VERSION ""

NS_ :

BS_:

BU_: VCM FAS EBS APM

BO_ 1512 WSGW_Chassi_10S: 24 VCM
 SG_ PhyDiagTPM2BrkReqSig_ISig_3 : 0|168@1+ (1,0) [0|0] ""  EBS

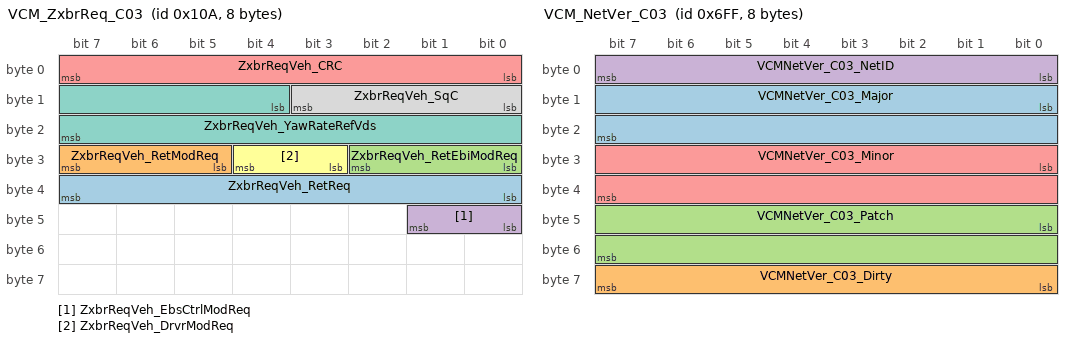
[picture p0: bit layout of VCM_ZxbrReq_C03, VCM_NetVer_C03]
BO_ 266 VCM_ZxbrReq_C03: 8 VCM
 SG_ ZxbrReqVeh_RetReq : 32|8@1+ (0.005,0) [0|1.275] "NotApplicable"  EBS
 SG_ ZxbrReqVeh_RetModReq : 29|3@1+ (1,0) [0|0] ""  EBS
 SG_ ZxbrReqVeh_RetEbiModReq : 24|3@1+ (1,0) [0|0] ""  EBS
 SG_ ZxbrReqVeh_EbsCtrlModReq : 40|2@1+ (1,0) [0|0] ""  EBS
 SG_ ZxbrReqVeh_CRC : 0|8@1+ (1,0) [0|255] ""  EBS
 SG_ ZxbrReqVeh_DrvrModReq : 27|2@1+ (1,0) [0|0] ""  EBS
 SG_ ZxbrReqVeh_YawRateRefVds : 12|12@1+ (0.001,-2) [-2|2.095] "Rad_per_s"  EBS
 SG_ ZxbrReqVeh_SqC : 8|4@1+ (1,0) [0|14] "NotApplicable"  EBS

BO_ 1791 VCM_NetVer_C03: 8 VCM
 SG_ VCMNetVer_C03_Major : 8|16@1+ (1,0) [0|65535] "Not Applicable" Vector__XXX
 SG_ VCMNetVer_C03_Dirty : 56|8@1+ (1,0) [0|255] "NotApplicable" Vector__XXX
 SG_ VCMNetVer_C03_Patch : 40|16@1+ (1,0) [0|65535] "Not Applicable" Vector__XXX
 SG_ VCMNetVer_C03_NetID : 0|8@1+ (1,0) [0|255] "NotApplicable" Vector__XXX
 SG_ VCMNetVer_C03_Minor : 24|16@1+ (1,0) [0|65535] "Not Applicable" Vector__XXX

BO_ 262 VCM_IxbrReqAx456_C03: 48 VCM
 SG_ IxbrReqAxle4_SlipCtrlEna : 41|2@1+ (1,0) [0|0] ""  EBS
 SG_ IxbrReqAxle5_SqC : 120|4@1+ (1,0) [0|14] "NotApplicable"  EBS
 SG_ IxbrReqAxle4_BrkTqReqLe : 43|13@1+ (10,0) [0|81910] "Nm"  EBS
 SG_ IxbrReqAxle4_CRC : 0|8@1+ (1,0) [0|255] ""  EBS
 SG_ IxbrReqAxle5_VehSpdLgtWhlRi : 177|13@1+ (0.01,-40) [-40|41.91] "m_per_s"  EBS
 SG_ IxbrReqAxle6_WhlSlipLimLoLe : 256|9@1+ (0.005,-1) [-1|1.555] "NotApplicable"  EBS
 SG_ IxbrReqAxle5_BrkTqReqRi : 199|13@1+ (10,0) [0|81910] "Nm"  EBS
 SG_ IxbrReqAxle4_BrkTqReqRi : 87|13@1+ (10,0) [0|81910] "Nm"  EBS
 SG_ IxbrReqAxle6_WhlSlipLimHiRi : 324|9@1+ (0.005,-1) [-1|1.555] "NotApplicable"  EBS
 SG_ IxbrReqAxle6_SqC : 232|4@1+ (1,0) [0|14] "NotApplicable"  EBS
 SG_ IxbrReqAxle5_SlipCtrlEna : 153|2@1+ (1,0) [0|0] ""  EBS
 SG_ IxbrReqAxle5_WhlSlipLimLoRi : 190|9@1+ (0.005,-1) [-1|1.555] "NotApplicable"  EBS
 SG_ IxbrReqAxle5_VehSpdLgtWhlLe : 128|13@1+ (0.01,-40) [-40|41.91] "m_per_s"  EBS
 SG_ IxbrReqAxle6_WhlSlipLimLoRi : 302|9@1+ (0.005,-1) [-1|1.555] "NotApplicable"  EBS
 SG_ IxbrReqAxle6_VehSpdLgtWhlRi : 289|13@1+ (0.01,-40) [-40|41.91] "m_per_s"  EBS
 SG_ IxbrReqAxle5_VehSpdLgtWhlQltyLe : 124|2@1+ (1,0) [0|0] ""  EBS
 SG_ IxbrReqAxle6_CRC : 224|8@1+ (1,0) [0|255] ""  EBS
 SG_ IxbrReqAxle5_CRC : 112|8@1+ (1,0) [0|255] ""  EBS
 SG_ IxbrReqAxle4_SqC : 8|4@1+ (1,0) [0|14] "NotApplicable"  EBS
 SG_ IxbrReqAxle4_VehSpdLgtWhlRi : 65|13@1+ (0.01,-40) [-40|41.91] "m_per_s"  EBS
 SG_ IxbrReqAxle4_WhlSlipLimHiLe : 56|9@1+ (0.005,-1) [-1|1.555] "NotApplicable"  EBS
 SG_ IxbrReqAxle4_VehSpdLgtWhlLe : 16|13@1+ (0.01,-40) [-40|41.91] "m_per_s"  EBS
 SG_ IxbrReqAxle4_WhlSlipLimLoLe : 32|9@1+ (0.005,-1) [-1|1.555] "NotApplicable"  EBS
 SG_ IxbrReqAxle6_VehSpdLgtWhlQltyRi : 238|2@1+ (1,0) [0|0] ""  EBS
 SG_ IxbrReqAxle6_BrkTqReqLe : 267|13@1+ (10,0) [0|81910] "Nm"  EBS
 SG_ IxbrReqAxle4_WhlSlipLimLoRi : 78|9@1+ (0.005,-1) [-1|1.555] "NotApplicable"  EBS
 SG_ IxbrReqAxle4_VehSpdLgtWhlQltyRi : 14|2@1+ (1,0) [0|0] ""  EBS
 SG_ IxbrReqAxle4_IxbrModReq : 29|3@1+ (1,0) [0|0] ""  EBS
 SG_ IxbrReqAxle6_BrkTqReqRi : 311|13@1+ (10,0) [0|81910] "Nm"  EBS
 SG_ IxbrReqAxle6_SlipCtrlEna : 265|2@1+ (1,0) [0|0] ""  EBS
 SG_ IxbrReqAxle4_VehSpdLgtWhlQltyLe : 12|2@1+ (1,0) [0|0] ""  EBS
 SG_ IxbrReqAxle6_VehSpdLgtWhlQltyLe : 236|2@1+ (1,0) [0|0] ""  EBS
 SG_ IxbrReqAxle5_BrkTqReqLe : 155|13@1+ (10,0) [0|81910] "Nm"  EBS
 SG_ IxbrReqAxle5_VehSpdLgtWhlQltyRi : 126|2@1+ (1,0) [0|0] ""  EBS
 SG_ IxbrReqAxle5_WhlSlipLimHiRi : 212|9@1+ (0.005,-1) [-1|1.555] "NotApplicable"  EBS
 SG_ IxbrReqAxle5_WhlSlipLimLoLe : 144|9@1+ (0.005,-1) [-1|1.555] "NotApplicable"  EBS
 SG_ IxbrReqAxle5_IxbrModReq : 141|3@1+ (1,0) [0|0] ""  EBS
 SG_ IxbrReqAxle4_WhlSlipLimHiRi : 100|9@1+ (0.005,-1) [-1|1.555] "NotApplicable"  EBS
 SG_ IxbrReqAxle6_IxbrModReq : 253|3@1+ (1,0) [0|0] ""  EBS
 SG_ IxbrReqAxle5_WhlSlipLimHiLe : 168|9@1+ (0.005,-1) [-1|1.555] "NotApplicable"  EBS
 SG_ IxbrReqAxle6_WhlSlipLimHiLe : 280|9@1+ (0.005,-1) [-1|1.555] "NotApplicable"  EBS
 SG_ IxbrReqAxle6_VehSpdLgtWhlLe : 240|13@1+ (0.01,-40) [-40|41.91] "m_per_s"  EBS

BO_ 261 VCM_IxbrReqAx123_C03: 48 VCM
 SG_ IxbrReqAxle3_BrkTqReqLe : 267|13@1+ (10,0) [0|81910] "Nm"  EBS
 SG_ IxbrReqAxle3_WhlSlipLimHiLe : 280|9@1+ (0.005,-1) [-1|1.555] "NotApplicable"  EBS
 SG_ IxbrReqAxle1_BrkTqReqLe : 43|13@1+ (10,0) [0|81910] "Nm"  EBS
 SG_ IxbrReqAxle2_WhlSlipLimHiRi : 212|9@1+ (0.005,-1) [-1|1.555] "NotApplicable"  EBS
 SG_ IxbrReqAxle3_WhlSlipLimLoRi : 302|9@1+ (0.005,-1) [-1|1.555] "NotApplicable"  EBS
 SG_ IxbrReqAxle1_WhlSlipLimLoLe : 32|9@1+ (0.005,-1) [-1|1.555] "NotApplicable"  EBS
 SG_ IxbrReqAxle3_BrkTqReqRi : 311|13@1+ (10,0) [0|81910] "Nm"  EBS
 SG_ IxbrReqAxle2_BrkTqReqLe : 155|13@1+ (10,0) [0|81910] "Nm"  EBS
 SG_ IxbrReqAxle1_VehSpdLgtWhlQltyRi : 14|2@1+ (1,0) [0|0] ""  EBS
 SG_ IxbrReqAxle2_BrkTqReqRi : 199|13@1+ (10,0) [0|81910] "Nm"  EBS
 SG_ IxbrReqAxle1_WhlSlipLimHiLe : 56|9@1+ (0.005,-1) [-1|1.555] "NotApplicable"  EBS
 SG_ IxbrReqAxle1_SlipCtrlEna : 41|2@1+ (1,0) [0|0] ""  EBS
 SG_ IxbrReqAxle1_WhlSlipLimLoRi : 78|9@1+ (0.005,-1) [-1|1.555] "NotApplicable"  EBS
 SG_ IxbrReqAxle2_SlipCtrlEna : 153|2@1+ (1,0) [0|0] ""  EBS
 SG_ IxbrReqAxle1_IxbrModReq : 29|3@1+ (1,0) [0|0] ""  EBS
 SG_ IxbrReqAxle1_SqC : 8|4@1+ (1,0) [0|14] "NotApplicable"  EBS
 SG_ IxbrReqAxle3_VehSpdLgtWhlQltyLe : 236|2@1+ (1,0) [0|0] ""  EBS
 SG_ IxbrReqAxle3_SqC : 232|4@1+ (1,0) [0|14] "NotApplicable"  EBS
 SG_ IxbrReqAxle2_WhlSlipLimLoRi : 190|9@1+ (0.005,-1) [-1|1.555] "NotApplicable"  EBS
 SG_ IxbrReqAxle1_WhlSlipLimHiRi : 100|9@1+ (0.005,-1) [-1|1.555] "NotApplicable"  EBS
 SG_ IxbrReqAxle2_IxbrModReq : 141|3@1+ (1,0) [0|0] ""  EBS
 SG_ IxbrReqAxle3_WhlSlipLimLoLe : 256|9@1+ (0.005,-1) [-1|1.555] "NotApplicable"  EBS
 SG_ IxbrReqAxle2_SqC : 120|4@1+ (1,0) [0|14] "NotApplicable"  EBS
 SG_ IxbrReqAxle1_VehSpdLgtWhlLe : 16|13@1+ (0.01,-40) [-40|41.91] "m_per_s"  EBS
 SG_ IxbrReqAxle3_VehSpdLgtWhlRi : 289|13@1+ (0.01,-40) [-40|41.91] "m_per_s"  EBS
 SG_ IxbrReqAxle3_WhlSlipLimHiRi : 324|9@1+ (0.005,-1) [-1|1.555] "NotApplicable"  EBS
 SG_ IxbrReqAxle2_WhlSlipLimLoLe : 144|9@1+ (0.005,-1) [-1|1.555] "NotApplicable"  EBS
 SG_ IxbrReqAxle2_VehSpdLgtWhlLe : 128|13@1+ (0.01,-40) [-40|41.91] "m_per_s"  EBS
 SG_ IxbrReqAxle2_WhlSlipLimHiLe : 168|9@1+ (0.005,-1) [-1|1.555] "NotApplicable"  EBS
 SG_ IxbrReqAxle3_VehSpdLgtWhlQltyRi : 238|2@1+ (1,0) [0|0] ""  EBS
 SG_ IxbrReqAxle1_VehSpdLgtWhlQltyLe : 12|2@1+ (1,0) [0|0] ""  EBS
 SG_ IxbrReqAxle1_BrkTqReqRi : 87|13@1+ (10,0) [0|81910] "Nm"  EBS
 SG_ IxbrReqAxle1_VehSpdLgtWhlRi : 65|13@1+ (0.01,-40) [-40|41.91] "m_per_s"  EBS
 SG_ IxbrReqAxle3_IxbrModReq : 253|3@1+ (1,0) [0|0] ""  EBS
 SG_ IxbrReqAxle2_CRC : 112|8@1+ (1,0) [0|255] ""  EBS
 SG_ IxbrReqAxle2_VehSpdLgtWhlQltyLe : 124|2@1+ (1,0) [0|0] ""  EBS
 SG_ IxbrReqAxle3_VehSpdLgtWhlLe : 240|13@1+ (0.01,-40) [-40|41.91] "m_per_s"  EBS
 SG_ IxbrReqAxle3_SlipCtrlEna : 265|2@1+ (1,0) [0|0] ""  EBS
 SG_ IxbrReqAxle3_CRC : 224|8@1+ (1,0) [0|255] ""  EBS
 SG_ IxbrReqAxle2_VehSpdLgtWhlRi : 177|13@1+ (0.01,-40) [-40|41.91] "m_per_s"  EBS
 SG_ IxbrReqAxle2_VehSpdLgtWhlQltyRi : 126|2@1+ (1,0) [0|0] ""  EBS
 SG_ IxbrReqAxle1_CRC : 0|8@1+ (1,0) [0|255] ""  EBS

BO_ 554 VCM_EstAxles_C03: 48 VCM
 SG_ EstAxle3_LoadNormLe : 128|8@1+ (800,0) [0|204000] "N"  EBS
 SG_ EstAxle6_WhlRdEstQltyRi : 294|2@1+ (1,0) [0|0] ""  EBS
 SG_ EstAxle5_WhlRdEstQltyRi : 238|2@1+ (1,0) [0|0] ""  EBS
 SG_ EstAxle2_LoadNormQltyLe : 108|2@1+ (1,0) [0|0] ""  EBS
 SG_ EstAxle3_LoadNormQltyRi : 166|2@1+ (1,0) [0|0] ""  EBS
 SG_ EstAxle6_SqC : 288|4@1+ (1,0) [0|14] "NotApplicable"  EBS
 SG_ EstAxle4_LoadNormQltyRi : 222|2@1+ (1,0) [0|0] ""  EBS
 SG_ EstAxle6_LoadNormRi : 304|8@1+ (800,0) [0|204000] "N"  EBS
 SG_ EstAxle5_SqC : 232|4@1+ (1,0) [0|14] "NotApplicable"  EBS
 SG_ EstAxle6_CRC : 280|8@1+ (1,0) [0|255] ""  EBS
 SG_ EstAxle2_WhlRdEstLe : 88|10@1+ (0.001,0.35) [0.35|1.373] "m"  EBS
 SG_ EstAxle3_WhlRdEstRi : 154|10@1+ (0.001,0.35) [0.35|1.373] "m"  EBS
 SG_ EstAxle5_LoadNormQltyRi : 278|2@1+ (1,0) [0|0] ""  EBS
 SG_ EstAxle6_WhlRdEstLe : 312|10@1+ (0.001,0.35) [0.35|1.373] "m"  EBS
 SG_ EstAxle6_WhlRdEstQltyLe : 292|2@1+ (1,0) [0|0] ""  EBS
 SG_ EstAxle6_LoadNormLe : 296|8@1+ (800,0) [0|204000] "N"  EBS
 SG_ EstAxle5_LoadNormRi : 248|8@1+ (800,0) [0|204000] "N"  EBS
 SG_ EstAxle5_LoadNormQltyLe : 276|2@1+ (1,0) [0|0] ""  EBS
 SG_ EstAxle5_CRC : 224|8@1+ (1,0) [0|255] ""  EBS
 SG_ EstAxle1_WhlRdEstRi : 42|10@1+ (0.001,0.35) [0.35|1.373] "m"  EBS
 SG_ EstAxle4_LoadNormRi : 192|8@1+ (800,0) [0|204000] "N"  EBS
 SG_ EstAxle3_WhlRdEstQltyLe : 124|2@1+ (1,0) [0|0] ""  EBS
 SG_ EstAxle4_WhlRdEstRi : 210|10@1+ (0.001,0.35) [0.35|1.373] "m"  EBS
 SG_ EstAxle6_WhlRdEstRi : 322|10@1+ (0.001,0.35) [0.35|1.373] "m"  EBS
 SG_ EstAxle5_LoadNormLe : 240|8@1+ (800,0) [0|204000] "N"  EBS
 SG_ EstAxle5_WhlRdEstLe : 256|10@1+ (0.001,0.35) [0.35|1.373] "m"  EBS
 SG_ EstAxle3_CRC : 112|8@1+ (1,0) [0|255] ""  EBS
 SG_ EstAxle2_LoadNormRi : 80|8@1+ (800,0) [0|204000] "N"  EBS
 SG_ EstAxle4_SqC : 176|4@1+ (1,0) [0|14] "NotApplicable"  EBS
 SG_ EstAxle4_WhlRdEstQltyRi : 182|2@1+ (1,0) [0|0] ""  EBS
 SG_ EstAxle6_LoadNormQltyRi : 334|2@1+ (1,0) [0|0] ""  EBS
 SG_ EstAxle1_LoadNormQltyRi : 54|2@1+ (1,0) [0|0] ""  EBS
 SG_ EstAxle1_LoadNormQltyLe : 52|2@1+ (1,0) [0|0] ""  EBS
 SG_ EstAxle2_LoadNormLe : 72|8@1+ (800,0) [0|204000] "N"  EBS
 SG_ EstAxle4_WhlRdEstQltyLe : 180|2@1+ (1,0) [0|0] ""  EBS
 SG_ EstAxle4_WhlRdEstLe : 200|10@1+ (0.001,0.35) [0.35|1.373] "m"  EBS
 SG_ EstAxle1_WhlRdEstQltyLe : 12|2@1+ (1,0) [0|0] ""  EBS
 SG_ EstAxle2_LoadNormQltyRi : 110|2@1+ (1,0) [0|0] ""  EBS
 SG_ EstAxle3_LoadNormQltyLe : 164|2@1+ (1,0) [0|0] ""  EBS
 SG_ EstAxle4_LoadNormQltyLe : 220|2@1+ (1,0) [0|0] ""  EBS
 SG_ EstAxle2_WhlRdEstQltyRi : 70|2@1+ (1,0) [0|0] ""  EBS
 SG_ EstAxle6_LoadNormQltyLe : 332|2@1+ (1,0) [0|0] ""  EBS
 SG_ EstAxle2_WhlRdEstRi : 98|10@1+ (0.001,0.35) [0.35|1.373] "m"  EBS
 SG_ EstAxle3_WhlRdEstQltyRi : 126|2@1+ (1,0) [0|0] ""  EBS
 SG_ EstAxle1_LoadNormLe : 16|8@1+ (800,0) [0|204000] "N"  EBS
 SG_ EstAxle1_CRC : 0|8@1+ (1,0) [0|255] ""  EBS
 SG_ EstAxle5_WhlRdEstRi : 266|10@1+ (0.001,0.35) [0.35|1.373] "m"  EBS
 SG_ EstAxle2_CRC : 56|8@1+ (1,0) [0|255] ""  EBS
 SG_ EstAxle1_LoadNormRi : 24|8@1+ (800,0) [0|204000] "N"  EBS
 SG_ EstAxle2_WhlRdEstQltyLe : 68|2@1+ (1,0) [0|0] ""  EBS
 SG_ EstAxle4_CRC : 168|8@1+ (1,0) [0|255] ""  EBS
 SG_ EstAxle3_LoadNormRi : 136|8@1+ (800,0) [0|204000] "N"  EBS
 SG_ EstAxle5_WhlRdEstQltyLe : 236|2@1+ (1,0) [0|0] ""  EBS
 SG_ EstAxle3_SqC : 120|4@1+ (1,0) [0|14] "NotApplicable"  EBS
 SG_ EstAxle1_WhlRdEstLe : 32|10@1+ (0.001,0.35) [0.35|1.373] "m"  EBS
 SG_ EstAxle4_LoadNormLe : 184|8@1+ (800,0) [0|204000] "N"  EBS
 SG_ EstAxle1_SqC : 8|4@1+ (1,0) [0|14] "NotApplicable"  EBS
 SG_ EstAxle1_WhlRdEstQltyRi : 14|2@1+ (1,0) [0|0] ""  EBS
 SG_ EstAxle2_SqC : 64|4@1+ (1,0) [0|14] "NotApplicable"  EBS
 SG_ EstAxle3_WhlRdEstLe : 144|10@1+ (0.001,0.35) [0.35|1.373] "m"  EBS

BO_ 631 VCM_07P_C03: 24 VCM
 SG_ TrsmEngdForPropulsion_SqC : 144|4@1+ (1,0) [0|14] "NotApplicable"  APM
 SG_ TrsmEngdForPropulsion_Status : 148|3@1+ (1,0) [0|0] ""  APM
 SG_ XPRGReqPropDemTc_SqC : 120|4@1+ (1,0) [0|14] "NotApplicable"  APM
 SG_ TrsmEngdForPropulsion_CRC : 136|8@1+ (1,0) [0|255] ""  APM
 SG_ XPRGReqPropDemTl_TlPropControl : 80|7@1+ (1,0) [0|127] "NotApplicable"  APM
 SG_ XPRGReqMain_AddVlvRelIhnibition : 101|1@1+ (1,0) [0|0] ""  APM
 SG_ XPRGReqMain_PBValveCtrl : 108|3@1+ (1,0) [0|0] ""  APM
 SG_ DriverLocation_Status_ISig_3 : 12|4@1+ (1,0) [0|0] ""  APM
 SG_ TachographVehicleSpeed : 48|16@1+ (0.00390625,0) [0|255.99609375] "Km_per_h"  APM
 SG_ XPRsystemstate : 24|8@1+ (1,0) [0|255] "NotApplicable"  EBS
 SG_ XPRGReqMain_AddValveCtrlMode : 104|1@1+ (1,0) [0|0] ""  APM
 SG_ XPRGReqMain_CRC : 88|8@1+ (1,0) [0|255] ""  APM
 SG_ XPRGReqMain_AddValveCtrl : 105|3@1+ (1,0) [0|0] ""  APM
 SG_ BacklightCmd_ISig_3 : 34|5@1+ (1,0) [0|0] ""  APM
 SG_ XPRGReqPropDemTl_SqC : 72|4@1+ (1,0) [0|14] "NotApplicable"  APM
 SG_ DoorsAjar_stat_ISig_3 : 43|3@1+ (1,0) [0|0] ""  APM
 SG_ XPRGReqPropDemTl_CRC : 64|8@1+ (1,0) [0|255] ""  APM
 SG_ XPRGReqMain_SqC : 96|4@1+ (1,0) [0|14] "NotApplicable"  APM
 SG_ XPRGReqPropDemTc_TypeControl : 124|2@1+ (1,0) [0|0] ""  APM
 SG_ CartridgeChangedDrvrReset_rqst_I : 46|2@1+ (1,0) [0|0] ""  APM
 SG_ DriverLocation_ConfidenceLvl_ISi : 16|2@1+ (1,0) [0|0] ""  APM
 SG_ DriverLocation_CRC_ISig_3 : 0|8@1+ (1,0) [0|255] ""  APM
 SG_ XPRGReqPropDemTl_TypeControl : 76|2@1+ (1,0) [0|0] ""  APM
 SG_ XPRGReqMain_RequestPriority : 102|2@1+ (1,0) [0|0] ""  APM
 SG_ XPRGReqPropDemTc_CRC : 112|8@1+ (1,0) [0|255] ""  APM
 SG_ FuncIndIlluminationLevel_ISig_3 : 40|3@1+ (1,0) [0|0] ""  APM
 SG_ TrailerABSStatus_ISig_3 : 32|2@1+ (1,0) [0|0] ""  EBS
 SG_ DriverLocation_SqC_ISig_3 : 8|4@1+ (1,0) [0|14] "NotApplicable"  APM
 SG_ XPRGReqMain_PBVlvRelInhibition : 100|1@1+ (1,0) [0|0] ""  APM
 SG_ XPRGReqPropDemTc_TcPropControl : 128|7@1+ (1,0) [0|127] "NotApplicable"  APM

BO_ 1448 VCM_06P_C03: 8 VCM
 SG_ TotalVehicleDistanceHighRes_ISig : 0|32@1+ (5,0) [0|21474836475] "m"  FAS,APM
 SG_ AmbientAirTemperature_ISig_3 : 32|16@1+ (0.03125,-273) [-273|1774.96875] "DegreeC"  FAS,APM

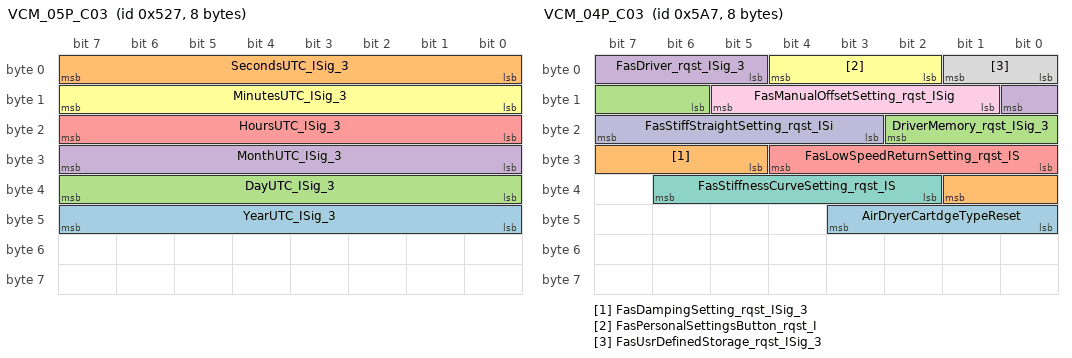
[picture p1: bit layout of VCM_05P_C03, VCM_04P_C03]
BO_ 1319 VCM_05P_C03: 8 VCM
 SG_ YearUTC_ISig_3 : 40|8@1+ (1,1985) [1985|2240] "Years"  FAS,APM
 SG_ SecondsUTC_ISig_3 : 0|8@1+ (0.25,0) [0|63.75] "s"  FAS,APM
 SG_ DayUTC_ISig_3 : 32|8@1+ (0.25,0) [0|63.75] "Days"  FAS,APM
 SG_ MonthUTC_ISig_3 : 24|8@1+ (1,0) [0|255] "Months"  APM,FAS
 SG_ HoursUTC_ISig_3 : 16|8@1+ (1,0) [0|255] "h"  APM,FAS
 SG_ MinutesUTC_ISig_3 : 8|8@1+ (1,0) [0|255] "min"  APM,FAS

BO_ 1447 VCM_04P_C03: 8 VCM
 SG_ AirDryerCartdgeTypeReset : 40|4@1+ (1,0) [0|0] ""  APM
 SG_ FasDampingSetting_rqst_ISig_3 : 29|5@1+ (1,-10) [-10|21] ""  FAS
 SG_ DriverMemory_rqst_ISig_3 : 14|5@1+ (1,0) [0|0] ""  FAS
 SG_ FasDriver_rqst_ISig_3 : 5|4@1+ (1,0) [0|0] ""  FAS
 SG_ FasLowSpeedReturnSetting_rqst_IS : 24|5@1+ (1,-10) [-10|21] ""  FAS
 SG_ FasPersonalSettingsButton_rqst_I : 2|3@1+ (1,0) [0|0] ""  FAS
 SG_ FasStiffnessCurveSetting_rqst_IS : 34|5@1+ (1,-10) [-10|21] ""  FAS
 SG_ FasUsrDefinedStorage_rqst_ISig_3 : 0|2@1+ (1,0) [0|0] ""  FAS
 SG_ FasManualOffsetSetting_rqst_ISig : 9|5@1+ (1,-10) [-10|21] ""  FAS
 SG_ FasStiffStraightSetting_rqst_ISi : 19|5@1+ (1,-10) [-10|21] ""  FAS

BO_ 1034 VCM_03P_C03: 32 VCM
 SG_ RelativeLevelFrontAxleRight_ISig : 144|16@1+ (0.1,-3200) [-3200|3353.5] "mm"  EBS
 SG_ RelativeLevelFrontAxleLeft_ISig_ : 96|16@1+ (0.1,-3200) [-3200|3353.5] "mm"  FAS,EBS
 SG_ FrontAxle1Load_ISig_3 : 0|16@1+ (0.5,0) [0|32767.5] "kg"  FAS,EBS
 SG_ PusherAxleLoad_ISig_3 : 64|16@1+ (0.5,0) [0|32767.5] "kg"  FAS,EBS
 SG_ AirConsumptionStatus : 140|2@1+ (1,0) [0|0] ""  APM
 SG_ UnloadValveOperationRqst : 142|2@1+ (1,0) [0|0] ""  APM
 SG_ SecondaryDriveAxleLoad_ISig_3 : 48|16@1+ (0.5,0) [0|32767.5] "kg"  FAS,EBS
 SG_ RelativeLevelRearAxleLeft_ISig_3 : 160|16@1+ (0.1,-3200) [-3200|3353.5] "mm"  EBS
 SG_ TagAxleLoad_ISig_3 : 80|16@1+ (0.5,0) [0|32767.5] "kg"  FAS,EBS
 SG_ TransmissionCurrentGear_ISig_3 : 208|8@1+ (1,-125) [-125|130] "GearValue"  APM
 SG_ ContTrailerBrake_MsgCounter : 136|4@1+ (1,0) [0|15] "Count"  EBS
 SG_ AirProductionPressureRangeMode : 192|4@1+ (1,0) [0|0] ""  APM
 SG_ BrakeSwitch_ISig_3 : 216|2@1+ (1,0) [0|0] ""  APM
 SG_ FrontAxle2Load_ISig_3 : 16|16@1+ (0.5,0) [0|32767.5] "kg"  FAS,EBS
 SG_ DriveAxleLoad_ISig_3 : 32|16@1+ (0.5,0) [0|32767.5] "kg"  EBS,FAS
 SG_ ContTrailerBrake_MsgChecksum : 131|5@1+ (1,0) [0|31] ""  EBS
 SG_ TertiaryDriveAxleLoad_ISig_3 : 112|16@1+ (0.5,0) [0|32767.5] "kg"  EBS
 SG_ ElAirCompActualSpeed : 200|8@1+ (20,0) [0|5100] "rpm"  APM
 SG_ ElAirCompOperationStat : 196|3@1+ (1,0) [0|0] ""  APM
 SG_ VIN_rqst_ISig_3 : 199|1@1+ (1,0) [0|0] ""  APM
 SG_ TrailerConnected_ISig_3 : 218|2@1+ (1,0) [0|0] ""  APM
 SG_ ContTrailerBrake_Request : 128|3@1+ (1,0) [0|0] ""  EBS
 SG_ RelativeLevelRearAxleRight_ISig_ : 176|16@1+ (0.1,-3200) [-3200|3353.5] "mm"  EBS

BO_ 426 VCM_02P_C03: 32 VCM
 SG_ ChangeKneelACK_ISig_3 : 126|2@1+ (1,0) [0|0] ""  EBS
 SG_ EngineSpeed_ISig_3 : 176|16@1+ (0.125,0) [0|8191.875] "rpm"  APM
 SG_ SecuredNeutralPosition_ISig_3 : 165|2@1+ (1,0) [0|0] ""  EBS,APM
 SG_ LiftAxle1PositionStatus_ISig_3 : 112|3@1+ (1,0) [0|0] ""  EBS
 SG_ FrontFerryFunctionCmd_ISig_3 : 128|3@1+ (1,0) [0|0] ""  EBS
 SG_ ReverseGearEngaged_ISig_3 : 22|2@1+ (1,0) [0|0] ""  FAS
 SG_ AirDumpStatus_ISig_3 : 104|3@1+ (1,0) [0|0] ""  EBS
 SG_ EngineActiveStatus_ISig_3 : 16|4@1+ (1,0) [0|0] ""  FAS,APM
 SG_ FerryFunctionStatus_ISig_3 : 107|3@1+ (1,0) [0|0] ""  EBS
 SG_ PitchAngleRef_ISig_3 : 56|16@1+ (0.001,-30) [-30|35.535] "deg"  EBS
 SG_ KneelingInformation_ISig_3 : 80|4@1+ (1,0) [0|0] ""  EBS
 SG_ FASHapticFeedbackRequest : 28|4@1+ (1,0) [0|0] ""  FAS
 SG_ HeightControlMode_ISig_3 : 84|4@1+ (1,0) [0|0] ""  EBS
 SG_ LoadDistributionFuncSelected_ISi : 92|4@1+ (1,0) [0|0] ""  EBS
 SG_ PitchAngle_ISig_3 : 40|16@1+ (0.001,-30) [-30|35.535] "deg"  EBS
 SG_ RollEndPositionStatus_ISig_3 : 123|3@1+ (1,0) [0|0] ""  EBS
 SG_ SupplyPressure_ISig_3 : 72|8@1+ (8,0) [0|2040] "kPa"  EBS
 SG_ WheelBasedVehicleSpeed_ISig_3 : 0|16@1+ (0.00390625,0) [0|255.99609375] "Km_per_h"  FAS,APM
 SG_ XBRSystemState2_Status : 212|2@1+ (1,0) [0|0] ""  APM
 SG_ RearAxle2DiffLock_stat_ISig_3 : 142|2@1+ (1,0) [0|0] ""  EBS
 SG_ KneelingStatusHMI_ISig_3 : 134|2@1+ (1,0) [0|0] ""  EBS
 SG_ HeightAdjustmentAllowed_ISig_3 : 110|2@1+ (1,0) [0|0] ""  EBS
 SG_ RideHeightStatus_ISig_3 : 100|4@1+ (1,0) [0|0] ""  EBS
 SG_ CentralRearDiffLock_stat_ISig_3 : 136|2@1+ (1,0) [0|0] ""  EBS
 SG_ XBRSystemState2_CRC : 200|8@1+ (1,0) [0|255] ""  APM
 SG_ LiftAxle2PositionStatus_ISig_3 : 115|3@1+ (1,0) [0|0] ""  EBS
 SG_ RampHeightOutsideTargetRange_ISi : 131|3@1+ (1,0) [0|0] ""  EBS
 SG_ DirInd_Rear_Status_ISig_3 : 160|3@1+ (1,0) [0|0] ""  EBS
 SG_ ExternalRequestManualStiffness : 32|4@1+ (0.1,0) [0|1.5] "NotApplicable"  FAS
 SG_ PneumaticTrailerBrakeStatus_ISig : 171|2@1+ (1,0) [0|0] ""  EBS
 SG_ GearLeverPosition_ISig_3 : 196|4@1+ (1,0) [0|0] ""  APM
 SG_ VehicleDistanceRollingCounter : 144|16@1+ (0.03125,0) [0|2047.96875] "m"  EBS
 SG_ BackToDriveReqACK_ISig_3 : 118|2@1+ (1,0) [0|0] ""  EBS
 SG_ XBRSystemState2_SqC : 208|4@1+ (1,0) [0|14] "NotApplicable"  APM
 SG_ ExtraAxleSteeringFunctionStat : 168|3@1+ (1,0) [0|0] ""  EBS
 SG_ RearAxle1DiffLock_stat_ISig_3 : 140|2@1+ (1,0) [0|0] ""  EBS
 SG_ LevelControlInformation_ISig_3 : 88|4@1+ (1,0) [0|0] ""  EBS
 SG_ VehicleMode_ISig_3 : 36|4@1+ (1,0) [0|0] ""  APM,FAS
 SG_ ACC_SGO_Status_ISig_3 : 24|4@1+ (1,0) [0|0] ""  FAS
 SG_ RearEndPositionStatus_ISig_3 : 120|3@1+ (1,0) [0|0] ""  EBS
 SG_ PBAlertActiveStatus_ISig_3 : 173|3@1+ (1,0) [0|0] ""  APM
 SG_ ECSShutdownCmd_ISig_3 : 138|2@1+ (1,0) [0|0] ""  EBS
 SG_ VehicleDynamicSuspProhibitStat_I : 163|2@1+ (1,0) [0|0] ""  EBS
 SG_ RideHeightFunctionStatus_ISig_3 : 96|4@1+ (1,0) [0|0] ""  EBS

BO_ 268 VCM_01P_C03: 16 VCM
 SG_ BrakePedalPosition_ISig_3 : 80|8@1+ (0.4,0) [0|102] "Percent"  APM
 SG_ RoadWheelAngle_Request : 16|16@1+ (5E-005,-1.6) [-1.6|1.67675] "rad"  FAS
 SG_ AcceleratorPedalQuality_ISig_3 : 74|2@1+ (1,0) [0|0] ""  APM
 SG_ RoadWheelAngle_RateRequest : 32|16@1+ (5E-005,-1.6) [-1.6|1.67675] "Rad_per_s"  FAS
 SG_ AcceleratorPedalStatus : 76|3@1+ (1,0) [0|0] ""  APM
 SG_ SteeringControlMode_CRC : 48|8@1+ (1,0) [0|255] ""  FAS
 SG_ SteeringControlMode_Activate : 62|2@1+ (1,0) [0|0] ""  FAS
 SG_ RoadWheelAngle_CRC : 0|8@1+ (1,0) [0|255] ""  FAS
 SG_ AcceleratorPedalPosition1_ISig_3 : 64|8@1+ (0.4,0) [0|102] "Percent"  APM
 SG_ RoadWheelAngle_SqC : 8|4@1+ (1,0) [0|14] "NotApplicable"  FAS
 SG_ AcceleratorPedalLowIdleSwitch_IS : 72|2@1+ (1,0) [0|0] ""  APM
 SG_ SteeringControlMode_SqC : 56|4@1+ (1,0) [0|14] "NotApplicable"  FAS
 SG_ SteeringControlMode_Request : 60|2@1+ (1,0) [0|0] ""  FAS

CM_ "COM_MATRIX_T3_2.3.0";
CM_ BU_ VCM "Vehicle Control Module";
CM_ BU_ FAS "Front Active Steering";
CM_ BU_ EBS "Electronic Braking System";
CM_ BU_ APM "Air Pressure Management";
BA_DEF_ BO_  "GenMsgStartDelayTime" INT 0 0;
BA_DEF_ BO_  "GenMsgDelayTime" INT 0 0;
BA_DEF_ BO_  "GenMsgCycleTime" INT 0 0;
BA_DEF_ BO_  "GenMsgSendType" ENUM  "Cyclic","NotUsed","NotUsed","NotUsed","NotUsed","NotUsed","NotUsed","IfActive","NoMsgSendType","NotUsed";
BA_DEF_ SG_  "GenSigStartValue" INT 0 0;
BA_DEF_ SG_  "GenSigCycleTimeActive" INT 0 0;
BA_DEF_ SG_  "GenSigCycleTime" INT 0 0;
BA_DEF_ SG_  "GenSigSendType" ENUM  "Cyclic","OnWrite","OnWriteWithRepetition","OnChange","OnChangeWithRepetition","IfActive","IfActiveWithRepetition","NoSigSendType","NotUsed","NotUsed","NotUsed","NotUsed","NotUsed";
BA_DEF_  "Baudrate" INT 0 1000000;
BA_DEF_  "NmType" STRING ;
BA_DEF_  "Manufacturer" STRING ;
BA_DEF_  "VersionYear" INT 0 99;
BA_DEF_  "VersionNumber" INT 0 99;
BA_DEF_  "VersionMonth" INT 1 12;
BA_DEF_  "VersionDay" INT 1 31;
BA_DEF_ BO_  "VFrameFormat" ENUM  "StandardCAN","ExtendedCAN","reserved","J1939PG","reserved","reserved","reserved","reserved","reserved","reserved","reserved","reserved","reserved","reserved","StandardCAN_FD","ExtendedCAN_FD";
BA_DEF_ BU_  "TpOwnSystemEcuNumber" HEX 0 255;
BA_DEF_ SG_  "SigType" ENUM  "Default","Range","RangeSigned","ASCII","Discrete","Control","ReferencePGN","DTC","StringDelimiter","StringLength","StringLengthControl";
BA_DEF_ BU_  "NmStationAddress" INT 0 255;
BA_DEF_  "NmAsrWaitBusSleepTime" INT 0 65535;
BA_DEF_  "NmAsrTimeoutTime" INT 0 65535;
BA_DEF_  "NmAsrRepeatMessageTime" INT 0 65535;
BA_DEF_ BU_  "NmAsrNodeIdentifier" HEX 0 253;
BA_DEF_ BU_  "NmAsrNode" ENUM  "No","Yes";
BA_DEF_  "NmAsrMessageCount" INT 1 256;
BA_DEF_ BO_  "NmAsrMessage" ENUM  "No","Yes";
BA_DEF_  "NmAsrCanMsgCycleTime" INT 0 65535;
BA_DEF_  "NmAsrBaseAddress" HEX 0 536870911;
BA_DEF_ SG_  "NeedsUpdateBit" ENUM  "No","Yes";
BA_DEF_ SG_  "MmAnSignal" ENUM  "No","Yes";
BA_DEF_ BU_  "IsOBDrelevant" ENUM  "No","Yes";
BA_DEF_ SG_  "GenSigMaxLatency" INT 0 65535;
BA_DEF_ SG_  "GenSigILSupport" ENUM  "Yes","No";
BA_DEF_ BO_  "GenMsgILSupport" ENUM  "No","Yes";
BA_DEF_ SG_  "E2EProfile" STRING ;
BA_DEF_  "E2EP05WindowSize" INT 0 65535;
BA_DEF_  "E2EP05ProfileName" STRING ;
BA_DEF_  "E2EP05MinOkStateValid" INT 0 65535;
BA_DEF_  "E2EP05MinOkStateInvalid" INT 0 65535;
BA_DEF_  "E2EP05MinOkStateInit" INT 0 65535;
BA_DEF_  "E2EP05MaxErrorStateValid" INT 0 65535;
BA_DEF_  "E2EP05MaxErrorStateInvalid" INT 0 65535;
BA_DEF_  "E2EP05MaxErrorStateInit" INT 0 65535;
BA_DEF_  "E2EP05MaxDeltaCounter" INT 0 65535;
BA_DEF_  "E2EP01WindowSize" INT 0 65535;
BA_DEF_  "E2EP01SyncCounterInit" INT 0 65535;
BA_DEF_  "E2EP01ProfileName" STRING ;
BA_DEF_  "E2EP01MinOkStateValid" INT 0 65535;
BA_DEF_  "E2EP01MinOkStateInvalid" INT 0 65535;
BA_DEF_  "E2EP01MinOkStateInit" INT 0 65535;
BA_DEF_  "E2EP01MaxNoNewOrRepeatedData" INT 0 65535;
BA_DEF_  "E2EP01MaxErrorStateValid" INT 0 65535;
BA_DEF_  "E2EP01MaxErrorStateInvalid" INT 0 65535;
BA_DEF_  "E2EP01MaxErrorStateInit" INT 0 65535;
BA_DEF_  "E2EP01MaxDeltaCounter" INT 0 65535;
BA_DEF_  "E2EP01DataIdMode" ENUM  "all16Bit","alternating8Bit","lower12Bit","lower8Bit";
BA_DEF_  "E2EP01CounterOffset" INT 0 65535;
BA_DEF_ SG_  "E2EDataLength" INT 0 65535;
BA_DEF_ SG_  "E2EDataId" INT 0 65535;
BA_DEF_ BU_  "DiagnosticClientAddress" HEX 0 255;
BA_DEF_ BO_  "DiagUUDTResponse" ENUM  "No","Yes";
BA_DEF_ BO_  "DiagState" ENUM  "No","Yes";
BA_DEF_ BU_  "DiagRole" ENUM  "None","OBDTester","ExternalTester","InternalTester";
BA_DEF_ BO_  "DiagResponse" ENUM  "No","Yes";
BA_DEF_ BO_  "DiagRequest" ENUM  "No","Yes";
BA_DEF_ BO_  "DiagConnection" HEX 0 65535;
BA_DEF_  "DBName" STRING ;
BA_DEF_ BO_  "CanTpFcFrameId" HEX 0 2147483647;
BA_DEF_ BO_  "CanTpBs" INT 0 255;
BA_DEF_ BO_  "CANFD_BRS" ENUM  "0","1";
BA_DEF_  "BusType" STRING ;
BA_DEF_  "BaudrateCANFD" INT 0 5000000;
BA_DEF_ SG_  "SystemSignalLongSymbol" STRING ;
BA_DEF_REL_ BU_SG_REL_  "GenSigTimeoutTime" INT 0 65535;
BA_DEF_REL_ BU_SG_REL_  "GenSigFirstTimeoutTime" INT 0 65535;
BA_DEF_DEF_  "GenMsgStartDelayTime" 0;
BA_DEF_DEF_  "GenMsgDelayTime" 0;
BA_DEF_DEF_  "GenMsgCycleTime" 0;
BA_DEF_DEF_  "GenMsgSendType" "Cyclic";
BA_DEF_DEF_  "GenSigStartValue" 0;
BA_DEF_DEF_  "GenSigCycleTimeActive" 0;
BA_DEF_DEF_  "GenSigCycleTime" 0;
BA_DEF_DEF_  "GenSigSendType" "Cyclic";
BA_DEF_DEF_  "Baudrate" 500000;
BA_DEF_DEF_  "NmType" "";
BA_DEF_DEF_  "Manufacturer" "VOLVO_AB";
BA_DEF_DEF_  "VersionYear" 0;
BA_DEF_DEF_  "VersionNumber" 0;
BA_DEF_DEF_  "VersionMonth" 1;
BA_DEF_DEF_  "VersionDay" 1;
BA_DEF_DEF_  "VFrameFormat" "ExtendedCAN";
BA_DEF_DEF_  "TpOwnSystemEcuNumber" 0;
BA_DEF_DEF_  "SigType" "Default";
BA_DEF_DEF_  "NmStationAddress" 254;
BA_DEF_DEF_  "NmAsrWaitBusSleepTime" 750;
BA_DEF_DEF_  "NmAsrTimeoutTime" 5000;
BA_DEF_DEF_  "NmAsrRepeatMessageTime" 300;
BA_DEF_DEF_  "NmAsrNodeIdentifier" 0;
BA_DEF_DEF_  "NmAsrNode" "Yes";
BA_DEF_DEF_  "NmAsrMessageCount" 256;
BA_DEF_DEF_  "NmAsrMessage" "No";
BA_DEF_DEF_  "NmAsrCanMsgCycleTime" 200;
BA_DEF_DEF_  "NmAsrBaseAddress" 486506496;
BA_DEF_DEF_  "NeedsUpdateBit" "No";
BA_DEF_DEF_  "MmAnSignal" "No";
BA_DEF_DEF_  "IsOBDrelevant" "No";
BA_DEF_DEF_  "GenSigMaxLatency" 0;
BA_DEF_DEF_  "GenSigILSupport" "Yes";
BA_DEF_DEF_  "GenMsgILSupport" "Yes";
BA_DEF_DEF_  "E2EProfile" "none";
BA_DEF_DEF_  "E2EP05WindowSize" 5;
BA_DEF_DEF_  "E2EP05ProfileName" "PROFILE_05";
BA_DEF_DEF_  "E2EP05MinOkStateValid" 1;
BA_DEF_DEF_  "E2EP05MinOkStateInvalid" 3;
BA_DEF_DEF_  "E2EP05MinOkStateInit" 1;
BA_DEF_DEF_  "E2EP05MaxErrorStateValid" 3;
BA_DEF_DEF_  "E2EP05MaxErrorStateInvalid" 1;
BA_DEF_DEF_  "E2EP05MaxErrorStateInit" 2;
BA_DEF_DEF_  "E2EP05MaxDeltaCounter" 3;
BA_DEF_DEF_  "E2EP01WindowSize" 5;
BA_DEF_DEF_  "E2EP01SyncCounterInit" 1;
BA_DEF_DEF_  "E2EP01ProfileName" "PROFILE_01";
BA_DEF_DEF_  "E2EP01MinOkStateValid" 1;
BA_DEF_DEF_  "E2EP01MinOkStateInvalid" 3;
BA_DEF_DEF_  "E2EP01MinOkStateInit" 1;
BA_DEF_DEF_  "E2EP01MaxNoNewOrRepeatedData" 5;
BA_DEF_DEF_  "E2EP01MaxErrorStateValid" 3;
BA_DEF_DEF_  "E2EP01MaxErrorStateInvalid" 1;
BA_DEF_DEF_  "E2EP01MaxErrorStateInit" 2;
BA_DEF_DEF_  "E2EP01MaxDeltaCounter" 3;
BA_DEF_DEF_  "E2EP01DataIdMode" "all16Bit";
BA_DEF_DEF_  "E2EP01CounterOffset" 8;
BA_DEF_DEF_  "E2EDataLength" 0;
BA_DEF_DEF_  "E2EDataId" 0;
BA_DEF_DEF_  "DiagnosticClientAddress" 0;
BA_DEF_DEF_  "DiagUUDTResponse" "No";
BA_DEF_DEF_  "DiagState" "No";
BA_DEF_DEF_  "DiagRole" "None";
BA_DEF_DEF_  "DiagResponse" "No";
BA_DEF_DEF_  "DiagRequest" "No";
BA_DEF_DEF_  "DiagConnection" 0;
BA_DEF_DEF_  "DBName" "";
BA_DEF_DEF_  "CanTpFcFrameId" 2147483647;
BA_DEF_DEF_  "CanTpBs" 255;
BA_DEF_DEF_  "CANFD_BRS" "0";
BA_DEF_DEF_  "BusType" "";
BA_DEF_DEF_  "BaudrateCANFD" 0;
BA_DEF_DEF_REL_ "GenSigTimeoutTime" 0;
BA_DEF_DEF_REL_ "GenSigFirstTimeoutTime" 0;
BA_DEF_DEF_  "SystemSignalLongSymbol" "";
BA_ "NmType" "NmAsr";
BA_ "BusType" "CAN FD";
BA_ "BaudrateCANFD" 1000000;
BA_ "VersionDay" 27;
BA_ "VersionMonth" 2;
BA_ "VersionNumber" 1;
BA_ "VersionYear" 23;
BA_ "DBName" "CAN03";
BA_ "DiagRole" BU_ VCM 3;
BA_ "DiagnosticClientAddress" BU_ VCM 244;
BA_ "IsOBDrelevant" BU_ VCM 1;
BA_ "TpOwnSystemEcuNumber" BU_ VCM 36;
BA_ "NmAsrNodeIdentifier" BU_ VCM 36;
BA_ "TpOwnSystemEcuNumber" BU_ FAS 48;
BA_ "NmAsrNodeIdentifier" BU_ FAS 48;
BA_ "TpOwnSystemEcuNumber" BU_ EBS 40;
BA_ "NmAsrNodeIdentifier" BU_ EBS 40;
BA_ "TpOwnSystemEcuNumber" BU_ APM 35;
BA_ "NmAsrNodeIdentifier" BU_ APM 35;
BA_ "CANFD_BRS" BO_ 1512 1;
BA_ "GenMsgSendType" BO_ 1512 8;
BA_ "VFrameFormat" BO_ 1512 14;
BA_ "CANFD_BRS" BO_ 266 1;
BA_ "GenMsgCycleTime" BO_ 266 10;
BA_ "VFrameFormat" BO_ 266 14;
BA_ "VFrameFormat" BO_ 1791 0;
BA_ "GenMsgCycleTime" BO_ 1791 1000;
BA_ "CANFD_BRS" BO_ 262 1;
BA_ "GenMsgCycleTime" BO_ 262 10;
BA_ "GenMsgStartDelayTime" BO_ 262 5;
BA_ "VFrameFormat" BO_ 262 14;
BA_ "CANFD_BRS" BO_ 261 1;
BA_ "GenMsgCycleTime" BO_ 261 10;
BA_ "VFrameFormat" BO_ 261 14;
BA_ "CANFD_BRS" BO_ 554 1;
BA_ "GenMsgCycleTime" BO_ 554 50;
BA_ "GenMsgStartDelayTime" BO_ 554 10;
BA_ "VFrameFormat" BO_ 554 14;
BA_ "CANFD_BRS" BO_ 631 1;
BA_ "GenMsgCycleTime" BO_ 631 50;
BA_ "GenMsgStartDelayTime" BO_ 631 35;
BA_ "VFrameFormat" BO_ 631 14;
BA_ "CANFD_BRS" BO_ 1448 1;
BA_ "GenMsgCycleTime" BO_ 1448 1000;
BA_ "GenMsgStartDelayTime" BO_ 1448 225;
BA_ "VFrameFormat" BO_ 1448 14;
BA_ "CANFD_BRS" BO_ 1319 1;
BA_ "GenMsgCycleTime" BO_ 1319 250;
BA_ "GenMsgStartDelayTime" BO_ 1319 50;
BA_ "VFrameFormat" BO_ 1319 14;
BA_ "CANFD_BRS" BO_ 1447 1;
BA_ "GenMsgCycleTime" BO_ 1447 1000;
BA_ "GenMsgStartDelayTime" BO_ 1447 110;
BA_ "VFrameFormat" BO_ 1447 14;
BA_ "CANFD_BRS" BO_ 1034 1;
BA_ "GenMsgCycleTime" BO_ 1034 100;
BA_ "GenMsgStartDelayTime" BO_ 1034 25;
BA_ "VFrameFormat" BO_ 1034 14;
BA_ "CANFD_BRS" BO_ 426 1;
BA_ "GenMsgCycleTime" BO_ 426 20;
BA_ "GenMsgStartDelayTime" BO_ 426 5;
BA_ "VFrameFormat" BO_ 426 14;
BA_ "CANFD_BRS" BO_ 268 1;
BA_ "GenMsgCycleTime" BO_ 268 10;
BA_ "GenMsgStartDelayTime" BO_ 268 5;
BA_ "VFrameFormat" BO_ 268 14;
BA_ "GenSigSendType" SG_ 1512 PhyDiagTPM2BrkReqSig_ISig_3 1;
BA_ "GenSigCycleTime" SG_ 1512 PhyDiagTPM2BrkReqSig_ISig_3 100;
BA_ "GenSigCycleTimeActive" SG_ 1512 PhyDiagTPM2BrkReqSig_ISig_3 100;
BA_ "GenSigCycleTime" SG_ 266 ZxbrReqVeh_RetReq 100;
BA_ "GenSigCycleTimeActive" SG_ 266 ZxbrReqVeh_RetReq 100;
BA_ "GenSigStartValue" SG_ 266 ZxbrReqVeh_RetReq 255;
BA_ "GenSigCycleTime" SG_ 266 ZxbrReqVeh_RetModReq 100;
BA_ "GenSigCycleTimeActive" SG_ 266 ZxbrReqVeh_RetModReq 100;
BA_ "GenSigStartValue" SG_ 266 ZxbrReqVeh_RetModReq 7;
BA_ "GenSigCycleTime" SG_ 266 ZxbrReqVeh_RetEbiModReq 100;
BA_ "GenSigCycleTimeActive" SG_ 266 ZxbrReqVeh_RetEbiModReq 100;
BA_ "GenSigStartValue" SG_ 266 ZxbrReqVeh_RetEbiModReq 7;
BA_ "GenSigCycleTime" SG_ 266 ZxbrReqVeh_EbsCtrlModReq 100;
BA_ "GenSigCycleTimeActive" SG_ 266 ZxbrReqVeh_EbsCtrlModReq 100;
BA_ "GenSigStartValue" SG_ 266 ZxbrReqVeh_EbsCtrlModReq 3;
BA_ "GenSigCycleTime" SG_ 266 ZxbrReqVeh_CRC 100;
BA_ "GenSigCycleTimeActive" SG_ 266 ZxbrReqVeh_CRC 100;
BA_ "GenSigStartValue" SG_ 266 ZxbrReqVeh_CRC 255;
BA_ "E2EDataId" SG_ 266 ZxbrReqVeh_CRC 198;
BA_ "E2EDataLength" SG_ 266 ZxbrReqVeh_CRC 48;
BA_ "E2EProfile" SG_ 266 ZxbrReqVeh_CRC "P01";
BA_ "GenSigCycleTime" SG_ 266 ZxbrReqVeh_DrvrModReq 100;
BA_ "GenSigCycleTimeActive" SG_ 266 ZxbrReqVeh_DrvrModReq 100;
BA_ "GenSigStartValue" SG_ 266 ZxbrReqVeh_DrvrModReq 3;
BA_ "GenSigCycleTime" SG_ 266 ZxbrReqVeh_YawRateRefVds 100;
BA_ "GenSigCycleTimeActive" SG_ 266 ZxbrReqVeh_YawRateRefVds 100;
BA_ "GenSigStartValue" SG_ 266 ZxbrReqVeh_YawRateRefVds 4095;
BA_ "GenSigCycleTime" SG_ 266 ZxbrReqVeh_SqC 100;
BA_ "GenSigCycleTimeActive" SG_ 266 ZxbrReqVeh_SqC 100;
BA_ "GenSigStartValue" SG_ 266 ZxbrReqVeh_SqC 14;
BA_ "GenSigCycleTime" SG_ 1791 VCMNetVer_C03_Major 100;
BA_ "GenSigCycleTimeActive" SG_ 1791 VCMNetVer_C03_Major 100;
BA_ "GenSigStartValue" SG_ 1791 VCMNetVer_C03_Major 2;
BA_ "GenSigCycleTime" SG_ 1791 VCMNetVer_C03_Dirty 100;
BA_ "GenSigCycleTimeActive" SG_ 1791 VCMNetVer_C03_Dirty 100;
BA_ "GenSigCycleTime" SG_ 1791 VCMNetVer_C03_Patch 100;
BA_ "GenSigCycleTimeActive" SG_ 1791 VCMNetVer_C03_Patch 100;
BA_ "GenSigCycleTime" SG_ 1791 VCMNetVer_C03_NetID 100;
BA_ "GenSigCycleTimeActive" SG_ 1791 VCMNetVer_C03_NetID 100;
BA_ "GenSigStartValue" SG_ 1791 VCMNetVer_C03_NetID 3;
BA_ "GenSigCycleTime" SG_ 1791 VCMNetVer_C03_Minor 100;
BA_ "GenSigCycleTimeActive" SG_ 1791 VCMNetVer_C03_Minor 100;
BA_ "GenSigStartValue" SG_ 1791 VCMNetVer_C03_Minor 3;
BA_ "GenSigCycleTime" SG_ 262 IxbrReqAxle4_SlipCtrlEna 100;
BA_ "GenSigCycleTimeActive" SG_ 262 IxbrReqAxle4_SlipCtrlEna 100;
BA_ "GenSigStartValue" SG_ 262 IxbrReqAxle4_SlipCtrlEna 3;
BA_ "GenSigCycleTime" SG_ 262 IxbrReqAxle5_SqC 100;
BA_ "GenSigCycleTimeActive" SG_ 262 IxbrReqAxle5_SqC 100;
BA_ "GenSigStartValue" SG_ 262 IxbrReqAxle5_SqC 14;
BA_ "GenSigCycleTime" SG_ 262 IxbrReqAxle4_BrkTqReqLe 100;
BA_ "GenSigCycleTimeActive" SG_ 262 IxbrReqAxle4_BrkTqReqLe 100;
BA_ "GenSigStartValue" SG_ 262 IxbrReqAxle4_BrkTqReqLe 8191;
BA_ "GenSigCycleTime" SG_ 262 IxbrReqAxle4_CRC 100;
BA_ "GenSigCycleTimeActive" SG_ 262 IxbrReqAxle4_CRC 100;
BA_ "GenSigStartValue" SG_ 262 IxbrReqAxle4_CRC 255;
BA_ "E2EDataId" SG_ 262 IxbrReqAxle4_CRC 218;
BA_ "E2EDataLength" SG_ 262 IxbrReqAxle4_CRC 112;
BA_ "E2EProfile" SG_ 262 IxbrReqAxle4_CRC "P01";
BA_ "GenSigCycleTime" SG_ 262 IxbrReqAxle5_VehSpdLgtWhlRi 100;
BA_ "GenSigCycleTimeActive" SG_ 262 IxbrReqAxle5_VehSpdLgtWhlRi 100;
BA_ "GenSigStartValue" SG_ 262 IxbrReqAxle5_VehSpdLgtWhlRi 8191;
BA_ "GenSigCycleTime" SG_ 262 IxbrReqAxle6_WhlSlipLimLoLe 100;
BA_ "GenSigCycleTimeActive" SG_ 262 IxbrReqAxle6_WhlSlipLimLoLe 100;
BA_ "GenSigStartValue" SG_ 262 IxbrReqAxle6_WhlSlipLimLoLe 511;
BA_ "GenSigCycleTime" SG_ 262 IxbrReqAxle5_BrkTqReqRi 100;
BA_ "GenSigCycleTimeActive" SG_ 262 IxbrReqAxle5_BrkTqReqRi 100;
BA_ "GenSigStartValue" SG_ 262 IxbrReqAxle5_BrkTqReqRi 8191;
BA_ "GenSigCycleTime" SG_ 262 IxbrReqAxle4_BrkTqReqRi 100;
BA_ "GenSigCycleTimeActive" SG_ 262 IxbrReqAxle4_BrkTqReqRi 100;
BA_ "GenSigStartValue" SG_ 262 IxbrReqAxle4_BrkTqReqRi 8191;
BA_ "GenSigCycleTime" SG_ 262 IxbrReqAxle6_WhlSlipLimHiRi 100;
BA_ "GenSigCycleTimeActive" SG_ 262 IxbrReqAxle6_WhlSlipLimHiRi 100;
BA_ "GenSigStartValue" SG_ 262 IxbrReqAxle6_WhlSlipLimHiRi 511;
BA_ "GenSigCycleTime" SG_ 262 IxbrReqAxle6_SqC 100;
BA_ "GenSigCycleTimeActive" SG_ 262 IxbrReqAxle6_SqC 100;
BA_ "GenSigStartValue" SG_ 262 IxbrReqAxle6_SqC 14;
BA_ "GenSigCycleTime" SG_ 262 IxbrReqAxle5_SlipCtrlEna 100;
BA_ "GenSigCycleTimeActive" SG_ 262 IxbrReqAxle5_SlipCtrlEna 100;
BA_ "GenSigStartValue" SG_ 262 IxbrReqAxle5_SlipCtrlEna 3;
BA_ "GenSigCycleTime" SG_ 262 IxbrReqAxle5_WhlSlipLimLoRi 100;
BA_ "GenSigCycleTimeActive" SG_ 262 IxbrReqAxle5_WhlSlipLimLoRi 100;
BA_ "GenSigStartValue" SG_ 262 IxbrReqAxle5_WhlSlipLimLoRi 511;
BA_ "GenSigCycleTime" SG_ 262 IxbrReqAxle5_VehSpdLgtWhlLe 100;
BA_ "GenSigCycleTimeActive" SG_ 262 IxbrReqAxle5_VehSpdLgtWhlLe 100;
BA_ "GenSigStartValue" SG_ 262 IxbrReqAxle5_VehSpdLgtWhlLe 8191;
BA_ "GenSigCycleTime" SG_ 262 IxbrReqAxle6_WhlSlipLimLoRi 100;
BA_ "GenSigCycleTimeActive" SG_ 262 IxbrReqAxle6_WhlSlipLimLoRi 100;
BA_ "GenSigStartValue" SG_ 262 IxbrReqAxle6_WhlSlipLimLoRi 511;
BA_ "GenSigCycleTime" SG_ 262 IxbrReqAxle6_VehSpdLgtWhlRi 100;
BA_ "GenSigCycleTimeActive" SG_ 262 IxbrReqAxle6_VehSpdLgtWhlRi 100;
BA_ "GenSigStartValue" SG_ 262 IxbrReqAxle6_VehSpdLgtWhlRi 8191;
BA_ "GenSigCycleTime" SG_ 262 IxbrReqAxle5_VehSpdLgtWhlQltyLe 100;
BA_ "GenSigCycleTimeActive" SG_ 262 IxbrReqAxle5_VehSpdLgtWhlQltyLe 100;
BA_ "GenSigStartValue" SG_ 262 IxbrReqAxle5_VehSpdLgtWhlQltyLe 3;
BA_ "GenSigCycleTime" SG_ 262 IxbrReqAxle6_CRC 100;
BA_ "GenSigCycleTimeActive" SG_ 262 IxbrReqAxle6_CRC 100;
BA_ "GenSigStartValue" SG_ 262 IxbrReqAxle6_CRC 255;
BA_ "E2EDataId" SG_ 262 IxbrReqAxle6_CRC 220;
BA_ "E2EDataLength" SG_ 262 IxbrReqAxle6_CRC 112;
BA_ "E2EProfile" SG_ 262 IxbrReqAxle6_CRC "P01";
BA_ "GenSigCycleTime" SG_ 262 IxbrReqAxle5_CRC 100;
BA_ "GenSigCycleTimeActive" SG_ 262 IxbrReqAxle5_CRC 100;
BA_ "GenSigStartValue" SG_ 262 IxbrReqAxle5_CRC 255;
BA_ "E2EDataId" SG_ 262 IxbrReqAxle5_CRC 219;
BA_ "E2EDataLength" SG_ 262 IxbrReqAxle5_CRC 112;
BA_ "E2EProfile" SG_ 262 IxbrReqAxle5_CRC "P01";
BA_ "GenSigCycleTime" SG_ 262 IxbrReqAxle4_SqC 100;
BA_ "GenSigCycleTimeActive" SG_ 262 IxbrReqAxle4_SqC 100;
BA_ "GenSigStartValue" SG_ 262 IxbrReqAxle4_SqC 14;
BA_ "GenSigCycleTime" SG_ 262 IxbrReqAxle4_VehSpdLgtWhlRi 100;
BA_ "GenSigCycleTimeActive" SG_ 262 IxbrReqAxle4_VehSpdLgtWhlRi 100;
BA_ "GenSigStartValue" SG_ 262 IxbrReqAxle4_VehSpdLgtWhlRi 8191;
BA_ "GenSigCycleTime" SG_ 262 IxbrReqAxle4_WhlSlipLimHiLe 100;
BA_ "GenSigCycleTimeActive" SG_ 262 IxbrReqAxle4_WhlSlipLimHiLe 100;
BA_ "GenSigStartValue" SG_ 262 IxbrReqAxle4_WhlSlipLimHiLe 511;
BA_ "GenSigCycleTime" SG_ 262 IxbrReqAxle4_VehSpdLgtWhlLe 100;
BA_ "GenSigCycleTimeActive" SG_ 262 IxbrReqAxle4_VehSpdLgtWhlLe 100;
BA_ "GenSigStartValue" SG_ 262 IxbrReqAxle4_VehSpdLgtWhlLe 8191;
BA_ "GenSigCycleTime" SG_ 262 IxbrReqAxle4_WhlSlipLimLoLe 100;
BA_ "GenSigCycleTimeActive" SG_ 262 IxbrReqAxle4_WhlSlipLimLoLe 100;
BA_ "GenSigStartValue" SG_ 262 IxbrReqAxle4_WhlSlipLimLoLe 511;
BA_ "GenSigCycleTime" SG_ 262 IxbrReqAxle6_VehSpdLgtWhlQltyRi 100;
BA_ "GenSigCycleTimeActive" SG_ 262 IxbrReqAxle6_VehSpdLgtWhlQltyRi 100;
BA_ "GenSigStartValue" SG_ 262 IxbrReqAxle6_VehSpdLgtWhlQltyRi 3;
BA_ "GenSigCycleTime" SG_ 262 IxbrReqAxle6_BrkTqReqLe 100;
BA_ "GenSigCycleTimeActive" SG_ 262 IxbrReqAxle6_BrkTqReqLe 100;
BA_ "GenSigStartValue" SG_ 262 IxbrReqAxle6_BrkTqReqLe 8191;
BA_ "GenSigCycleTime" SG_ 262 IxbrReqAxle4_WhlSlipLimLoRi 100;
BA_ "GenSigCycleTimeActive" SG_ 262 IxbrReqAxle4_WhlSlipLimLoRi 100;
BA_ "GenSigStartValue" SG_ 262 IxbrReqAxle4_WhlSlipLimLoRi 511;
BA_ "GenSigCycleTime" SG_ 262 IxbrReqAxle4_VehSpdLgtWhlQltyRi 100;
BA_ "GenSigCycleTimeActive" SG_ 262 IxbrReqAxle4_VehSpdLgtWhlQltyRi 100;
BA_ "GenSigStartValue" SG_ 262 IxbrReqAxle4_VehSpdLgtWhlQltyRi 3;
BA_ "GenSigCycleTime" SG_ 262 IxbrReqAxle4_IxbrModReq 100;
BA_ "GenSigCycleTimeActive" SG_ 262 IxbrReqAxle4_IxbrModReq 100;
BA_ "GenSigStartValue" SG_ 262 IxbrReqAxle4_IxbrModReq 7;
BA_ "GenSigCycleTime" SG_ 262 IxbrReqAxle6_BrkTqReqRi 100;
BA_ "GenSigCycleTimeActive" SG_ 262 IxbrReqAxle6_BrkTqReqRi 100;
BA_ "GenSigStartValue" SG_ 262 IxbrReqAxle6_BrkTqReqRi 8191;
BA_ "GenSigCycleTime" SG_ 262 IxbrReqAxle6_SlipCtrlEna 100;
BA_ "GenSigCycleTimeActive" SG_ 262 IxbrReqAxle6_SlipCtrlEna 100;
BA_ "GenSigStartValue" SG_ 262 IxbrReqAxle6_SlipCtrlEna 3;
BA_ "GenSigCycleTime" SG_ 262 IxbrReqAxle4_VehSpdLgtWhlQltyLe 100;
BA_ "GenSigCycleTimeActive" SG_ 262 IxbrReqAxle4_VehSpdLgtWhlQltyLe 100;
BA_ "GenSigStartValue" SG_ 262 IxbrReqAxle4_VehSpdLgtWhlQltyLe 3;
BA_ "GenSigCycleTime" SG_ 262 IxbrReqAxle6_VehSpdLgtWhlQltyLe 100;
BA_ "GenSigCycleTimeActive" SG_ 262 IxbrReqAxle6_VehSpdLgtWhlQltyLe 100;
BA_ "GenSigStartValue" SG_ 262 IxbrReqAxle6_VehSpdLgtWhlQltyLe 3;
BA_ "GenSigCycleTime" SG_ 262 IxbrReqAxle5_BrkTqReqLe 100;
BA_ "GenSigCycleTimeActive" SG_ 262 IxbrReqAxle5_BrkTqReqLe 100;
BA_ "GenSigStartValue" SG_ 262 IxbrReqAxle5_BrkTqReqLe 8191;
BA_ "GenSigCycleTime" SG_ 262 IxbrReqAxle5_VehSpdLgtWhlQltyRi 100;
BA_ "GenSigCycleTimeActive" SG_ 262 IxbrReqAxle5_VehSpdLgtWhlQltyRi 100;
BA_ "GenSigStartValue" SG_ 262 IxbrReqAxle5_VehSpdLgtWhlQltyRi 3;
BA_ "GenSigCycleTime" SG_ 262 IxbrReqAxle5_WhlSlipLimHiRi 100;
BA_ "GenSigCycleTimeActive" SG_ 262 IxbrReqAxle5_WhlSlipLimHiRi 100;
BA_ "GenSigStartValue" SG_ 262 IxbrReqAxle5_WhlSlipLimHiRi 511;
BA_ "GenSigCycleTime" SG_ 262 IxbrReqAxle5_WhlSlipLimLoLe 100;
BA_ "GenSigCycleTimeActive" SG_ 262 IxbrReqAxle5_WhlSlipLimLoLe 100;
BA_ "GenSigStartValue" SG_ 262 IxbrReqAxle5_WhlSlipLimLoLe 511;
BA_ "GenSigCycleTime" SG_ 262 IxbrReqAxle5_IxbrModReq 100;
BA_ "GenSigCycleTimeActive" SG_ 262 IxbrReqAxle5_IxbrModReq 100;
BA_ "GenSigStartValue" SG_ 262 IxbrReqAxle5_IxbrModReq 7;
BA_ "GenSigCycleTime" SG_ 262 IxbrReqAxle4_WhlSlipLimHiRi 100;
BA_ "GenSigCycleTimeActive" SG_ 262 IxbrReqAxle4_WhlSlipLimHiRi 100;
BA_ "GenSigStartValue" SG_ 262 IxbrReqAxle4_WhlSlipLimHiRi 511;
BA_ "GenSigCycleTime" SG_ 262 IxbrReqAxle6_IxbrModReq 100;
BA_ "GenSigCycleTimeActive" SG_ 262 IxbrReqAxle6_IxbrModReq 100;
BA_ "GenSigStartValue" SG_ 262 IxbrReqAxle6_IxbrModReq 7;
BA_ "GenSigCycleTime" SG_ 262 IxbrReqAxle5_WhlSlipLimHiLe 100;
BA_ "GenSigCycleTimeActive" SG_ 262 IxbrReqAxle5_WhlSlipLimHiLe 100;
BA_ "GenSigStartValue" SG_ 262 IxbrReqAxle5_WhlSlipLimHiLe 511;
BA_ "GenSigCycleTime" SG_ 262 IxbrReqAxle6_WhlSlipLimHiLe 100;
BA_ "GenSigCycleTimeActive" SG_ 262 IxbrReqAxle6_WhlSlipLimHiLe 100;
BA_ "GenSigStartValue" SG_ 262 IxbrReqAxle6_WhlSlipLimHiLe 511;
BA_ "GenSigCycleTime" SG_ 262 IxbrReqAxle6_VehSpdLgtWhlLe 100;
BA_ "GenSigCycleTimeActive" SG_ 262 IxbrReqAxle6_VehSpdLgtWhlLe 100;
BA_ "GenSigStartValue" SG_ 262 IxbrReqAxle6_VehSpdLgtWhlLe 8191;
BA_ "GenSigCycleTime" SG_ 261 IxbrReqAxle3_BrkTqReqLe 100;
BA_ "GenSigCycleTimeActive" SG_ 261 IxbrReqAxle3_BrkTqReqLe 100;
BA_ "GenSigStartValue" SG_ 261 IxbrReqAxle3_BrkTqReqLe 8191;
BA_ "GenSigCycleTime" SG_ 261 IxbrReqAxle3_WhlSlipLimHiLe 100;
BA_ "GenSigCycleTimeActive" SG_ 261 IxbrReqAxle3_WhlSlipLimHiLe 100;
BA_ "GenSigStartValue" SG_ 261 IxbrReqAxle3_WhlSlipLimHiLe 511;
BA_ "GenSigCycleTime" SG_ 261 IxbrReqAxle1_BrkTqReqLe 100;
BA_ "GenSigCycleTimeActive" SG_ 261 IxbrReqAxle1_BrkTqReqLe 100;
BA_ "GenSigStartValue" SG_ 261 IxbrReqAxle1_BrkTqReqLe 8191;
BA_ "GenSigCycleTime" SG_ 261 IxbrReqAxle2_WhlSlipLimHiRi 100;
BA_ "GenSigCycleTimeActive" SG_ 261 IxbrReqAxle2_WhlSlipLimHiRi 100;
BA_ "GenSigStartValue" SG_ 261 IxbrReqAxle2_WhlSlipLimHiRi 511;
BA_ "GenSigCycleTime" SG_ 261 IxbrReqAxle3_WhlSlipLimLoRi 100;
BA_ "GenSigCycleTimeActive" SG_ 261 IxbrReqAxle3_WhlSlipLimLoRi 100;
BA_ "GenSigStartValue" SG_ 261 IxbrReqAxle3_WhlSlipLimLoRi 511;
BA_ "GenSigCycleTime" SG_ 261 IxbrReqAxle1_WhlSlipLimLoLe 100;
BA_ "GenSigCycleTimeActive" SG_ 261 IxbrReqAxle1_WhlSlipLimLoLe 100;
BA_ "GenSigStartValue" SG_ 261 IxbrReqAxle1_WhlSlipLimLoLe 511;
BA_ "GenSigCycleTime" SG_ 261 IxbrReqAxle3_BrkTqReqRi 100;
BA_ "GenSigCycleTimeActive" SG_ 261 IxbrReqAxle3_BrkTqReqRi 100;
BA_ "GenSigStartValue" SG_ 261 IxbrReqAxle3_BrkTqReqRi 8191;
BA_ "GenSigCycleTime" SG_ 261 IxbrReqAxle2_BrkTqReqLe 100;
BA_ "GenSigCycleTimeActive" SG_ 261 IxbrReqAxle2_BrkTqReqLe 100;
BA_ "GenSigStartValue" SG_ 261 IxbrReqAxle2_BrkTqReqLe 8191;
BA_ "GenSigCycleTime" SG_ 261 IxbrReqAxle1_VehSpdLgtWhlQltyRi 100;
BA_ "GenSigCycleTimeActive" SG_ 261 IxbrReqAxle1_VehSpdLgtWhlQltyRi 100;
BA_ "GenSigStartValue" SG_ 261 IxbrReqAxle1_VehSpdLgtWhlQltyRi 3;
BA_ "GenSigCycleTime" SG_ 261 IxbrReqAxle2_BrkTqReqRi 100;
BA_ "GenSigCycleTimeActive" SG_ 261 IxbrReqAxle2_BrkTqReqRi 100;
BA_ "GenSigStartValue" SG_ 261 IxbrReqAxle2_BrkTqReqRi 8191;
BA_ "GenSigCycleTime" SG_ 261 IxbrReqAxle1_WhlSlipLimHiLe 100;
BA_ "GenSigCycleTimeActive" SG_ 261 IxbrReqAxle1_WhlSlipLimHiLe 100;
BA_ "GenSigStartValue" SG_ 261 IxbrReqAxle1_WhlSlipLimHiLe 511;
BA_ "GenSigCycleTime" SG_ 261 IxbrReqAxle1_SlipCtrlEna 100;
BA_ "GenSigCycleTimeActive" SG_ 261 IxbrReqAxle1_SlipCtrlEna 100;
BA_ "GenSigStartValue" SG_ 261 IxbrReqAxle1_SlipCtrlEna 3;
BA_ "GenSigCycleTime" SG_ 261 IxbrReqAxle1_WhlSlipLimLoRi 100;
BA_ "GenSigCycleTimeActive" SG_ 261 IxbrReqAxle1_WhlSlipLimLoRi 100;
BA_ "GenSigStartValue" SG_ 261 IxbrReqAxle1_WhlSlipLimLoRi 511;
BA_ "GenSigCycleTime" SG_ 261 IxbrReqAxle2_SlipCtrlEna 100;
BA_ "GenSigCycleTimeActive" SG_ 261 IxbrReqAxle2_SlipCtrlEna 100;
BA_ "GenSigStartValue" SG_ 261 IxbrReqAxle2_SlipCtrlEna 3;
BA_ "GenSigCycleTime" SG_ 261 IxbrReqAxle1_IxbrModReq 100;
BA_ "GenSigCycleTimeActive" SG_ 261 IxbrReqAxle1_IxbrModReq 100;
BA_ "GenSigStartValue" SG_ 261 IxbrReqAxle1_IxbrModReq 7;
BA_ "GenSigCycleTime" SG_ 261 IxbrReqAxle1_SqC 100;
BA_ "GenSigCycleTimeActive" SG_ 261 IxbrReqAxle1_SqC 100;
BA_ "GenSigStartValue" SG_ 261 IxbrReqAxle1_SqC 14;
BA_ "GenSigCycleTime" SG_ 261 IxbrReqAxle3_VehSpdLgtWhlQltyLe 100;
BA_ "GenSigCycleTimeActive" SG_ 261 IxbrReqAxle3_VehSpdLgtWhlQltyLe 100;
BA_ "GenSigStartValue" SG_ 261 IxbrReqAxle3_VehSpdLgtWhlQltyLe 3;
BA_ "GenSigCycleTime" SG_ 261 IxbrReqAxle3_SqC 100;
BA_ "GenSigCycleTimeActive" SG_ 261 IxbrReqAxle3_SqC 100;
BA_ "GenSigStartValue" SG_ 261 IxbrReqAxle3_SqC 14;
BA_ "GenSigCycleTime" SG_ 261 IxbrReqAxle2_WhlSlipLimLoRi 100;
BA_ "GenSigCycleTimeActive" SG_ 261 IxbrReqAxle2_WhlSlipLimLoRi 100;
BA_ "GenSigStartValue" SG_ 261 IxbrReqAxle2_WhlSlipLimLoRi 511;
BA_ "GenSigCycleTime" SG_ 261 IxbrReqAxle1_WhlSlipLimHiRi 100;
BA_ "GenSigCycleTimeActive" SG_ 261 IxbrReqAxle1_WhlSlipLimHiRi 100;
BA_ "GenSigStartValue" SG_ 261 IxbrReqAxle1_WhlSlipLimHiRi 511;
BA_ "GenSigCycleTime" SG_ 261 IxbrReqAxle2_IxbrModReq 100;
BA_ "GenSigCycleTimeActive" SG_ 261 IxbrReqAxle2_IxbrModReq 100;
BA_ "GenSigStartValue" SG_ 261 IxbrReqAxle2_IxbrModReq 7;
BA_ "GenSigCycleTime" SG_ 261 IxbrReqAxle3_WhlSlipLimLoLe 100;
BA_ "GenSigCycleTimeActive" SG_ 261 IxbrReqAxle3_WhlSlipLimLoLe 100;
BA_ "GenSigStartValue" SG_ 261 IxbrReqAxle3_WhlSlipLimLoLe 511;
BA_ "GenSigCycleTime" SG_ 261 IxbrReqAxle2_SqC 100;
BA_ "GenSigCycleTimeActive" SG_ 261 IxbrReqAxle2_SqC 100;
BA_ "GenSigStartValue" SG_ 261 IxbrReqAxle2_SqC 14;
BA_ "GenSigCycleTime" SG_ 261 IxbrReqAxle1_VehSpdLgtWhlLe 100;
BA_ "GenSigCycleTimeActive" SG_ 261 IxbrReqAxle1_VehSpdLgtWhlLe 100;
BA_ "GenSigStartValue" SG_ 261 IxbrReqAxle1_VehSpdLgtWhlLe 8191;
BA_ "GenSigCycleTime" SG_ 261 IxbrReqAxle3_VehSpdLgtWhlRi 100;
BA_ "GenSigCycleTimeActive" SG_ 261 IxbrReqAxle3_VehSpdLgtWhlRi 100;
BA_ "GenSigStartValue" SG_ 261 IxbrReqAxle3_VehSpdLgtWhlRi 8191;
BA_ "GenSigCycleTime" SG_ 261 IxbrReqAxle3_WhlSlipLimHiRi 100;
BA_ "GenSigCycleTimeActive" SG_ 261 IxbrReqAxle3_WhlSlipLimHiRi 100;
BA_ "GenSigStartValue" SG_ 261 IxbrReqAxle3_WhlSlipLimHiRi 511;
BA_ "GenSigCycleTime" SG_ 261 IxbrReqAxle2_WhlSlipLimLoLe 100;
BA_ "GenSigCycleTimeActive" SG_ 261 IxbrReqAxle2_WhlSlipLimLoLe 100;
BA_ "GenSigStartValue" SG_ 261 IxbrReqAxle2_WhlSlipLimLoLe 511;
BA_ "GenSigCycleTime" SG_ 261 IxbrReqAxle2_VehSpdLgtWhlLe 100;
BA_ "GenSigCycleTimeActive" SG_ 261 IxbrReqAxle2_VehSpdLgtWhlLe 100;
BA_ "GenSigStartValue" SG_ 261 IxbrReqAxle2_VehSpdLgtWhlLe 8191;
BA_ "GenSigCycleTime" SG_ 261 IxbrReqAxle2_WhlSlipLimHiLe 100;
BA_ "GenSigCycleTimeActive" SG_ 261 IxbrReqAxle2_WhlSlipLimHiLe 100;
BA_ "GenSigStartValue" SG_ 261 IxbrReqAxle2_WhlSlipLimHiLe 511;
BA_ "GenSigCycleTime" SG_ 261 IxbrReqAxle3_VehSpdLgtWhlQltyRi 100;
BA_ "GenSigCycleTimeActive" SG_ 261 IxbrReqAxle3_VehSpdLgtWhlQltyRi 100;
BA_ "GenSigStartValue" SG_ 261 IxbrReqAxle3_VehSpdLgtWhlQltyRi 3;
BA_ "GenSigCycleTime" SG_ 261 IxbrReqAxle1_VehSpdLgtWhlQltyLe 100;
BA_ "GenSigCycleTimeActive" SG_ 261 IxbrReqAxle1_VehSpdLgtWhlQltyLe 100;
BA_ "GenSigStartValue" SG_ 261 IxbrReqAxle1_VehSpdLgtWhlQltyLe 3;
BA_ "GenSigCycleTime" SG_ 261 IxbrReqAxle1_BrkTqReqRi 100;
BA_ "GenSigCycleTimeActive" SG_ 261 IxbrReqAxle1_BrkTqReqRi 100;
BA_ "GenSigStartValue" SG_ 261 IxbrReqAxle1_BrkTqReqRi 8191;
BA_ "GenSigCycleTime" SG_ 261 IxbrReqAxle1_VehSpdLgtWhlRi 100;
BA_ "GenSigCycleTimeActive" SG_ 261 IxbrReqAxle1_VehSpdLgtWhlRi 100;
BA_ "GenSigStartValue" SG_ 261 IxbrReqAxle1_VehSpdLgtWhlRi 8191;
BA_ "GenSigCycleTime" SG_ 261 IxbrReqAxle3_IxbrModReq 100;
BA_ "GenSigCycleTimeActive" SG_ 261 IxbrReqAxle3_IxbrModReq 100;
BA_ "GenSigStartValue" SG_ 261 IxbrReqAxle3_IxbrModReq 7;
BA_ "GenSigCycleTime" SG_ 261 IxbrReqAxle2_CRC 100;
BA_ "GenSigCycleTimeActive" SG_ 261 IxbrReqAxle2_CRC 100;
BA_ "GenSigStartValue" SG_ 261 IxbrReqAxle2_CRC 255;
BA_ "E2EDataId" SG_ 261 IxbrReqAxle2_CRC 216;
BA_ "E2EDataLength" SG_ 261 IxbrReqAxle2_CRC 112;
BA_ "E2EProfile" SG_ 261 IxbrReqAxle2_CRC "P01";
BA_ "GenSigCycleTime" SG_ 261 IxbrReqAxle2_VehSpdLgtWhlQltyLe 100;
BA_ "GenSigCycleTimeActive" SG_ 261 IxbrReqAxle2_VehSpdLgtWhlQltyLe 100;
BA_ "GenSigStartValue" SG_ 261 IxbrReqAxle2_VehSpdLgtWhlQltyLe 3;
BA_ "GenSigCycleTime" SG_ 261 IxbrReqAxle3_VehSpdLgtWhlLe 100;
BA_ "GenSigCycleTimeActive" SG_ 261 IxbrReqAxle3_VehSpdLgtWhlLe 100;
BA_ "GenSigStartValue" SG_ 261 IxbrReqAxle3_VehSpdLgtWhlLe 8191;
BA_ "GenSigCycleTime" SG_ 261 IxbrReqAxle3_SlipCtrlEna 100;
BA_ "GenSigCycleTimeActive" SG_ 261 IxbrReqAxle3_SlipCtrlEna 100;
BA_ "GenSigStartValue" SG_ 261 IxbrReqAxle3_SlipCtrlEna 3;
BA_ "GenSigCycleTime" SG_ 261 IxbrReqAxle3_CRC 100;
BA_ "GenSigCycleTimeActive" SG_ 261 IxbrReqAxle3_CRC 100;
BA_ "GenSigStartValue" SG_ 261 IxbrReqAxle3_CRC 255;
BA_ "E2EDataId" SG_ 261 IxbrReqAxle3_CRC 217;
BA_ "E2EDataLength" SG_ 261 IxbrReqAxle3_CRC 112;
BA_ "E2EProfile" SG_ 261 IxbrReqAxle3_CRC "P01";
BA_ "GenSigCycleTime" SG_ 261 IxbrReqAxle2_VehSpdLgtWhlRi 100;
BA_ "GenSigCycleTimeActive" SG_ 261 IxbrReqAxle2_VehSpdLgtWhlRi 100;
BA_ "GenSigStartValue" SG_ 261 IxbrReqAxle2_VehSpdLgtWhlRi 8191;
BA_ "GenSigCycleTime" SG_ 261 IxbrReqAxle2_VehSpdLgtWhlQltyRi 100;
BA_ "GenSigCycleTimeActive" SG_ 261 IxbrReqAxle2_VehSpdLgtWhlQltyRi 100;
BA_ "GenSigStartValue" SG_ 261 IxbrReqAxle2_VehSpdLgtWhlQltyRi 3;
BA_ "GenSigCycleTime" SG_ 261 IxbrReqAxle1_CRC 100;
BA_ "GenSigCycleTimeActive" SG_ 261 IxbrReqAxle1_CRC 100;
BA_ "GenSigStartValue" SG_ 261 IxbrReqAxle1_CRC 255;
BA_ "E2EDataId" SG_ 261 IxbrReqAxle1_CRC 215;
BA_ "E2EDataLength" SG_ 261 IxbrReqAxle1_CRC 112;
BA_ "E2EProfile" SG_ 261 IxbrReqAxle1_CRC "P01";
BA_ "GenSigCycleTime" SG_ 554 EstAxle3_LoadNormLe 100;
BA_ "GenSigCycleTimeActive" SG_ 554 EstAxle3_LoadNormLe 100;
BA_ "GenSigStartValue" SG_ 554 EstAxle3_LoadNormLe 255;
BA_ "GenSigCycleTime" SG_ 554 EstAxle6_WhlRdEstQltyRi 100;
BA_ "GenSigCycleTimeActive" SG_ 554 EstAxle6_WhlRdEstQltyRi 100;
BA_ "GenSigStartValue" SG_ 554 EstAxle6_WhlRdEstQltyRi 3;
BA_ "GenSigCycleTime" SG_ 554 EstAxle5_WhlRdEstQltyRi 100;
BA_ "GenSigCycleTimeActive" SG_ 554 EstAxle5_WhlRdEstQltyRi 100;
BA_ "GenSigStartValue" SG_ 554 EstAxle5_WhlRdEstQltyRi 3;
BA_ "GenSigCycleTime" SG_ 554 EstAxle2_LoadNormQltyLe 100;
BA_ "GenSigCycleTimeActive" SG_ 554 EstAxle2_LoadNormQltyLe 100;
BA_ "GenSigStartValue" SG_ 554 EstAxle2_LoadNormQltyLe 3;
BA_ "GenSigCycleTime" SG_ 554 EstAxle3_LoadNormQltyRi 100;
BA_ "GenSigCycleTimeActive" SG_ 554 EstAxle3_LoadNormQltyRi 100;
BA_ "GenSigStartValue" SG_ 554 EstAxle3_LoadNormQltyRi 3;
BA_ "GenSigCycleTime" SG_ 554 EstAxle6_SqC 100;
BA_ "GenSigCycleTimeActive" SG_ 554 EstAxle6_SqC 100;
BA_ "GenSigStartValue" SG_ 554 EstAxle6_SqC 14;
BA_ "GenSigCycleTime" SG_ 554 EstAxle4_LoadNormQltyRi 100;
BA_ "GenSigCycleTimeActive" SG_ 554 EstAxle4_LoadNormQltyRi 100;
BA_ "GenSigStartValue" SG_ 554 EstAxle4_LoadNormQltyRi 3;
BA_ "GenSigCycleTime" SG_ 554 EstAxle6_LoadNormRi 100;
BA_ "GenSigCycleTimeActive" SG_ 554 EstAxle6_LoadNormRi 100;
BA_ "GenSigStartValue" SG_ 554 EstAxle6_LoadNormRi 255;
BA_ "GenSigCycleTime" SG_ 554 EstAxle5_SqC 100;
BA_ "GenSigCycleTimeActive" SG_ 554 EstAxle5_SqC 100;
BA_ "GenSigStartValue" SG_ 554 EstAxle5_SqC 14;
BA_ "GenSigCycleTime" SG_ 554 EstAxle6_CRC 100;
BA_ "GenSigCycleTimeActive" SG_ 554 EstAxle6_CRC 100;
BA_ "GenSigStartValue" SG_ 554 EstAxle6_CRC 255;
BA_ "E2EDataId" SG_ 554 EstAxle6_CRC 214;
BA_ "E2EDataLength" SG_ 554 EstAxle6_CRC 56;
BA_ "E2EProfile" SG_ 554 EstAxle6_CRC "P01";
BA_ "GenSigCycleTime" SG_ 554 EstAxle2_WhlRdEstLe 100;
BA_ "GenSigCycleTimeActive" SG_ 554 EstAxle2_WhlRdEstLe 100;
BA_ "GenSigStartValue" SG_ 554 EstAxle2_WhlRdEstLe 1023;
BA_ "GenSigCycleTime" SG_ 554 EstAxle3_WhlRdEstRi 100;
BA_ "GenSigCycleTimeActive" SG_ 554 EstAxle3_WhlRdEstRi 100;
BA_ "GenSigStartValue" SG_ 554 EstAxle3_WhlRdEstRi 1023;
BA_ "GenSigCycleTime" SG_ 554 EstAxle5_LoadNormQltyRi 100;
BA_ "GenSigCycleTimeActive" SG_ 554 EstAxle5_LoadNormQltyRi 100;
BA_ "GenSigStartValue" SG_ 554 EstAxle5_LoadNormQltyRi 3;
BA_ "GenSigCycleTime" SG_ 554 EstAxle6_WhlRdEstLe 100;
BA_ "GenSigCycleTimeActive" SG_ 554 EstAxle6_WhlRdEstLe 100;
BA_ "GenSigStartValue" SG_ 554 EstAxle6_WhlRdEstLe 1023;
BA_ "GenSigCycleTime" SG_ 554 EstAxle6_WhlRdEstQltyLe 100;
BA_ "GenSigCycleTimeActive" SG_ 554 EstAxle6_WhlRdEstQltyLe 100;
BA_ "GenSigStartValue" SG_ 554 EstAxle6_WhlRdEstQltyLe 3;
BA_ "GenSigCycleTime" SG_ 554 EstAxle6_LoadNormLe 100;
BA_ "GenSigCycleTimeActive" SG_ 554 EstAxle6_LoadNormLe 100;
BA_ "GenSigStartValue" SG_ 554 EstAxle6_LoadNormLe 255;
BA_ "GenSigCycleTime" SG_ 554 EstAxle5_LoadNormRi 100;
BA_ "GenSigCycleTimeActive" SG_ 554 EstAxle5_LoadNormRi 100;
BA_ "GenSigStartValue" SG_ 554 EstAxle5_LoadNormRi 255;
BA_ "GenSigCycleTime" SG_ 554 EstAxle5_LoadNormQltyLe 100;
BA_ "GenSigCycleTimeActive" SG_ 554 EstAxle5_LoadNormQltyLe 100;
BA_ "GenSigStartValue" SG_ 554 EstAxle5_LoadNormQltyLe 3;
BA_ "GenSigCycleTime" SG_ 554 EstAxle5_CRC 100;
BA_ "GenSigCycleTimeActive" SG_ 554 EstAxle5_CRC 100;
BA_ "GenSigStartValue" SG_ 554 EstAxle5_CRC 255;
BA_ "E2EDataId" SG_ 554 EstAxle5_CRC 213;
BA_ "E2EDataLength" SG_ 554 EstAxle5_CRC 56;
BA_ "E2EProfile" SG_ 554 EstAxle5_CRC "P01";
BA_ "GenSigCycleTime" SG_ 554 EstAxle1_WhlRdEstRi 100;
BA_ "GenSigCycleTimeActive" SG_ 554 EstAxle1_WhlRdEstRi 100;
BA_ "GenSigStartValue" SG_ 554 EstAxle1_WhlRdEstRi 1023;
BA_ "GenSigCycleTime" SG_ 554 EstAxle4_LoadNormRi 100;
BA_ "GenSigCycleTimeActive" SG_ 554 EstAxle4_LoadNormRi 100;
BA_ "GenSigStartValue" SG_ 554 EstAxle4_LoadNormRi 255;
BA_ "GenSigCycleTime" SG_ 554 EstAxle3_WhlRdEstQltyLe 100;
BA_ "GenSigCycleTimeActive" SG_ 554 EstAxle3_WhlRdEstQltyLe 100;
BA_ "GenSigStartValue" SG_ 554 EstAxle3_WhlRdEstQltyLe 3;
BA_ "GenSigCycleTime" SG_ 554 EstAxle4_WhlRdEstRi 100;
BA_ "GenSigCycleTimeActive" SG_ 554 EstAxle4_WhlRdEstRi 100;
BA_ "GenSigStartValue" SG_ 554 EstAxle4_WhlRdEstRi 1023;
BA_ "GenSigCycleTime" SG_ 554 EstAxle6_WhlRdEstRi 100;
BA_ "GenSigCycleTimeActive" SG_ 554 EstAxle6_WhlRdEstRi 100;
BA_ "GenSigStartValue" SG_ 554 EstAxle6_WhlRdEstRi 1023;
BA_ "GenSigCycleTime" SG_ 554 EstAxle5_LoadNormLe 100;
BA_ "GenSigCycleTimeActive" SG_ 554 EstAxle5_LoadNormLe 100;
BA_ "GenSigStartValue" SG_ 554 EstAxle5_LoadNormLe 255;
BA_ "GenSigCycleTime" SG_ 554 EstAxle5_WhlRdEstLe 100;
BA_ "GenSigCycleTimeActive" SG_ 554 EstAxle5_WhlRdEstLe 100;
BA_ "GenSigStartValue" SG_ 554 EstAxle5_WhlRdEstLe 1023;
BA_ "GenSigCycleTime" SG_ 554 EstAxle3_CRC 100;
BA_ "GenSigCycleTimeActive" SG_ 554 EstAxle3_CRC 100;
BA_ "GenSigStartValue" SG_ 554 EstAxle3_CRC 255;
BA_ "E2EDataId" SG_ 554 EstAxle3_CRC 211;
BA_ "E2EDataLength" SG_ 554 EstAxle3_CRC 56;
BA_ "E2EProfile" SG_ 554 EstAxle3_CRC "P01";
BA_ "GenSigCycleTime" SG_ 554 EstAxle2_LoadNormRi 100;
BA_ "GenSigCycleTimeActive" SG_ 554 EstAxle2_LoadNormRi 100;
BA_ "GenSigStartValue" SG_ 554 EstAxle2_LoadNormRi 255;
BA_ "GenSigCycleTime" SG_ 554 EstAxle4_SqC 100;
BA_ "GenSigCycleTimeActive" SG_ 554 EstAxle4_SqC 100;
BA_ "GenSigStartValue" SG_ 554 EstAxle4_SqC 14;
BA_ "GenSigCycleTime" SG_ 554 EstAxle4_WhlRdEstQltyRi 100;
BA_ "GenSigCycleTimeActive" SG_ 554 EstAxle4_WhlRdEstQltyRi 100;
BA_ "GenSigStartValue" SG_ 554 EstAxle4_WhlRdEstQltyRi 3;
BA_ "GenSigCycleTime" SG_ 554 EstAxle6_LoadNormQltyRi 100;
BA_ "GenSigCycleTimeActive" SG_ 554 EstAxle6_LoadNormQltyRi 100;
BA_ "GenSigStartValue" SG_ 554 EstAxle6_LoadNormQltyRi 3;
BA_ "GenSigCycleTime" SG_ 554 EstAxle1_LoadNormQltyRi 100;
BA_ "GenSigCycleTimeActive" SG_ 554 EstAxle1_LoadNormQltyRi 100;
BA_ "GenSigStartValue" SG_ 554 EstAxle1_LoadNormQltyRi 3;
BA_ "GenSigCycleTime" SG_ 554 EstAxle1_LoadNormQltyLe 100;
BA_ "GenSigCycleTimeActive" SG_ 554 EstAxle1_LoadNormQltyLe 100;
BA_ "GenSigStartValue" SG_ 554 EstAxle1_LoadNormQltyLe 3;
BA_ "GenSigCycleTime" SG_ 554 EstAxle2_LoadNormLe 100;
BA_ "GenSigCycleTimeActive" SG_ 554 EstAxle2_LoadNormLe 100;
BA_ "GenSigStartValue" SG_ 554 EstAxle2_LoadNormLe 255;
BA_ "GenSigCycleTime" SG_ 554 EstAxle4_WhlRdEstQltyLe 100;
BA_ "GenSigCycleTimeActive" SG_ 554 EstAxle4_WhlRdEstQltyLe 100;
BA_ "GenSigStartValue" SG_ 554 EstAxle4_WhlRdEstQltyLe 3;
BA_ "GenSigCycleTime" SG_ 554 EstAxle4_WhlRdEstLe 100;
BA_ "GenSigCycleTimeActive" SG_ 554 EstAxle4_WhlRdEstLe 100;
BA_ "GenSigStartValue" SG_ 554 EstAxle4_WhlRdEstLe 1023;
BA_ "GenSigCycleTime" SG_ 554 EstAxle1_WhlRdEstQltyLe 100;
BA_ "GenSigCycleTimeActive" SG_ 554 EstAxle1_WhlRdEstQltyLe 100;
BA_ "GenSigStartValue" SG_ 554 EstAxle1_WhlRdEstQltyLe 3;
BA_ "GenSigCycleTime" SG_ 554 EstAxle2_LoadNormQltyRi 100;
BA_ "GenSigCycleTimeActive" SG_ 554 EstAxle2_LoadNormQltyRi 100;
BA_ "GenSigStartValue" SG_ 554 EstAxle2_LoadNormQltyRi 3;
BA_ "GenSigCycleTime" SG_ 554 EstAxle3_LoadNormQltyLe 100;
BA_ "GenSigCycleTimeActive" SG_ 554 EstAxle3_LoadNormQltyLe 100;
BA_ "GenSigStartValue" SG_ 554 EstAxle3_LoadNormQltyLe 3;
BA_ "GenSigCycleTime" SG_ 554 EstAxle4_LoadNormQltyLe 100;
BA_ "GenSigCycleTimeActive" SG_ 554 EstAxle4_LoadNormQltyLe 100;
BA_ "GenSigStartValue" SG_ 554 EstAxle4_LoadNormQltyLe 3;
BA_ "GenSigCycleTime" SG_ 554 EstAxle2_WhlRdEstQltyRi 100;
BA_ "GenSigCycleTimeActive" SG_ 554 EstAxle2_WhlRdEstQltyRi 100;
BA_ "GenSigStartValue" SG_ 554 EstAxle2_WhlRdEstQltyRi 3;
BA_ "GenSigCycleTime" SG_ 554 EstAxle6_LoadNormQltyLe 100;
BA_ "GenSigCycleTimeActive" SG_ 554 EstAxle6_LoadNormQltyLe 100;
BA_ "GenSigStartValue" SG_ 554 EstAxle6_LoadNormQltyLe 3;
BA_ "GenSigCycleTime" SG_ 554 EstAxle2_WhlRdEstRi 100;
BA_ "GenSigCycleTimeActive" SG_ 554 EstAxle2_WhlRdEstRi 100;
BA_ "GenSigStartValue" SG_ 554 EstAxle2_WhlRdEstRi 1023;
BA_ "GenSigCycleTime" SG_ 554 EstAxle3_WhlRdEstQltyRi 100;
BA_ "GenSigCycleTimeActive" SG_ 554 EstAxle3_WhlRdEstQltyRi 100;
BA_ "GenSigStartValue" SG_ 554 EstAxle3_WhlRdEstQltyRi 3;
BA_ "GenSigCycleTime" SG_ 554 EstAxle1_LoadNormLe 100;
BA_ "GenSigCycleTimeActive" SG_ 554 EstAxle1_LoadNormLe 100;
BA_ "GenSigStartValue" SG_ 554 EstAxle1_LoadNormLe 255;
BA_ "GenSigCycleTime" SG_ 554 EstAxle1_CRC 100;
BA_ "GenSigCycleTimeActive" SG_ 554 EstAxle1_CRC 100;
BA_ "GenSigStartValue" SG_ 554 EstAxle1_CRC 255;
BA_ "E2EDataId" SG_ 554 EstAxle1_CRC 209;
BA_ "E2EDataLength" SG_ 554 EstAxle1_CRC 56;
BA_ "E2EProfile" SG_ 554 EstAxle1_CRC "P01";
BA_ "GenSigCycleTime" SG_ 554 EstAxle5_WhlRdEstRi 100;
BA_ "GenSigCycleTimeActive" SG_ 554 EstAxle5_WhlRdEstRi 100;
BA_ "GenSigStartValue" SG_ 554 EstAxle5_WhlRdEstRi 1023;
BA_ "GenSigCycleTime" SG_ 554 EstAxle2_CRC 100;
BA_ "GenSigCycleTimeActive" SG_ 554 EstAxle2_CRC 100;
BA_ "GenSigStartValue" SG_ 554 EstAxle2_CRC 255;
BA_ "E2EDataId" SG_ 554 EstAxle2_CRC 210;
BA_ "E2EDataLength" SG_ 554 EstAxle2_CRC 56;
BA_ "E2EProfile" SG_ 554 EstAxle2_CRC "P01";
BA_ "GenSigCycleTime" SG_ 554 EstAxle1_LoadNormRi 100;
BA_ "GenSigCycleTimeActive" SG_ 554 EstAxle1_LoadNormRi 100;
BA_ "GenSigStartValue" SG_ 554 EstAxle1_LoadNormRi 255;
BA_ "GenSigCycleTime" SG_ 554 EstAxle2_WhlRdEstQltyLe 100;
BA_ "GenSigCycleTimeActive" SG_ 554 EstAxle2_WhlRdEstQltyLe 100;
BA_ "GenSigStartValue" SG_ 554 EstAxle2_WhlRdEstQltyLe 3;
BA_ "GenSigCycleTime" SG_ 554 EstAxle4_CRC 100;
BA_ "GenSigCycleTimeActive" SG_ 554 EstAxle4_CRC 100;
BA_ "GenSigStartValue" SG_ 554 EstAxle4_CRC 255;
BA_ "E2EDataId" SG_ 554 EstAxle4_CRC 212;
BA_ "E2EDataLength" SG_ 554 EstAxle4_CRC 56;
BA_ "E2EProfile" SG_ 554 EstAxle4_CRC "P01";
BA_ "GenSigCycleTime" SG_ 554 EstAxle3_LoadNormRi 100;
BA_ "GenSigCycleTimeActive" SG_ 554 EstAxle3_LoadNormRi 100;
BA_ "GenSigStartValue" SG_ 554 EstAxle3_LoadNormRi 255;
BA_ "GenSigCycleTime" SG_ 554 EstAxle5_WhlRdEstQltyLe 100;
BA_ "GenSigCycleTimeActive" SG_ 554 EstAxle5_WhlRdEstQltyLe 100;
BA_ "GenSigStartValue" SG_ 554 EstAxle5_WhlRdEstQltyLe 3;
BA_ "GenSigCycleTime" SG_ 554 EstAxle3_SqC 100;
BA_ "GenSigCycleTimeActive" SG_ 554 EstAxle3_SqC 100;
BA_ "GenSigStartValue" SG_ 554 EstAxle3_SqC 14;
BA_ "GenSigCycleTime" SG_ 554 EstAxle1_WhlRdEstLe 100;
BA_ "GenSigCycleTimeActive" SG_ 554 EstAxle1_WhlRdEstLe 100;
BA_ "GenSigStartValue" SG_ 554 EstAxle1_WhlRdEstLe 1023;
BA_ "GenSigCycleTime" SG_ 554 EstAxle4_LoadNormLe 100;
BA_ "GenSigCycleTimeActive" SG_ 554 EstAxle4_LoadNormLe 100;
BA_ "GenSigStartValue" SG_ 554 EstAxle4_LoadNormLe 255;
BA_ "GenSigCycleTime" SG_ 554 EstAxle1_SqC 100;
BA_ "GenSigCycleTimeActive" SG_ 554 EstAxle1_SqC 100;
BA_ "GenSigStartValue" SG_ 554 EstAxle1_SqC 14;
BA_ "GenSigCycleTime" SG_ 554 EstAxle1_WhlRdEstQltyRi 100;
BA_ "GenSigCycleTimeActive" SG_ 554 EstAxle1_WhlRdEstQltyRi 100;
BA_ "GenSigStartValue" SG_ 554 EstAxle1_WhlRdEstQltyRi 3;
BA_ "GenSigCycleTime" SG_ 554 EstAxle2_SqC 100;
BA_ "GenSigCycleTimeActive" SG_ 554 EstAxle2_SqC 100;
BA_ "GenSigStartValue" SG_ 554 EstAxle2_SqC 14;
BA_ "GenSigCycleTime" SG_ 554 EstAxle3_WhlRdEstLe 100;
BA_ "GenSigCycleTimeActive" SG_ 554 EstAxle3_WhlRdEstLe 100;
BA_ "GenSigStartValue" SG_ 554 EstAxle3_WhlRdEstLe 1023;
BA_ "GenSigCycleTime" SG_ 631 TrsmEngdForPropulsion_SqC 100;
BA_ "GenSigCycleTimeActive" SG_ 631 TrsmEngdForPropulsion_SqC 100;
BA_ "GenSigMaxLatency" SG_ 631 TrsmEngdForPropulsion_SqC 50;
BA_ "GenSigCycleTime" SG_ 631 TrsmEngdForPropulsion_Status 100;
BA_ "GenSigCycleTimeActive" SG_ 631 TrsmEngdForPropulsion_Status 100;
BA_ "GenSigStartValue" SG_ 631 TrsmEngdForPropulsion_Status 7;
BA_ "GenSigMaxLatency" SG_ 631 TrsmEngdForPropulsion_Status 50;
BA_ "GenSigCycleTime" SG_ 631 XPRGReqPropDemTc_SqC 100;
BA_ "GenSigCycleTimeActive" SG_ 631 XPRGReqPropDemTc_SqC 100;
BA_ "GenSigStartValue" SG_ 631 XPRGReqPropDemTc_SqC 14;
BA_ "GenSigMaxLatency" SG_ 631 XPRGReqPropDemTc_SqC 50;
BA_ "GenSigCycleTime" SG_ 631 TrsmEngdForPropulsion_CRC 100;
BA_ "GenSigCycleTimeActive" SG_ 631 TrsmEngdForPropulsion_CRC 100;
BA_ "GenSigMaxLatency" SG_ 631 TrsmEngdForPropulsion_CRC 50;
BA_ "E2EDataId" SG_ 631 TrsmEngdForPropulsion_CRC 292;
BA_ "E2EDataLength" SG_ 631 TrsmEngdForPropulsion_CRC 16;
BA_ "E2EProfile" SG_ 631 TrsmEngdForPropulsion_CRC "P01";
BA_ "GenSigCycleTime" SG_ 631 XPRGReqPropDemTl_TlPropControl 100;
BA_ "GenSigCycleTimeActive" SG_ 631 XPRGReqPropDemTl_TlPropControl 100;
BA_ "GenSigStartValue" SG_ 631 XPRGReqPropDemTl_TlPropControl 127;
BA_ "GenSigMaxLatency" SG_ 631 XPRGReqPropDemTl_TlPropControl 50;
BA_ "GenSigCycleTime" SG_ 631 XPRGReqMain_AddVlvRelIhnibition 100;
BA_ "GenSigCycleTimeActive" SG_ 631 XPRGReqMain_AddVlvRelIhnibition 100;
BA_ "GenSigMaxLatency" SG_ 631 XPRGReqMain_AddVlvRelIhnibition 50;
BA_ "GenSigCycleTime" SG_ 631 XPRGReqMain_PBValveCtrl 100;
BA_ "GenSigCycleTimeActive" SG_ 631 XPRGReqMain_PBValveCtrl 100;
BA_ "GenSigStartValue" SG_ 631 XPRGReqMain_PBValveCtrl 7;
BA_ "GenSigMaxLatency" SG_ 631 XPRGReqMain_PBValveCtrl 50;
BA_ "GenSigCycleTime" SG_ 631 DriverLocation_Status_ISig_3 100;
BA_ "GenSigCycleTimeActive" SG_ 631 DriverLocation_Status_ISig_3 100;
BA_ "GenSigStartValue" SG_ 631 DriverLocation_Status_ISig_3 15;
BA_ "GenSigMaxLatency" SG_ 631 DriverLocation_Status_ISig_3 50;
BA_ "GenSigCycleTime" SG_ 631 TachographVehicleSpeed 100;
BA_ "GenSigCycleTimeActive" SG_ 631 TachographVehicleSpeed 100;
BA_ "GenSigStartValue" SG_ 631 TachographVehicleSpeed 65535;
BA_ "GenSigMaxLatency" SG_ 631 TachographVehicleSpeed 50;
BA_ "GenSigCycleTime" SG_ 631 XPRsystemstate 100;
BA_ "GenSigCycleTimeActive" SG_ 631 XPRsystemstate 100;
BA_ "GenSigStartValue" SG_ 631 XPRsystemstate 255;
BA_ "GenSigCycleTime" SG_ 631 XPRGReqMain_AddValveCtrlMode 100;
BA_ "GenSigCycleTimeActive" SG_ 631 XPRGReqMain_AddValveCtrlMode 100;
BA_ "GenSigMaxLatency" SG_ 631 XPRGReqMain_AddValveCtrlMode 50;
BA_ "GenSigCycleTime" SG_ 631 XPRGReqMain_CRC 100;
BA_ "GenSigCycleTimeActive" SG_ 631 XPRGReqMain_CRC 100;
BA_ "GenSigStartValue" SG_ 631 XPRGReqMain_CRC 255;
BA_ "GenSigMaxLatency" SG_ 631 XPRGReqMain_CRC 50;
BA_ "E2EDataId" SG_ 631 XPRGReqMain_CRC 141;
BA_ "E2EDataLength" SG_ 631 XPRGReqMain_CRC 24;
BA_ "E2EProfile" SG_ 631 XPRGReqMain_CRC "P01";
BA_ "GenSigCycleTime" SG_ 631 XPRGReqMain_AddValveCtrl 100;
BA_ "GenSigCycleTimeActive" SG_ 631 XPRGReqMain_AddValveCtrl 100;
BA_ "GenSigStartValue" SG_ 631 XPRGReqMain_AddValveCtrl 7;
BA_ "GenSigMaxLatency" SG_ 631 XPRGReqMain_AddValveCtrl 50;
BA_ "GenSigCycleTime" SG_ 631 BacklightCmd_ISig_3 100;
BA_ "GenSigCycleTimeActive" SG_ 631 BacklightCmd_ISig_3 100;
BA_ "GenSigMaxLatency" SG_ 631 BacklightCmd_ISig_3 50;
BA_ "GenSigCycleTime" SG_ 631 XPRGReqPropDemTl_SqC 100;
BA_ "GenSigCycleTimeActive" SG_ 631 XPRGReqPropDemTl_SqC 100;
BA_ "GenSigStartValue" SG_ 631 XPRGReqPropDemTl_SqC 14;
BA_ "GenSigMaxLatency" SG_ 631 XPRGReqPropDemTl_SqC 50;
BA_ "GenSigCycleTime" SG_ 631 DoorsAjar_stat_ISig_3 100;
BA_ "GenSigCycleTimeActive" SG_ 631 DoorsAjar_stat_ISig_3 100;
BA_ "GenSigStartValue" SG_ 631 DoorsAjar_stat_ISig_3 7;
BA_ "GenSigCycleTime" SG_ 631 XPRGReqPropDemTl_CRC 100;
BA_ "GenSigCycleTimeActive" SG_ 631 XPRGReqPropDemTl_CRC 100;
BA_ "GenSigStartValue" SG_ 631 XPRGReqPropDemTl_CRC 255;
BA_ "GenSigMaxLatency" SG_ 631 XPRGReqPropDemTl_CRC 50;
BA_ "E2EDataId" SG_ 631 XPRGReqPropDemTl_CRC 143;
BA_ "E2EDataLength" SG_ 631 XPRGReqPropDemTl_CRC 24;
BA_ "E2EProfile" SG_ 631 XPRGReqPropDemTl_CRC "P01";
BA_ "GenSigCycleTime" SG_ 631 XPRGReqMain_SqC 100;
BA_ "GenSigCycleTimeActive" SG_ 631 XPRGReqMain_SqC 100;
BA_ "GenSigStartValue" SG_ 631 XPRGReqMain_SqC 14;
BA_ "GenSigMaxLatency" SG_ 631 XPRGReqMain_SqC 50;
BA_ "GenSigCycleTime" SG_ 631 XPRGReqPropDemTc_TypeControl 100;
BA_ "GenSigCycleTimeActive" SG_ 631 XPRGReqPropDemTc_TypeControl 100;
BA_ "GenSigStartValue" SG_ 631 XPRGReqPropDemTc_TypeControl 3;
BA_ "GenSigMaxLatency" SG_ 631 XPRGReqPropDemTc_TypeControl 50;
BA_ "GenSigCycleTime" SG_ 631 CartridgeChangedDrvrReset_rqst_I 100;
BA_ "GenSigCycleTimeActive" SG_ 631 CartridgeChangedDrvrReset_rqst_I 100;
BA_ "GenSigStartValue" SG_ 631 CartridgeChangedDrvrReset_rqst_I 3;
BA_ "GenSigMaxLatency" SG_ 631 CartridgeChangedDrvrReset_rqst_I 50;
BA_ "SystemSignalLongSymbol" SG_ 631 CartridgeChangedDrvrReset_rqst_I "CartridgeChangedDrvrReset_rqst_ISig_3";
BA_ "GenSigCycleTime" SG_ 631 DriverLocation_ConfidenceLvl_ISi 100;
BA_ "GenSigCycleTimeActive" SG_ 631 DriverLocation_ConfidenceLvl_ISi 100;
BA_ "GenSigStartValue" SG_ 631 DriverLocation_ConfidenceLvl_ISi 3;
BA_ "GenSigMaxLatency" SG_ 631 DriverLocation_ConfidenceLvl_ISi 50;
BA_ "SystemSignalLongSymbol" SG_ 631 DriverLocation_ConfidenceLvl_ISi "DriverLocation_ConfidenceLvl_ISig_3";
BA_ "GenSigCycleTime" SG_ 631 DriverLocation_CRC_ISig_3 100;
BA_ "GenSigCycleTimeActive" SG_ 631 DriverLocation_CRC_ISig_3 100;
BA_ "GenSigMaxLatency" SG_ 631 DriverLocation_CRC_ISig_3 50;
BA_ "E2EDataId" SG_ 631 DriverLocation_CRC_ISig_3 243;
BA_ "E2EDataLength" SG_ 631 DriverLocation_CRC_ISig_3 24;
BA_ "E2EProfile" SG_ 631 DriverLocation_CRC_ISig_3 "P01";
BA_ "GenSigCycleTime" SG_ 631 XPRGReqPropDemTl_TypeControl 100;
BA_ "GenSigCycleTimeActive" SG_ 631 XPRGReqPropDemTl_TypeControl 100;
BA_ "GenSigStartValue" SG_ 631 XPRGReqPropDemTl_TypeControl 3;
BA_ "GenSigMaxLatency" SG_ 631 XPRGReqPropDemTl_TypeControl 50;
BA_ "GenSigCycleTime" SG_ 631 XPRGReqMain_RequestPriority 100;
BA_ "GenSigCycleTimeActive" SG_ 631 XPRGReqMain_RequestPriority 100;
BA_ "GenSigStartValue" SG_ 631 XPRGReqMain_RequestPriority 3;
BA_ "GenSigMaxLatency" SG_ 631 XPRGReqMain_RequestPriority 50;
BA_ "GenSigCycleTime" SG_ 631 XPRGReqPropDemTc_CRC 100;
BA_ "GenSigCycleTimeActive" SG_ 631 XPRGReqPropDemTc_CRC 100;
BA_ "GenSigStartValue" SG_ 631 XPRGReqPropDemTc_CRC 255;
BA_ "GenSigMaxLatency" SG_ 631 XPRGReqPropDemTc_CRC 50;
BA_ "E2EDataId" SG_ 631 XPRGReqPropDemTc_CRC 142;
BA_ "E2EDataLength" SG_ 631 XPRGReqPropDemTc_CRC 24;
BA_ "E2EProfile" SG_ 631 XPRGReqPropDemTc_CRC "P01";
BA_ "GenSigCycleTime" SG_ 631 FuncIndIlluminationLevel_ISig_3 100;
BA_ "GenSigCycleTimeActive" SG_ 631 FuncIndIlluminationLevel_ISig_3 100;
BA_ "GenSigStartValue" SG_ 631 FuncIndIlluminationLevel_ISig_3 1;
BA_ "GenSigMaxLatency" SG_ 631 FuncIndIlluminationLevel_ISig_3 50;
BA_ "GenSigCycleTime" SG_ 631 TrailerABSStatus_ISig_3 100;
BA_ "GenSigCycleTimeActive" SG_ 631 TrailerABSStatus_ISig_3 100;
BA_ "GenSigStartValue" SG_ 631 TrailerABSStatus_ISig_3 3;
BA_ "GenSigCycleTime" SG_ 631 DriverLocation_SqC_ISig_3 100;
BA_ "GenSigCycleTimeActive" SG_ 631 DriverLocation_SqC_ISig_3 100;
BA_ "GenSigMaxLatency" SG_ 631 DriverLocation_SqC_ISig_3 50;
BA_ "GenSigCycleTime" SG_ 631 XPRGReqMain_PBVlvRelInhibition 100;
BA_ "GenSigCycleTimeActive" SG_ 631 XPRGReqMain_PBVlvRelInhibition 100;
BA_ "GenSigMaxLatency" SG_ 631 XPRGReqMain_PBVlvRelInhibition 50;
BA_ "GenSigCycleTime" SG_ 631 XPRGReqPropDemTc_TcPropControl 100;
BA_ "GenSigCycleTimeActive" SG_ 631 XPRGReqPropDemTc_TcPropControl 100;
BA_ "GenSigStartValue" SG_ 631 XPRGReqPropDemTc_TcPropControl 127;
BA_ "GenSigMaxLatency" SG_ 631 XPRGReqPropDemTc_TcPropControl 50;
BA_ "GenSigCycleTime" SG_ 1448 TotalVehicleDistanceHighRes_ISig 100;
BA_ "GenSigCycleTimeActive" SG_ 1448 TotalVehicleDistanceHighRes_ISig 100;
BA_ "GenSigStartValue" SG_ 1448 TotalVehicleDistanceHighRes_ISig 4294967295;
BA_ "SystemSignalLongSymbol" SG_ 1448 TotalVehicleDistanceHighRes_ISig "TotalVehicleDistanceHighRes_ISig_3";
BA_ "GenSigCycleTime" SG_ 1448 AmbientAirTemperature_ISig_3 100;
BA_ "GenSigCycleTimeActive" SG_ 1448 AmbientAirTemperature_ISig_3 100;
BA_ "GenSigStartValue" SG_ 1448 AmbientAirTemperature_ISig_3 65535;
BA_ "GenSigCycleTime" SG_ 1319 YearUTC_ISig_3 100;
BA_ "GenSigCycleTimeActive" SG_ 1319 YearUTC_ISig_3 100;
BA_ "GenSigStartValue" SG_ 1319 YearUTC_ISig_3 255;
BA_ "GenSigCycleTime" SG_ 1319 SecondsUTC_ISig_3 100;
BA_ "GenSigCycleTimeActive" SG_ 1319 SecondsUTC_ISig_3 100;
BA_ "GenSigStartValue" SG_ 1319 SecondsUTC_ISig_3 255;
BA_ "GenSigCycleTime" SG_ 1319 DayUTC_ISig_3 100;
BA_ "GenSigCycleTimeActive" SG_ 1319 DayUTC_ISig_3 100;
BA_ "GenSigStartValue" SG_ 1319 DayUTC_ISig_3 255;
BA_ "GenSigCycleTime" SG_ 1319 MonthUTC_ISig_3 100;
BA_ "GenSigCycleTimeActive" SG_ 1319 MonthUTC_ISig_3 100;
BA_ "GenSigStartValue" SG_ 1319 MonthUTC_ISig_3 255;
BA_ "GenSigCycleTime" SG_ 1319 HoursUTC_ISig_3 100;
BA_ "GenSigCycleTimeActive" SG_ 1319 HoursUTC_ISig_3 100;
BA_ "GenSigStartValue" SG_ 1319 HoursUTC_ISig_3 255;
BA_ "GenSigCycleTime" SG_ 1319 MinutesUTC_ISig_3 100;
BA_ "GenSigCycleTimeActive" SG_ 1319 MinutesUTC_ISig_3 100;
BA_ "GenSigStartValue" SG_ 1319 MinutesUTC_ISig_3 255;
BA_ "GenSigCycleTime" SG_ 1447 AirDryerCartdgeTypeReset 100;
BA_ "GenSigCycleTimeActive" SG_ 1447 AirDryerCartdgeTypeReset 100;
BA_ "GenSigStartValue" SG_ 1447 AirDryerCartdgeTypeReset 15;
BA_ "GenSigCycleTime" SG_ 1447 FasDampingSetting_rqst_ISig_3 100;
BA_ "GenSigCycleTimeActive" SG_ 1447 FasDampingSetting_rqst_ISig_3 100;
BA_ "GenSigStartValue" SG_ 1447 FasDampingSetting_rqst_ISig_3 31;
BA_ "GenSigMaxLatency" SG_ 1447 FasDampingSetting_rqst_ISig_3 1000;
BA_ "GenSigCycleTime" SG_ 1447 DriverMemory_rqst_ISig_3 100;
BA_ "GenSigCycleTimeActive" SG_ 1447 DriverMemory_rqst_ISig_3 100;
BA_ "GenSigStartValue" SG_ 1447 DriverMemory_rqst_ISig_3 31;
BA_ "GenSigMaxLatency" SG_ 1447 DriverMemory_rqst_ISig_3 1000;
BA_ "GenSigCycleTime" SG_ 1447 FasDriver_rqst_ISig_3 100;
BA_ "GenSigCycleTimeActive" SG_ 1447 FasDriver_rqst_ISig_3 100;
BA_ "GenSigStartValue" SG_ 1447 FasDriver_rqst_ISig_3 15;
BA_ "GenSigMaxLatency" SG_ 1447 FasDriver_rqst_ISig_3 1000;
BA_ "GenSigCycleTime" SG_ 1447 FasLowSpeedReturnSetting_rqst_IS 100;
BA_ "GenSigCycleTimeActive" SG_ 1447 FasLowSpeedReturnSetting_rqst_IS 100;
BA_ "GenSigStartValue" SG_ 1447 FasLowSpeedReturnSetting_rqst_IS 31;
BA_ "GenSigMaxLatency" SG_ 1447 FasLowSpeedReturnSetting_rqst_IS 1000;
BA_ "SystemSignalLongSymbol" SG_ 1447 FasLowSpeedReturnSetting_rqst_IS "FasLowSpeedReturnSetting_rqst_ISig_3";
BA_ "GenSigCycleTime" SG_ 1447 FasPersonalSettingsButton_rqst_I 100;
BA_ "GenSigCycleTimeActive" SG_ 1447 FasPersonalSettingsButton_rqst_I 100;
BA_ "GenSigStartValue" SG_ 1447 FasPersonalSettingsButton_rqst_I 7;
BA_ "GenSigMaxLatency" SG_ 1447 FasPersonalSettingsButton_rqst_I 1000;
BA_ "SystemSignalLongSymbol" SG_ 1447 FasPersonalSettingsButton_rqst_I "FasPersonalSettingsButton_rqst_ISig_3";
BA_ "GenSigCycleTime" SG_ 1447 FasStiffnessCurveSetting_rqst_IS 100;
BA_ "GenSigCycleTimeActive" SG_ 1447 FasStiffnessCurveSetting_rqst_IS 100;
BA_ "GenSigStartValue" SG_ 1447 FasStiffnessCurveSetting_rqst_IS 31;
BA_ "GenSigMaxLatency" SG_ 1447 FasStiffnessCurveSetting_rqst_IS 1000;
BA_ "SystemSignalLongSymbol" SG_ 1447 FasStiffnessCurveSetting_rqst_IS "FasStiffnessCurveSetting_rqst_ISig_3";
BA_ "GenSigCycleTime" SG_ 1447 FasUsrDefinedStorage_rqst_ISig_3 100;
BA_ "GenSigCycleTimeActive" SG_ 1447 FasUsrDefinedStorage_rqst_ISig_3 100;
BA_ "GenSigStartValue" SG_ 1447 FasUsrDefinedStorage_rqst_ISig_3 3;
BA_ "GenSigMaxLatency" SG_ 1447 FasUsrDefinedStorage_rqst_ISig_3 1000;
BA_ "GenSigCycleTime" SG_ 1447 FasManualOffsetSetting_rqst_ISig 100;
BA_ "GenSigCycleTimeActive" SG_ 1447 FasManualOffsetSetting_rqst_ISig 100;
BA_ "GenSigStartValue" SG_ 1447 FasManualOffsetSetting_rqst_ISig 31;
BA_ "GenSigMaxLatency" SG_ 1447 FasManualOffsetSetting_rqst_ISig 1000;
BA_ "SystemSignalLongSymbol" SG_ 1447 FasManualOffsetSetting_rqst_ISig "FasManualOffsetSetting_rqst_ISig_3";
BA_ "GenSigCycleTime" SG_ 1447 FasStiffStraightSetting_rqst_ISi 100;
BA_ "GenSigCycleTimeActive" SG_ 1447 FasStiffStraightSetting_rqst_ISi 100;
BA_ "GenSigStartValue" SG_ 1447 FasStiffStraightSetting_rqst_ISi 31;
BA_ "GenSigMaxLatency" SG_ 1447 FasStiffStraightSetting_rqst_ISi 1000;
BA_ "SystemSignalLongSymbol" SG_ 1447 FasStiffStraightSetting_rqst_ISi "FasStiffStraightSetting_rqst_ISig_3";
BA_ "GenSigCycleTime" SG_ 1034 RelativeLevelFrontAxleRight_ISig 100;
BA_ "GenSigCycleTimeActive" SG_ 1034 RelativeLevelFrontAxleRight_ISig 100;
BA_ "GenSigStartValue" SG_ 1034 RelativeLevelFrontAxleRight_ISig 65535;
BA_ "SystemSignalLongSymbol" SG_ 1034 RelativeLevelFrontAxleRight_ISig "RelativeLevelFrontAxleRight_ISig_3";
BA_ "GenSigCycleTime" SG_ 1034 RelativeLevelFrontAxleLeft_ISig_ 100;
BA_ "GenSigCycleTimeActive" SG_ 1034 RelativeLevelFrontAxleLeft_ISig_ 100;
BA_ "GenSigStartValue" SG_ 1034 RelativeLevelFrontAxleLeft_ISig_ 65535;
BA_ "GenSigMaxLatency" SG_ 1034 RelativeLevelFrontAxleLeft_ISig_ 100;
BA_ "SystemSignalLongSymbol" SG_ 1034 RelativeLevelFrontAxleLeft_ISig_ "RelativeLevelFrontAxleLeft_ISig_3";
BA_ "GenSigCycleTime" SG_ 1034 FrontAxle1Load_ISig_3 100;
BA_ "GenSigCycleTimeActive" SG_ 1034 FrontAxle1Load_ISig_3 100;
BA_ "GenSigStartValue" SG_ 1034 FrontAxle1Load_ISig_3 65535;
BA_ "GenSigMaxLatency" SG_ 1034 FrontAxle1Load_ISig_3 100;
BA_ "GenSigCycleTime" SG_ 1034 PusherAxleLoad_ISig_3 100;
BA_ "GenSigCycleTimeActive" SG_ 1034 PusherAxleLoad_ISig_3 100;
BA_ "GenSigStartValue" SG_ 1034 PusherAxleLoad_ISig_3 65535;
BA_ "GenSigMaxLatency" SG_ 1034 PusherAxleLoad_ISig_3 100;
BA_ "GenSigCycleTime" SG_ 1034 AirConsumptionStatus 100;
BA_ "GenSigCycleTimeActive" SG_ 1034 AirConsumptionStatus 100;
BA_ "GenSigStartValue" SG_ 1034 AirConsumptionStatus 3;
BA_ "GenSigMaxLatency" SG_ 1034 AirConsumptionStatus 100;
BA_ "GenSigCycleTime" SG_ 1034 UnloadValveOperationRqst 100;
BA_ "GenSigCycleTimeActive" SG_ 1034 UnloadValveOperationRqst 100;
BA_ "GenSigStartValue" SG_ 1034 UnloadValveOperationRqst 3;
BA_ "GenSigMaxLatency" SG_ 1034 UnloadValveOperationRqst 100;
BA_ "GenSigCycleTime" SG_ 1034 SecondaryDriveAxleLoad_ISig_3 100;
BA_ "GenSigCycleTimeActive" SG_ 1034 SecondaryDriveAxleLoad_ISig_3 100;
BA_ "GenSigStartValue" SG_ 1034 SecondaryDriveAxleLoad_ISig_3 65535;
BA_ "GenSigMaxLatency" SG_ 1034 SecondaryDriveAxleLoad_ISig_3 100;
BA_ "GenSigCycleTime" SG_ 1034 RelativeLevelRearAxleLeft_ISig_3 100;
BA_ "GenSigCycleTimeActive" SG_ 1034 RelativeLevelRearAxleLeft_ISig_3 100;
BA_ "GenSigStartValue" SG_ 1034 RelativeLevelRearAxleLeft_ISig_3 65535;
BA_ "GenSigCycleTime" SG_ 1034 TagAxleLoad_ISig_3 100;
BA_ "GenSigCycleTimeActive" SG_ 1034 TagAxleLoad_ISig_3 100;
BA_ "GenSigStartValue" SG_ 1034 TagAxleLoad_ISig_3 65535;
BA_ "GenSigMaxLatency" SG_ 1034 TagAxleLoad_ISig_3 100;
BA_ "GenSigCycleTime" SG_ 1034 TransmissionCurrentGear_ISig_3 100;
BA_ "GenSigCycleTimeActive" SG_ 1034 TransmissionCurrentGear_ISig_3 100;
BA_ "GenSigStartValue" SG_ 1034 TransmissionCurrentGear_ISig_3 255;
BA_ "GenSigMaxLatency" SG_ 1034 TransmissionCurrentGear_ISig_3 100;
BA_ "GenSigCycleTime" SG_ 1034 ContTrailerBrake_MsgCounter 100;
BA_ "GenSigCycleTimeActive" SG_ 1034 ContTrailerBrake_MsgCounter 100;
BA_ "GenSigStartValue" SG_ 1034 ContTrailerBrake_MsgCounter 15;
BA_ "GenSigMaxLatency" SG_ 1034 ContTrailerBrake_MsgCounter 100;
BA_ "GenSigCycleTime" SG_ 1034 AirProductionPressureRangeMode 100;
BA_ "GenSigCycleTimeActive" SG_ 1034 AirProductionPressureRangeMode 100;
BA_ "GenSigStartValue" SG_ 1034 AirProductionPressureRangeMode 15;
BA_ "GenSigMaxLatency" SG_ 1034 AirProductionPressureRangeMode 100;
BA_ "GenSigCycleTime" SG_ 1034 BrakeSwitch_ISig_3 100;
BA_ "GenSigCycleTimeActive" SG_ 1034 BrakeSwitch_ISig_3 100;
BA_ "GenSigStartValue" SG_ 1034 BrakeSwitch_ISig_3 3;
BA_ "GenSigCycleTime" SG_ 1034 FrontAxle2Load_ISig_3 100;
BA_ "GenSigCycleTimeActive" SG_ 1034 FrontAxle2Load_ISig_3 100;
BA_ "GenSigStartValue" SG_ 1034 FrontAxle2Load_ISig_3 65535;
BA_ "GenSigMaxLatency" SG_ 1034 FrontAxle2Load_ISig_3 100;
BA_ "GenSigCycleTime" SG_ 1034 DriveAxleLoad_ISig_3 100;
BA_ "GenSigCycleTimeActive" SG_ 1034 DriveAxleLoad_ISig_3 100;
BA_ "GenSigStartValue" SG_ 1034 DriveAxleLoad_ISig_3 65535;
BA_ "GenSigMaxLatency" SG_ 1034 DriveAxleLoad_ISig_3 100;
BA_ "GenSigCycleTime" SG_ 1034 ContTrailerBrake_MsgChecksum 100;
BA_ "GenSigCycleTimeActive" SG_ 1034 ContTrailerBrake_MsgChecksum 100;
BA_ "GenSigStartValue" SG_ 1034 ContTrailerBrake_MsgChecksum 31;
BA_ "GenSigMaxLatency" SG_ 1034 ContTrailerBrake_MsgChecksum 100;
BA_ "GenSigCycleTime" SG_ 1034 TertiaryDriveAxleLoad_ISig_3 100;
BA_ "GenSigCycleTimeActive" SG_ 1034 TertiaryDriveAxleLoad_ISig_3 100;
BA_ "GenSigStartValue" SG_ 1034 TertiaryDriveAxleLoad_ISig_3 65535;
BA_ "GenSigMaxLatency" SG_ 1034 TertiaryDriveAxleLoad_ISig_3 250;
BA_ "GenSigCycleTime" SG_ 1034 ElAirCompActualSpeed 100;
BA_ "GenSigCycleTimeActive" SG_ 1034 ElAirCompActualSpeed 100;
BA_ "GenSigStartValue" SG_ 1034 ElAirCompActualSpeed 255;
BA_ "GenSigMaxLatency" SG_ 1034 ElAirCompActualSpeed 100;
BA_ "GenSigCycleTime" SG_ 1034 ElAirCompOperationStat 100;
BA_ "GenSigCycleTimeActive" SG_ 1034 ElAirCompOperationStat 100;
BA_ "GenSigStartValue" SG_ 1034 ElAirCompOperationStat 7;
BA_ "GenSigMaxLatency" SG_ 1034 ElAirCompOperationStat 100;
BA_ "GenSigCycleTime" SG_ 1034 VIN_rqst_ISig_3 100;
BA_ "GenSigCycleTimeActive" SG_ 1034 VIN_rqst_ISig_3 100;
BA_ "GenSigMaxLatency" SG_ 1034 VIN_rqst_ISig_3 100;
BA_ "GenSigCycleTime" SG_ 1034 TrailerConnected_ISig_3 100;
BA_ "GenSigCycleTimeActive" SG_ 1034 TrailerConnected_ISig_3 100;
BA_ "GenSigStartValue" SG_ 1034 TrailerConnected_ISig_3 3;
BA_ "GenSigCycleTime" SG_ 1034 ContTrailerBrake_Request 100;
BA_ "GenSigCycleTimeActive" SG_ 1034 ContTrailerBrake_Request 100;
BA_ "GenSigStartValue" SG_ 1034 ContTrailerBrake_Request 7;
BA_ "GenSigMaxLatency" SG_ 1034 ContTrailerBrake_Request 100;
BA_ "GenSigCycleTime" SG_ 1034 RelativeLevelRearAxleRight_ISig_ 100;
BA_ "GenSigCycleTimeActive" SG_ 1034 RelativeLevelRearAxleRight_ISig_ 100;
BA_ "GenSigStartValue" SG_ 1034 RelativeLevelRearAxleRight_ISig_ 65535;
BA_ "SystemSignalLongSymbol" SG_ 1034 RelativeLevelRearAxleRight_ISig_ "RelativeLevelRearAxleRight_ISig_3";
BA_ "GenSigCycleTime" SG_ 426 ChangeKneelACK_ISig_3 100;
BA_ "GenSigCycleTimeActive" SG_ 426 ChangeKneelACK_ISig_3 100;
BA_ "GenSigStartValue" SG_ 426 ChangeKneelACK_ISig_3 3;
BA_ "GenSigMaxLatency" SG_ 426 ChangeKneelACK_ISig_3 20;
BA_ "GenSigCycleTime" SG_ 426 EngineSpeed_ISig_3 100;
BA_ "GenSigCycleTimeActive" SG_ 426 EngineSpeed_ISig_3 100;
BA_ "GenSigStartValue" SG_ 426 EngineSpeed_ISig_3 65535;
BA_ "GenSigMaxLatency" SG_ 426 EngineSpeed_ISig_3 20;
BA_ "GenSigCycleTime" SG_ 426 SecuredNeutralPosition_ISig_3 100;
BA_ "GenSigCycleTimeActive" SG_ 426 SecuredNeutralPosition_ISig_3 100;
BA_ "GenSigStartValue" SG_ 426 SecuredNeutralPosition_ISig_3 3;
BA_ "GenSigCycleTime" SG_ 426 LiftAxle1PositionStatus_ISig_3 100;
BA_ "GenSigCycleTimeActive" SG_ 426 LiftAxle1PositionStatus_ISig_3 100;
BA_ "GenSigStartValue" SG_ 426 LiftAxle1PositionStatus_ISig_3 7;
BA_ "GenSigMaxLatency" SG_ 426 LiftAxle1PositionStatus_ISig_3 20;
BA_ "GenSigCycleTime" SG_ 426 FrontFerryFunctionCmd_ISig_3 100;
BA_ "GenSigCycleTimeActive" SG_ 426 FrontFerryFunctionCmd_ISig_3 100;
BA_ "GenSigStartValue" SG_ 426 FrontFerryFunctionCmd_ISig_3 7;
BA_ "GenSigMaxLatency" SG_ 426 FrontFerryFunctionCmd_ISig_3 20;
BA_ "GenSigCycleTime" SG_ 426 ReverseGearEngaged_ISig_3 100;
BA_ "GenSigCycleTimeActive" SG_ 426 ReverseGearEngaged_ISig_3 100;
BA_ "GenSigStartValue" SG_ 426 ReverseGearEngaged_ISig_3 3;
BA_ "GenSigMaxLatency" SG_ 426 ReverseGearEngaged_ISig_3 20;
BA_ "GenSigCycleTime" SG_ 426 AirDumpStatus_ISig_3 100;
BA_ "GenSigCycleTimeActive" SG_ 426 AirDumpStatus_ISig_3 100;
BA_ "GenSigStartValue" SG_ 426 AirDumpStatus_ISig_3 7;
BA_ "GenSigMaxLatency" SG_ 426 AirDumpStatus_ISig_3 20;
BA_ "GenSigCycleTime" SG_ 426 EngineActiveStatus_ISig_3 100;
BA_ "GenSigCycleTimeActive" SG_ 426 EngineActiveStatus_ISig_3 100;
BA_ "GenSigStartValue" SG_ 426 EngineActiveStatus_ISig_3 15;
BA_ "GenSigMaxLatency" SG_ 426 EngineActiveStatus_ISig_3 20;
BA_ "GenSigCycleTime" SG_ 426 FerryFunctionStatus_ISig_3 100;
BA_ "GenSigCycleTimeActive" SG_ 426 FerryFunctionStatus_ISig_3 100;
BA_ "GenSigStartValue" SG_ 426 FerryFunctionStatus_ISig_3 7;
BA_ "GenSigMaxLatency" SG_ 426 FerryFunctionStatus_ISig_3 20;
BA_ "GenSigCycleTime" SG_ 426 PitchAngleRef_ISig_3 100;
BA_ "GenSigCycleTimeActive" SG_ 426 PitchAngleRef_ISig_3 100;
BA_ "GenSigStartValue" SG_ 426 PitchAngleRef_ISig_3 65535;
BA_ "GenSigMaxLatency" SG_ 426 PitchAngleRef_ISig_3 20;
BA_ "GenSigCycleTime" SG_ 426 KneelingInformation_ISig_3 100;
BA_ "GenSigCycleTimeActive" SG_ 426 KneelingInformation_ISig_3 100;
BA_ "GenSigStartValue" SG_ 426 KneelingInformation_ISig_3 15;
BA_ "GenSigMaxLatency" SG_ 426 KneelingInformation_ISig_3 20;
BA_ "GenSigCycleTime" SG_ 426 FASHapticFeedbackRequest 100;
BA_ "GenSigCycleTimeActive" SG_ 426 FASHapticFeedbackRequest 100;
BA_ "GenSigStartValue" SG_ 426 FASHapticFeedbackRequest 15;
BA_ "GenSigMaxLatency" SG_ 426 FASHapticFeedbackRequest 20;
BA_ "GenSigCycleTime" SG_ 426 HeightControlMode_ISig_3 100;
BA_ "GenSigCycleTimeActive" SG_ 426 HeightControlMode_ISig_3 100;
BA_ "GenSigStartValue" SG_ 426 HeightControlMode_ISig_3 15;
BA_ "GenSigMaxLatency" SG_ 426 HeightControlMode_ISig_3 20;
BA_ "GenSigCycleTime" SG_ 426 LoadDistributionFuncSelected_ISi 100;
BA_ "GenSigCycleTimeActive" SG_ 426 LoadDistributionFuncSelected_ISi 100;
BA_ "GenSigStartValue" SG_ 426 LoadDistributionFuncSelected_ISi 15;
BA_ "GenSigMaxLatency" SG_ 426 LoadDistributionFuncSelected_ISi 20;
BA_ "SystemSignalLongSymbol" SG_ 426 LoadDistributionFuncSelected_ISi "LoadDistributionFuncSelected_ISig_3";
BA_ "GenSigCycleTime" SG_ 426 PitchAngle_ISig_3 100;
BA_ "GenSigCycleTimeActive" SG_ 426 PitchAngle_ISig_3 100;
BA_ "GenSigStartValue" SG_ 426 PitchAngle_ISig_3 65535;
BA_ "GenSigMaxLatency" SG_ 426 PitchAngle_ISig_3 20;
BA_ "GenSigCycleTime" SG_ 426 RollEndPositionStatus_ISig_3 100;
BA_ "GenSigCycleTimeActive" SG_ 426 RollEndPositionStatus_ISig_3 100;
BA_ "GenSigStartValue" SG_ 426 RollEndPositionStatus_ISig_3 7;
BA_ "GenSigMaxLatency" SG_ 426 RollEndPositionStatus_ISig_3 20;
BA_ "GenSigCycleTime" SG_ 426 SupplyPressure_ISig_3 100;
BA_ "GenSigCycleTimeActive" SG_ 426 SupplyPressure_ISig_3 100;
BA_ "GenSigStartValue" SG_ 426 SupplyPressure_ISig_3 255;
BA_ "GenSigMaxLatency" SG_ 426 SupplyPressure_ISig_3 20;
BA_ "GenSigCycleTime" SG_ 426 WheelBasedVehicleSpeed_ISig_3 100;
BA_ "GenSigCycleTimeActive" SG_ 426 WheelBasedVehicleSpeed_ISig_3 100;
BA_ "GenSigStartValue" SG_ 426 WheelBasedVehicleSpeed_ISig_3 65535;
BA_ "GenSigMaxLatency" SG_ 426 WheelBasedVehicleSpeed_ISig_3 20;
BA_ "GenSigCycleTime" SG_ 426 XBRSystemState2_Status 100;
BA_ "GenSigCycleTimeActive" SG_ 426 XBRSystemState2_Status 100;
BA_ "GenSigStartValue" SG_ 426 XBRSystemState2_Status 3;
BA_ "GenSigCycleTime" SG_ 426 RearAxle2DiffLock_stat_ISig_3 100;
BA_ "GenSigCycleTimeActive" SG_ 426 RearAxle2DiffLock_stat_ISig_3 100;
BA_ "GenSigStartValue" SG_ 426 RearAxle2DiffLock_stat_ISig_3 3;
BA_ "GenSigMaxLatency" SG_ 426 RearAxle2DiffLock_stat_ISig_3 20;
BA_ "GenSigCycleTime" SG_ 426 KneelingStatusHMI_ISig_3 100;
BA_ "GenSigCycleTimeActive" SG_ 426 KneelingStatusHMI_ISig_3 100;
BA_ "GenSigStartValue" SG_ 426 KneelingStatusHMI_ISig_3 3;
BA_ "GenSigMaxLatency" SG_ 426 KneelingStatusHMI_ISig_3 20;
BA_ "GenSigCycleTime" SG_ 426 HeightAdjustmentAllowed_ISig_3 100;
BA_ "GenSigCycleTimeActive" SG_ 426 HeightAdjustmentAllowed_ISig_3 100;
BA_ "GenSigStartValue" SG_ 426 HeightAdjustmentAllowed_ISig_3 3;
BA_ "GenSigMaxLatency" SG_ 426 HeightAdjustmentAllowed_ISig_3 20;
BA_ "GenSigCycleTime" SG_ 426 RideHeightStatus_ISig_3 100;
BA_ "GenSigCycleTimeActive" SG_ 426 RideHeightStatus_ISig_3 100;
BA_ "GenSigStartValue" SG_ 426 RideHeightStatus_ISig_3 15;
BA_ "GenSigMaxLatency" SG_ 426 RideHeightStatus_ISig_3 20;
BA_ "GenSigCycleTime" SG_ 426 CentralRearDiffLock_stat_ISig_3 100;
BA_ "GenSigCycleTimeActive" SG_ 426 CentralRearDiffLock_stat_ISig_3 100;
BA_ "GenSigStartValue" SG_ 426 CentralRearDiffLock_stat_ISig_3 3;
BA_ "GenSigMaxLatency" SG_ 426 CentralRearDiffLock_stat_ISig_3 20;
BA_ "GenSigCycleTime" SG_ 426 XBRSystemState2_CRC 100;
BA_ "GenSigCycleTimeActive" SG_ 426 XBRSystemState2_CRC 100;
BA_ "GenSigStartValue" SG_ 426 XBRSystemState2_CRC 255;
BA_ "E2EDataId" SG_ 426 XBRSystemState2_CRC 323;
BA_ "E2EDataLength" SG_ 426 XBRSystemState2_CRC 16;
BA_ "E2EProfile" SG_ 426 XBRSystemState2_CRC "P01";
BA_ "GenSigCycleTime" SG_ 426 LiftAxle2PositionStatus_ISig_3 100;
BA_ "GenSigCycleTimeActive" SG_ 426 LiftAxle2PositionStatus_ISig_3 100;
BA_ "GenSigStartValue" SG_ 426 LiftAxle2PositionStatus_ISig_3 7;
BA_ "GenSigMaxLatency" SG_ 426 LiftAxle2PositionStatus_ISig_3 20;
BA_ "GenSigCycleTime" SG_ 426 RampHeightOutsideTargetRange_ISi 100;
BA_ "GenSigCycleTimeActive" SG_ 426 RampHeightOutsideTargetRange_ISi 100;
BA_ "GenSigStartValue" SG_ 426 RampHeightOutsideTargetRange_ISi 7;
BA_ "GenSigMaxLatency" SG_ 426 RampHeightOutsideTargetRange_ISi 20;
BA_ "SystemSignalLongSymbol" SG_ 426 RampHeightOutsideTargetRange_ISi "RampHeightOutsideTargetRange_ISig_3";
BA_ "GenSigCycleTime" SG_ 426 DirInd_Rear_Status_ISig_3 100;
BA_ "GenSigCycleTimeActive" SG_ 426 DirInd_Rear_Status_ISig_3 100;
BA_ "GenSigStartValue" SG_ 426 DirInd_Rear_Status_ISig_3 7;
BA_ "GenSigMaxLatency" SG_ 426 DirInd_Rear_Status_ISig_3 20;
BA_ "GenSigCycleTime" SG_ 426 ExternalRequestManualStiffness 100;
BA_ "GenSigCycleTimeActive" SG_ 426 ExternalRequestManualStiffness 100;
BA_ "GenSigStartValue" SG_ 426 ExternalRequestManualStiffness 15;
BA_ "GenSigMaxLatency" SG_ 426 ExternalRequestManualStiffness 20;
BA_ "GenSigCycleTime" SG_ 426 PneumaticTrailerBrakeStatus_ISig 100;
BA_ "GenSigCycleTimeActive" SG_ 426 PneumaticTrailerBrakeStatus_ISig 100;
BA_ "GenSigStartValue" SG_ 426 PneumaticTrailerBrakeStatus_ISig 3;
BA_ "SystemSignalLongSymbol" SG_ 426 PneumaticTrailerBrakeStatus_ISig "PneumaticTrailerBrakeStatus_ISig_3";
BA_ "GenSigCycleTime" SG_ 426 GearLeverPosition_ISig_3 100;
BA_ "GenSigCycleTimeActive" SG_ 426 GearLeverPosition_ISig_3 100;
BA_ "GenSigStartValue" SG_ 426 GearLeverPosition_ISig_3 15;
BA_ "GenSigMaxLatency" SG_ 426 GearLeverPosition_ISig_3 20;
BA_ "GenSigCycleTime" SG_ 426 VehicleDistanceRollingCounter 100;
BA_ "GenSigCycleTimeActive" SG_ 426 VehicleDistanceRollingCounter 100;
BA_ "GenSigStartValue" SG_ 426 VehicleDistanceRollingCounter 65535;
BA_ "GenSigMaxLatency" SG_ 426 VehicleDistanceRollingCounter 50;
BA_ "GenSigCycleTime" SG_ 426 BackToDriveReqACK_ISig_3 100;
BA_ "GenSigCycleTimeActive" SG_ 426 BackToDriveReqACK_ISig_3 100;
BA_ "GenSigStartValue" SG_ 426 BackToDriveReqACK_ISig_3 3;
BA_ "GenSigMaxLatency" SG_ 426 BackToDriveReqACK_ISig_3 20;
BA_ "GenSigCycleTime" SG_ 426 XBRSystemState2_SqC 100;
BA_ "GenSigCycleTimeActive" SG_ 426 XBRSystemState2_SqC 100;
BA_ "GenSigStartValue" SG_ 426 XBRSystemState2_SqC 14;
BA_ "GenSigCycleTime" SG_ 426 ExtraAxleSteeringFunctionStat 100;
BA_ "GenSigCycleTimeActive" SG_ 426 ExtraAxleSteeringFunctionStat 100;
BA_ "GenSigStartValue" SG_ 426 ExtraAxleSteeringFunctionStat 7;
BA_ "GenSigCycleTime" SG_ 426 RearAxle1DiffLock_stat_ISig_3 100;
BA_ "GenSigCycleTimeActive" SG_ 426 RearAxle1DiffLock_stat_ISig_3 100;
BA_ "GenSigStartValue" SG_ 426 RearAxle1DiffLock_stat_ISig_3 3;
BA_ "GenSigMaxLatency" SG_ 426 RearAxle1DiffLock_stat_ISig_3 20;
BA_ "GenSigCycleTime" SG_ 426 LevelControlInformation_ISig_3 100;
BA_ "GenSigCycleTimeActive" SG_ 426 LevelControlInformation_ISig_3 100;
BA_ "GenSigStartValue" SG_ 426 LevelControlInformation_ISig_3 15;
BA_ "GenSigMaxLatency" SG_ 426 LevelControlInformation_ISig_3 20;
BA_ "GenSigCycleTime" SG_ 426 VehicleMode_ISig_3 100;
BA_ "GenSigCycleTimeActive" SG_ 426 VehicleMode_ISig_3 100;
BA_ "GenSigStartValue" SG_ 426 VehicleMode_ISig_3 15;
BA_ "GenSigCycleTime" SG_ 426 ACC_SGO_Status_ISig_3 100;
BA_ "GenSigCycleTimeActive" SG_ 426 ACC_SGO_Status_ISig_3 100;
BA_ "GenSigStartValue" SG_ 426 ACC_SGO_Status_ISig_3 15;
BA_ "GenSigMaxLatency" SG_ 426 ACC_SGO_Status_ISig_3 100;
BA_ "GenSigCycleTime" SG_ 426 RearEndPositionStatus_ISig_3 100;
BA_ "GenSigCycleTimeActive" SG_ 426 RearEndPositionStatus_ISig_3 100;
BA_ "GenSigStartValue" SG_ 426 RearEndPositionStatus_ISig_3 7;
BA_ "GenSigMaxLatency" SG_ 426 RearEndPositionStatus_ISig_3 20;
BA_ "GenSigCycleTime" SG_ 426 PBAlertActiveStatus_ISig_3 100;
BA_ "GenSigCycleTimeActive" SG_ 426 PBAlertActiveStatus_ISig_3 100;
BA_ "GenSigStartValue" SG_ 426 PBAlertActiveStatus_ISig_3 7;
BA_ "GenSigMaxLatency" SG_ 426 PBAlertActiveStatus_ISig_3 20;
BA_ "GenSigCycleTime" SG_ 426 ECSShutdownCmd_ISig_3 100;
BA_ "GenSigCycleTimeActive" SG_ 426 ECSShutdownCmd_ISig_3 100;
BA_ "GenSigStartValue" SG_ 426 ECSShutdownCmd_ISig_3 3;
BA_ "GenSigMaxLatency" SG_ 426 ECSShutdownCmd_ISig_3 20;
BA_ "GenSigCycleTime" SG_ 426 VehicleDynamicSuspProhibitStat_I 100;
BA_ "GenSigCycleTimeActive" SG_ 426 VehicleDynamicSuspProhibitStat_I 100;
BA_ "GenSigStartValue" SG_ 426 VehicleDynamicSuspProhibitStat_I 3;
BA_ "GenSigMaxLatency" SG_ 426 VehicleDynamicSuspProhibitStat_I 20;
BA_ "SystemSignalLongSymbol" SG_ 426 VehicleDynamicSuspProhibitStat_I "VehicleDynamicSuspProhibitStat_ISig_3";
BA_ "GenSigCycleTime" SG_ 426 RideHeightFunctionStatus_ISig_3 100;
BA_ "GenSigCycleTimeActive" SG_ 426 RideHeightFunctionStatus_ISig_3 100;
BA_ "GenSigStartValue" SG_ 426 RideHeightFunctionStatus_ISig_3 15;
BA_ "GenSigMaxLatency" SG_ 426 RideHeightFunctionStatus_ISig_3 20;
BA_ "GenSigCycleTime" SG_ 268 BrakePedalPosition_ISig_3 100;
BA_ "GenSigCycleTimeActive" SG_ 268 BrakePedalPosition_ISig_3 100;
BA_ "GenSigStartValue" SG_ 268 BrakePedalPosition_ISig_3 255;
BA_ "GenSigMaxLatency" SG_ 268 BrakePedalPosition_ISig_3 10;
BA_ "GenSigCycleTime" SG_ 268 RoadWheelAngle_Request 100;
BA_ "GenSigCycleTimeActive" SG_ 268 RoadWheelAngle_Request 100;
BA_ "GenSigStartValue" SG_ 268 RoadWheelAngle_Request 65535;
BA_ "GenSigCycleTime" SG_ 268 AcceleratorPedalQuality_ISig_3 100;
BA_ "GenSigCycleTimeActive" SG_ 268 AcceleratorPedalQuality_ISig_3 100;
BA_ "GenSigStartValue" SG_ 268 AcceleratorPedalQuality_ISig_3 3;
BA_ "GenSigMaxLatency" SG_ 268 AcceleratorPedalQuality_ISig_3 10;
BA_ "GenSigCycleTime" SG_ 268 RoadWheelAngle_RateRequest 100;
BA_ "GenSigCycleTimeActive" SG_ 268 RoadWheelAngle_RateRequest 100;
BA_ "GenSigStartValue" SG_ 268 RoadWheelAngle_RateRequest 65535;
BA_ "GenSigCycleTime" SG_ 268 AcceleratorPedalStatus 100;
BA_ "GenSigCycleTimeActive" SG_ 268 AcceleratorPedalStatus 100;
BA_ "GenSigStartValue" SG_ 268 AcceleratorPedalStatus 7;
BA_ "GenSigMaxLatency" SG_ 268 AcceleratorPedalStatus 10;
BA_ "GenSigCycleTime" SG_ 268 SteeringControlMode_CRC 100;
BA_ "GenSigCycleTimeActive" SG_ 268 SteeringControlMode_CRC 100;
BA_ "GenSigStartValue" SG_ 268 SteeringControlMode_CRC 255;
BA_ "E2EDataId" SG_ 268 SteeringControlMode_CRC 203;
BA_ "E2EDataLength" SG_ 268 SteeringControlMode_CRC 16;
BA_ "E2EProfile" SG_ 268 SteeringControlMode_CRC "P01";
BA_ "GenSigCycleTime" SG_ 268 SteeringControlMode_Activate 100;
BA_ "GenSigCycleTimeActive" SG_ 268 SteeringControlMode_Activate 100;
BA_ "GenSigStartValue" SG_ 268 SteeringControlMode_Activate 3;
BA_ "GenSigCycleTime" SG_ 268 RoadWheelAngle_CRC 100;
BA_ "GenSigCycleTimeActive" SG_ 268 RoadWheelAngle_CRC 100;
BA_ "GenSigStartValue" SG_ 268 RoadWheelAngle_CRC 255;
BA_ "E2EDataId" SG_ 268 RoadWheelAngle_CRC 202;
BA_ "E2EDataLength" SG_ 268 RoadWheelAngle_CRC 48;
BA_ "E2EProfile" SG_ 268 RoadWheelAngle_CRC "P01";
BA_ "GenSigCycleTime" SG_ 268 AcceleratorPedalPosition1_ISig_3 100;
BA_ "GenSigCycleTimeActive" SG_ 268 AcceleratorPedalPosition1_ISig_3 100;
BA_ "GenSigStartValue" SG_ 268 AcceleratorPedalPosition1_ISig_3 255;
BA_ "GenSigMaxLatency" SG_ 268 AcceleratorPedalPosition1_ISig_3 10;
BA_ "GenSigCycleTime" SG_ 268 RoadWheelAngle_SqC 100;
BA_ "GenSigCycleTimeActive" SG_ 268 RoadWheelAngle_SqC 100;
BA_ "GenSigStartValue" SG_ 268 RoadWheelAngle_SqC 14;
BA_ "GenSigCycleTime" SG_ 268 AcceleratorPedalLowIdleSwitch_IS 100;
BA_ "GenSigCycleTimeActive" SG_ 268 AcceleratorPedalLowIdleSwitch_IS 100;
BA_ "GenSigStartValue" SG_ 268 AcceleratorPedalLowIdleSwitch_IS 3;
BA_ "GenSigMaxLatency" SG_ 268 AcceleratorPedalLowIdleSwitch_IS 10;
BA_ "SystemSignalLongSymbol" SG_ 268 AcceleratorPedalLowIdleSwitch_IS "AcceleratorPedalLowIdleSwitch_ISig_3";
BA_ "GenSigCycleTime" SG_ 268 SteeringControlMode_SqC 100;
BA_ "GenSigCycleTimeActive" SG_ 268 SteeringControlMode_SqC 100;
BA_ "GenSigStartValue" SG_ 268 SteeringControlMode_SqC 14;
BA_ "GenSigCycleTime" SG_ 268 SteeringControlMode_Request 100;
BA_ "GenSigCycleTimeActive" SG_ 268 SteeringControlMode_Request 100;
BA_ "GenSigStartValue" SG_ 268 SteeringControlMode_Request 3;
BA_REL_ "GenSigFirstTimeoutTime" BU_SG_REL_ EBS SG_ 266 ZxbrReqVeh_RetReq 3000;
BA_REL_ "GenSigTimeoutTime" BU_SG_REL_ EBS SG_ 266 ZxbrReqVeh_RetReq 100;
BA_REL_ "GenSigFirstTimeoutTime" BU_SG_REL_ EBS SG_ 266 ZxbrReqVeh_RetModReq 3000;
BA_REL_ "GenSigTimeoutTime" BU_SG_REL_ EBS SG_ 266 ZxbrReqVeh_RetModReq 100;
BA_REL_ "GenSigFirstTimeoutTime" BU_SG_REL_ EBS SG_ 266 ZxbrReqVeh_RetEbiModReq 3000;
BA_REL_ "GenSigTimeoutTime" BU_SG_REL_ EBS SG_ 266 ZxbrReqVeh_RetEbiModReq 100;
BA_REL_ "GenSigFirstTimeoutTime" BU_SG_REL_ EBS SG_ 266 ZxbrReqVeh_EbsCtrlModReq 3000;
BA_REL_ "GenSigTimeoutTime" BU_SG_REL_ EBS SG_ 266 ZxbrReqVeh_EbsCtrlModReq 100;
BA_REL_ "GenSigFirstTimeoutTime" BU_SG_REL_ EBS SG_ 266 ZxbrReqVeh_CRC 3000;
BA_REL_ "GenSigTimeoutTime" BU_SG_REL_ EBS SG_ 266 ZxbrReqVeh_CRC 100;
BA_REL_ "GenSigFirstTimeoutTime" BU_SG_REL_ EBS SG_ 266 ZxbrReqVeh_DrvrModReq 3000;
BA_REL_ "GenSigTimeoutTime" BU_SG_REL_ EBS SG_ 266 ZxbrReqVeh_DrvrModReq 100;
BA_REL_ "GenSigFirstTimeoutTime" BU_SG_REL_ EBS SG_ 266 ZxbrReqVeh_YawRateRefVds 3000;
BA_REL_ "GenSigTimeoutTime" BU_SG_REL_ EBS SG_ 266 ZxbrReqVeh_YawRateRefVds 100;
BA_REL_ "GenSigFirstTimeoutTime" BU_SG_REL_ EBS SG_ 266 ZxbrReqVeh_SqC 3000;
BA_REL_ "GenSigTimeoutTime" BU_SG_REL_ EBS SG_ 266 ZxbrReqVeh_SqC 100;
BA_REL_ "GenSigFirstTimeoutTime" BU_SG_REL_ EBS SG_ 262 IxbrReqAxle4_SlipCtrlEna 3000;
BA_REL_ "GenSigTimeoutTime" BU_SG_REL_ EBS SG_ 262 IxbrReqAxle4_SlipCtrlEna 100;
BA_REL_ "GenSigFirstTimeoutTime" BU_SG_REL_ EBS SG_ 262 IxbrReqAxle5_SqC 3000;
BA_REL_ "GenSigTimeoutTime" BU_SG_REL_ EBS SG_ 262 IxbrReqAxle5_SqC 100;
BA_REL_ "GenSigFirstTimeoutTime" BU_SG_REL_ EBS SG_ 262 IxbrReqAxle4_BrkTqReqLe 3000;
BA_REL_ "GenSigTimeoutTime" BU_SG_REL_ EBS SG_ 262 IxbrReqAxle4_BrkTqReqLe 100;
BA_REL_ "GenSigFirstTimeoutTime" BU_SG_REL_ EBS SG_ 262 IxbrReqAxle4_CRC 3000;
BA_REL_ "GenSigTimeoutTime" BU_SG_REL_ EBS SG_ 262 IxbrReqAxle4_CRC 100;
BA_REL_ "GenSigFirstTimeoutTime" BU_SG_REL_ EBS SG_ 262 IxbrReqAxle5_VehSpdLgtWhlRi 3000;
BA_REL_ "GenSigTimeoutTime" BU_SG_REL_ EBS SG_ 262 IxbrReqAxle5_VehSpdLgtWhlRi 100;
BA_REL_ "GenSigFirstTimeoutTime" BU_SG_REL_ EBS SG_ 262 IxbrReqAxle6_WhlSlipLimLoLe 3000;
BA_REL_ "GenSigTimeoutTime" BU_SG_REL_ EBS SG_ 262 IxbrReqAxle6_WhlSlipLimLoLe 100;
BA_REL_ "GenSigFirstTimeoutTime" BU_SG_REL_ EBS SG_ 262 IxbrReqAxle5_BrkTqReqRi 3000;
BA_REL_ "GenSigTimeoutTime" BU_SG_REL_ EBS SG_ 262 IxbrReqAxle5_BrkTqReqRi 100;
BA_REL_ "GenSigFirstTimeoutTime" BU_SG_REL_ EBS SG_ 262 IxbrReqAxle4_BrkTqReqRi 3000;
BA_REL_ "GenSigTimeoutTime" BU_SG_REL_ EBS SG_ 262 IxbrReqAxle4_BrkTqReqRi 100;
BA_REL_ "GenSigFirstTimeoutTime" BU_SG_REL_ EBS SG_ 262 IxbrReqAxle6_WhlSlipLimHiRi 3000;
BA_REL_ "GenSigTimeoutTime" BU_SG_REL_ EBS SG_ 262 IxbrReqAxle6_WhlSlipLimHiRi 100;
BA_REL_ "GenSigFirstTimeoutTime" BU_SG_REL_ EBS SG_ 262 IxbrReqAxle6_SqC 3000;
BA_REL_ "GenSigTimeoutTime" BU_SG_REL_ EBS SG_ 262 IxbrReqAxle6_SqC 100;
BA_REL_ "GenSigFirstTimeoutTime" BU_SG_REL_ EBS SG_ 262 IxbrReqAxle5_SlipCtrlEna 3000;
BA_REL_ "GenSigTimeoutTime" BU_SG_REL_ EBS SG_ 262 IxbrReqAxle5_SlipCtrlEna 100;
BA_REL_ "GenSigFirstTimeoutTime" BU_SG_REL_ EBS SG_ 262 IxbrReqAxle5_WhlSlipLimLoRi 3000;
BA_REL_ "GenSigTimeoutTime" BU_SG_REL_ EBS SG_ 262 IxbrReqAxle5_WhlSlipLimLoRi 100;
BA_REL_ "GenSigFirstTimeoutTime" BU_SG_REL_ EBS SG_ 262 IxbrReqAxle5_VehSpdLgtWhlLe 3000;
BA_REL_ "GenSigTimeoutTime" BU_SG_REL_ EBS SG_ 262 IxbrReqAxle5_VehSpdLgtWhlLe 100;
BA_REL_ "GenSigFirstTimeoutTime" BU_SG_REL_ EBS SG_ 262 IxbrReqAxle6_WhlSlipLimLoRi 3000;
BA_REL_ "GenSigTimeoutTime" BU_SG_REL_ EBS SG_ 262 IxbrReqAxle6_WhlSlipLimLoRi 100;
BA_REL_ "GenSigFirstTimeoutTime" BU_SG_REL_ EBS SG_ 262 IxbrReqAxle6_VehSpdLgtWhlRi 3000;
BA_REL_ "GenSigTimeoutTime" BU_SG_REL_ EBS SG_ 262 IxbrReqAxle6_VehSpdLgtWhlRi 100;
BA_REL_ "GenSigFirstTimeoutTime" BU_SG_REL_ EBS SG_ 262 IxbrReqAxle5_VehSpdLgtWhlQltyLe 3000;
BA_REL_ "GenSigTimeoutTime" BU_SG_REL_ EBS SG_ 262 IxbrReqAxle5_VehSpdLgtWhlQltyLe 100;
BA_REL_ "GenSigFirstTimeoutTime" BU_SG_REL_ EBS SG_ 262 IxbrReqAxle6_CRC 3000;
BA_REL_ "GenSigTimeoutTime" BU_SG_REL_ EBS SG_ 262 IxbrReqAxle6_CRC 100;
BA_REL_ "GenSigFirstTimeoutTime" BU_SG_REL_ EBS SG_ 262 IxbrReqAxle5_CRC 3000;
BA_REL_ "GenSigTimeoutTime" BU_SG_REL_ EBS SG_ 262 IxbrReqAxle5_CRC 100;
BA_REL_ "GenSigFirstTimeoutTime" BU_SG_REL_ EBS SG_ 262 IxbrReqAxle4_SqC 3000;
BA_REL_ "GenSigTimeoutTime" BU_SG_REL_ EBS SG_ 262 IxbrReqAxle4_SqC 100;
BA_REL_ "GenSigFirstTimeoutTime" BU_SG_REL_ EBS SG_ 262 IxbrReqAxle4_VehSpdLgtWhlRi 3000;
BA_REL_ "GenSigTimeoutTime" BU_SG_REL_ EBS SG_ 262 IxbrReqAxle4_VehSpdLgtWhlRi 100;
BA_REL_ "GenSigFirstTimeoutTime" BU_SG_REL_ EBS SG_ 262 IxbrReqAxle4_WhlSlipLimHiLe 3000;
BA_REL_ "GenSigTimeoutTime" BU_SG_REL_ EBS SG_ 262 IxbrReqAxle4_WhlSlipLimHiLe 100;
BA_REL_ "GenSigFirstTimeoutTime" BU_SG_REL_ EBS SG_ 262 IxbrReqAxle4_VehSpdLgtWhlLe 3000;
BA_REL_ "GenSigTimeoutTime" BU_SG_REL_ EBS SG_ 262 IxbrReqAxle4_VehSpdLgtWhlLe 100;
BA_REL_ "GenSigFirstTimeoutTime" BU_SG_REL_ EBS SG_ 262 IxbrReqAxle4_WhlSlipLimLoLe 3000;
BA_REL_ "GenSigTimeoutTime" BU_SG_REL_ EBS SG_ 262 IxbrReqAxle4_WhlSlipLimLoLe 100;
BA_REL_ "GenSigFirstTimeoutTime" BU_SG_REL_ EBS SG_ 262 IxbrReqAxle6_VehSpdLgtWhlQltyRi 3000;
BA_REL_ "GenSigTimeoutTime" BU_SG_REL_ EBS SG_ 262 IxbrReqAxle6_VehSpdLgtWhlQltyRi 100;
BA_REL_ "GenSigFirstTimeoutTime" BU_SG_REL_ EBS SG_ 262 IxbrReqAxle6_BrkTqReqLe 3000;
BA_REL_ "GenSigTimeoutTime" BU_SG_REL_ EBS SG_ 262 IxbrReqAxle6_BrkTqReqLe 100;
BA_REL_ "GenSigFirstTimeoutTime" BU_SG_REL_ EBS SG_ 262 IxbrReqAxle4_WhlSlipLimLoRi 3000;
BA_REL_ "GenSigTimeoutTime" BU_SG_REL_ EBS SG_ 262 IxbrReqAxle4_WhlSlipLimLoRi 100;
BA_REL_ "GenSigFirstTimeoutTime" BU_SG_REL_ EBS SG_ 262 IxbrReqAxle4_VehSpdLgtWhlQltyRi 3000;
BA_REL_ "GenSigTimeoutTime" BU_SG_REL_ EBS SG_ 262 IxbrReqAxle4_VehSpdLgtWhlQltyRi 100;
BA_REL_ "GenSigFirstTimeoutTime" BU_SG_REL_ EBS SG_ 262 IxbrReqAxle4_IxbrModReq 3000;
BA_REL_ "GenSigTimeoutTime" BU_SG_REL_ EBS SG_ 262 IxbrReqAxle4_IxbrModReq 100;
BA_REL_ "GenSigFirstTimeoutTime" BU_SG_REL_ EBS SG_ 262 IxbrReqAxle6_BrkTqReqRi 3000;
BA_REL_ "GenSigTimeoutTime" BU_SG_REL_ EBS SG_ 262 IxbrReqAxle6_BrkTqReqRi 100;
BA_REL_ "GenSigFirstTimeoutTime" BU_SG_REL_ EBS SG_ 262 IxbrReqAxle6_SlipCtrlEna 3000;
BA_REL_ "GenSigTimeoutTime" BU_SG_REL_ EBS SG_ 262 IxbrReqAxle6_SlipCtrlEna 100;
BA_REL_ "GenSigFirstTimeoutTime" BU_SG_REL_ EBS SG_ 262 IxbrReqAxle4_VehSpdLgtWhlQltyLe 3000;
BA_REL_ "GenSigTimeoutTime" BU_SG_REL_ EBS SG_ 262 IxbrReqAxle4_VehSpdLgtWhlQltyLe 100;
BA_REL_ "GenSigFirstTimeoutTime" BU_SG_REL_ EBS SG_ 262 IxbrReqAxle6_VehSpdLgtWhlQltyLe 3000;
BA_REL_ "GenSigTimeoutTime" BU_SG_REL_ EBS SG_ 262 IxbrReqAxle6_VehSpdLgtWhlQltyLe 100;
BA_REL_ "GenSigFirstTimeoutTime" BU_SG_REL_ EBS SG_ 262 IxbrReqAxle5_BrkTqReqLe 3000;
BA_REL_ "GenSigTimeoutTime" BU_SG_REL_ EBS SG_ 262 IxbrReqAxle5_BrkTqReqLe 100;
BA_REL_ "GenSigFirstTimeoutTime" BU_SG_REL_ EBS SG_ 262 IxbrReqAxle5_VehSpdLgtWhlQltyRi 3000;
BA_REL_ "GenSigTimeoutTime" BU_SG_REL_ EBS SG_ 262 IxbrReqAxle5_VehSpdLgtWhlQltyRi 100;
BA_REL_ "GenSigFirstTimeoutTime" BU_SG_REL_ EBS SG_ 262 IxbrReqAxle5_WhlSlipLimHiRi 3000;
BA_REL_ "GenSigTimeoutTime" BU_SG_REL_ EBS SG_ 262 IxbrReqAxle5_WhlSlipLimHiRi 100;
BA_REL_ "GenSigFirstTimeoutTime" BU_SG_REL_ EBS SG_ 262 IxbrReqAxle5_WhlSlipLimLoLe 3000;
BA_REL_ "GenSigTimeoutTime" BU_SG_REL_ EBS SG_ 262 IxbrReqAxle5_WhlSlipLimLoLe 100;
BA_REL_ "GenSigFirstTimeoutTime" BU_SG_REL_ EBS SG_ 262 IxbrReqAxle5_IxbrModReq 3000;
BA_REL_ "GenSigTimeoutTime" BU_SG_REL_ EBS SG_ 262 IxbrReqAxle5_IxbrModReq 100;
BA_REL_ "GenSigFirstTimeoutTime" BU_SG_REL_ EBS SG_ 262 IxbrReqAxle4_WhlSlipLimHiRi 3000;
BA_REL_ "GenSigTimeoutTime" BU_SG_REL_ EBS SG_ 262 IxbrReqAxle4_WhlSlipLimHiRi 100;
BA_REL_ "GenSigFirstTimeoutTime" BU_SG_REL_ EBS SG_ 262 IxbrReqAxle6_IxbrModReq 3000;
BA_REL_ "GenSigTimeoutTime" BU_SG_REL_ EBS SG_ 262 IxbrReqAxle6_IxbrModReq 100;
BA_REL_ "GenSigFirstTimeoutTime" BU_SG_REL_ EBS SG_ 262 IxbrReqAxle5_WhlSlipLimHiLe 3000;
BA_REL_ "GenSigTimeoutTime" BU_SG_REL_ EBS SG_ 262 IxbrReqAxle5_WhlSlipLimHiLe 100;
BA_REL_ "GenSigFirstTimeoutTime" BU_SG_REL_ EBS SG_ 262 IxbrReqAxle6_WhlSlipLimHiLe 3000;
BA_REL_ "GenSigTimeoutTime" BU_SG_REL_ EBS SG_ 262 IxbrReqAxle6_WhlSlipLimHiLe 100;
BA_REL_ "GenSigFirstTimeoutTime" BU_SG_REL_ EBS SG_ 262 IxbrReqAxle6_VehSpdLgtWhlLe 3000;
BA_REL_ "GenSigTimeoutTime" BU_SG_REL_ EBS SG_ 262 IxbrReqAxle6_VehSpdLgtWhlLe 100;
BA_REL_ "GenSigFirstTimeoutTime" BU_SG_REL_ EBS SG_ 261 IxbrReqAxle3_BrkTqReqLe 3000;
BA_REL_ "GenSigTimeoutTime" BU_SG_REL_ EBS SG_ 261 IxbrReqAxle3_BrkTqReqLe 100;
BA_REL_ "GenSigFirstTimeoutTime" BU_SG_REL_ EBS SG_ 261 IxbrReqAxle3_WhlSlipLimHiLe 3000;
BA_REL_ "GenSigTimeoutTime" BU_SG_REL_ EBS SG_ 261 IxbrReqAxle3_WhlSlipLimHiLe 100;
BA_REL_ "GenSigFirstTimeoutTime" BU_SG_REL_ EBS SG_ 261 IxbrReqAxle1_BrkTqReqLe 3000;
BA_REL_ "GenSigTimeoutTime" BU_SG_REL_ EBS SG_ 261 IxbrReqAxle1_BrkTqReqLe 100;
BA_REL_ "GenSigFirstTimeoutTime" BU_SG_REL_ EBS SG_ 261 IxbrReqAxle2_WhlSlipLimHiRi 3000;
BA_REL_ "GenSigTimeoutTime" BU_SG_REL_ EBS SG_ 261 IxbrReqAxle2_WhlSlipLimHiRi 100;
BA_REL_ "GenSigFirstTimeoutTime" BU_SG_REL_ EBS SG_ 261 IxbrReqAxle3_WhlSlipLimLoRi 3000;
BA_REL_ "GenSigTimeoutTime" BU_SG_REL_ EBS SG_ 261 IxbrReqAxle3_WhlSlipLimLoRi 100;
BA_REL_ "GenSigFirstTimeoutTime" BU_SG_REL_ EBS SG_ 261 IxbrReqAxle1_WhlSlipLimLoLe 3000;
BA_REL_ "GenSigTimeoutTime" BU_SG_REL_ EBS SG_ 261 IxbrReqAxle1_WhlSlipLimLoLe 100;
BA_REL_ "GenSigFirstTimeoutTime" BU_SG_REL_ EBS SG_ 261 IxbrReqAxle3_BrkTqReqRi 3000;
BA_REL_ "GenSigTimeoutTime" BU_SG_REL_ EBS SG_ 261 IxbrReqAxle3_BrkTqReqRi 100;
BA_REL_ "GenSigFirstTimeoutTime" BU_SG_REL_ EBS SG_ 261 IxbrReqAxle2_BrkTqReqLe 3000;
BA_REL_ "GenSigTimeoutTime" BU_SG_REL_ EBS SG_ 261 IxbrReqAxle2_BrkTqReqLe 100;
BA_REL_ "GenSigFirstTimeoutTime" BU_SG_REL_ EBS SG_ 261 IxbrReqAxle1_VehSpdLgtWhlQltyRi 3000;
BA_REL_ "GenSigTimeoutTime" BU_SG_REL_ EBS SG_ 261 IxbrReqAxle1_VehSpdLgtWhlQltyRi 100;
BA_REL_ "GenSigFirstTimeoutTime" BU_SG_REL_ EBS SG_ 261 IxbrReqAxle2_BrkTqReqRi 3000;
BA_REL_ "GenSigTimeoutTime" BU_SG_REL_ EBS SG_ 261 IxbrReqAxle2_BrkTqReqRi 100;
BA_REL_ "GenSigFirstTimeoutTime" BU_SG_REL_ EBS SG_ 261 IxbrReqAxle1_WhlSlipLimHiLe 3000;
BA_REL_ "GenSigTimeoutTime" BU_SG_REL_ EBS SG_ 261 IxbrReqAxle1_WhlSlipLimHiLe 100;
BA_REL_ "GenSigFirstTimeoutTime" BU_SG_REL_ EBS SG_ 261 IxbrReqAxle1_SlipCtrlEna 3000;
BA_REL_ "GenSigTimeoutTime" BU_SG_REL_ EBS SG_ 261 IxbrReqAxle1_SlipCtrlEna 100;
BA_REL_ "GenSigFirstTimeoutTime" BU_SG_REL_ EBS SG_ 261 IxbrReqAxle1_WhlSlipLimLoRi 3000;
BA_REL_ "GenSigTimeoutTime" BU_SG_REL_ EBS SG_ 261 IxbrReqAxle1_WhlSlipLimLoRi 100;
BA_REL_ "GenSigFirstTimeoutTime" BU_SG_REL_ EBS SG_ 261 IxbrReqAxle2_SlipCtrlEna 3000;
BA_REL_ "GenSigTimeoutTime" BU_SG_REL_ EBS SG_ 261 IxbrReqAxle2_SlipCtrlEna 100;
BA_REL_ "GenSigFirstTimeoutTime" BU_SG_REL_ EBS SG_ 261 IxbrReqAxle1_IxbrModReq 3000;
BA_REL_ "GenSigTimeoutTime" BU_SG_REL_ EBS SG_ 261 IxbrReqAxle1_IxbrModReq 100;
BA_REL_ "GenSigFirstTimeoutTime" BU_SG_REL_ EBS SG_ 261 IxbrReqAxle1_SqC 3000;
BA_REL_ "GenSigTimeoutTime" BU_SG_REL_ EBS SG_ 261 IxbrReqAxle1_SqC 100;
BA_REL_ "GenSigFirstTimeoutTime" BU_SG_REL_ EBS SG_ 261 IxbrReqAxle3_VehSpdLgtWhlQltyLe 3000;
BA_REL_ "GenSigTimeoutTime" BU_SG_REL_ EBS SG_ 261 IxbrReqAxle3_VehSpdLgtWhlQltyLe 100;
BA_REL_ "GenSigFirstTimeoutTime" BU_SG_REL_ EBS SG_ 261 IxbrReqAxle3_SqC 3000;
BA_REL_ "GenSigTimeoutTime" BU_SG_REL_ EBS SG_ 261 IxbrReqAxle3_SqC 100;
BA_REL_ "GenSigFirstTimeoutTime" BU_SG_REL_ EBS SG_ 261 IxbrReqAxle2_WhlSlipLimLoRi 3000;
BA_REL_ "GenSigTimeoutTime" BU_SG_REL_ EBS SG_ 261 IxbrReqAxle2_WhlSlipLimLoRi 100;
BA_REL_ "GenSigFirstTimeoutTime" BU_SG_REL_ EBS SG_ 261 IxbrReqAxle1_WhlSlipLimHiRi 3000;
BA_REL_ "GenSigTimeoutTime" BU_SG_REL_ EBS SG_ 261 IxbrReqAxle1_WhlSlipLimHiRi 100;
BA_REL_ "GenSigFirstTimeoutTime" BU_SG_REL_ EBS SG_ 261 IxbrReqAxle2_IxbrModReq 3000;
BA_REL_ "GenSigTimeoutTime" BU_SG_REL_ EBS SG_ 261 IxbrReqAxle2_IxbrModReq 100;
BA_REL_ "GenSigFirstTimeoutTime" BU_SG_REL_ EBS SG_ 261 IxbrReqAxle3_WhlSlipLimLoLe 3000;
BA_REL_ "GenSigTimeoutTime" BU_SG_REL_ EBS SG_ 261 IxbrReqAxle3_WhlSlipLimLoLe 100;
BA_REL_ "GenSigFirstTimeoutTime" BU_SG_REL_ EBS SG_ 261 IxbrReqAxle2_SqC 3000;
BA_REL_ "GenSigTimeoutTime" BU_SG_REL_ EBS SG_ 261 IxbrReqAxle2_SqC 100;
BA_REL_ "GenSigFirstTimeoutTime" BU_SG_REL_ EBS SG_ 261 IxbrReqAxle1_VehSpdLgtWhlLe 3000;
BA_REL_ "GenSigTimeoutTime" BU_SG_REL_ EBS SG_ 261 IxbrReqAxle1_VehSpdLgtWhlLe 100;
BA_REL_ "GenSigFirstTimeoutTime" BU_SG_REL_ EBS SG_ 261 IxbrReqAxle3_VehSpdLgtWhlRi 3000;
BA_REL_ "GenSigTimeoutTime" BU_SG_REL_ EBS SG_ 261 IxbrReqAxle3_VehSpdLgtWhlRi 100;
BA_REL_ "GenSigFirstTimeoutTime" BU_SG_REL_ EBS SG_ 261 IxbrReqAxle3_WhlSlipLimHiRi 3000;
BA_REL_ "GenSigTimeoutTime" BU_SG_REL_ EBS SG_ 261 IxbrReqAxle3_WhlSlipLimHiRi 100;
BA_REL_ "GenSigFirstTimeoutTime" BU_SG_REL_ EBS SG_ 261 IxbrReqAxle2_WhlSlipLimLoLe 3000;
BA_REL_ "GenSigTimeoutTime" BU_SG_REL_ EBS SG_ 261 IxbrReqAxle2_WhlSlipLimLoLe 100;
BA_REL_ "GenSigFirstTimeoutTime" BU_SG_REL_ EBS SG_ 261 IxbrReqAxle2_VehSpdLgtWhlLe 3000;
BA_REL_ "GenSigTimeoutTime" BU_SG_REL_ EBS SG_ 261 IxbrReqAxle2_VehSpdLgtWhlLe 100;
BA_REL_ "GenSigFirstTimeoutTime" BU_SG_REL_ EBS SG_ 261 IxbrReqAxle2_WhlSlipLimHiLe 3000;
BA_REL_ "GenSigTimeoutTime" BU_SG_REL_ EBS SG_ 261 IxbrReqAxle2_WhlSlipLimHiLe 100;
BA_REL_ "GenSigFirstTimeoutTime" BU_SG_REL_ EBS SG_ 261 IxbrReqAxle3_VehSpdLgtWhlQltyRi 3000;
BA_REL_ "GenSigTimeoutTime" BU_SG_REL_ EBS SG_ 261 IxbrReqAxle3_VehSpdLgtWhlQltyRi 100;
BA_REL_ "GenSigFirstTimeoutTime" BU_SG_REL_ EBS SG_ 261 IxbrReqAxle1_VehSpdLgtWhlQltyLe 3000;
BA_REL_ "GenSigTimeoutTime" BU_SG_REL_ EBS SG_ 261 IxbrReqAxle1_VehSpdLgtWhlQltyLe 100;
BA_REL_ "GenSigFirstTimeoutTime" BU_SG_REL_ EBS SG_ 261 IxbrReqAxle1_BrkTqReqRi 3000;
BA_REL_ "GenSigTimeoutTime" BU_SG_REL_ EBS SG_ 261 IxbrReqAxle1_BrkTqReqRi 100;
BA_REL_ "GenSigFirstTimeoutTime" BU_SG_REL_ EBS SG_ 261 IxbrReqAxle1_VehSpdLgtWhlRi 3000;
BA_REL_ "GenSigTimeoutTime" BU_SG_REL_ EBS SG_ 261 IxbrReqAxle1_VehSpdLgtWhlRi 100;
BA_REL_ "GenSigFirstTimeoutTime" BU_SG_REL_ EBS SG_ 261 IxbrReqAxle3_IxbrModReq 3000;
BA_REL_ "GenSigTimeoutTime" BU_SG_REL_ EBS SG_ 261 IxbrReqAxle3_IxbrModReq 100;
BA_REL_ "GenSigFirstTimeoutTime" BU_SG_REL_ EBS SG_ 261 IxbrReqAxle2_CRC 3000;
BA_REL_ "GenSigTimeoutTime" BU_SG_REL_ EBS SG_ 261 IxbrReqAxle2_CRC 100;
BA_REL_ "GenSigFirstTimeoutTime" BU_SG_REL_ EBS SG_ 261 IxbrReqAxle2_VehSpdLgtWhlQltyLe 3000;
BA_REL_ "GenSigTimeoutTime" BU_SG_REL_ EBS SG_ 261 IxbrReqAxle2_VehSpdLgtWhlQltyLe 100;
BA_REL_ "GenSigFirstTimeoutTime" BU_SG_REL_ EBS SG_ 261 IxbrReqAxle3_VehSpdLgtWhlLe 3000;
BA_REL_ "GenSigTimeoutTime" BU_SG_REL_ EBS SG_ 261 IxbrReqAxle3_VehSpdLgtWhlLe 100;
BA_REL_ "GenSigFirstTimeoutTime" BU_SG_REL_ EBS SG_ 261 IxbrReqAxle3_SlipCtrlEna 3000;
BA_REL_ "GenSigTimeoutTime" BU_SG_REL_ EBS SG_ 261 IxbrReqAxle3_SlipCtrlEna 100;
BA_REL_ "GenSigFirstTimeoutTime" BU_SG_REL_ EBS SG_ 261 IxbrReqAxle3_CRC 3000;
BA_REL_ "GenSigTimeoutTime" BU_SG_REL_ EBS SG_ 261 IxbrReqAxle3_CRC 100;
BA_REL_ "GenSigFirstTimeoutTime" BU_SG_REL_ EBS SG_ 261 IxbrReqAxle2_VehSpdLgtWhlRi 3000;
BA_REL_ "GenSigTimeoutTime" BU_SG_REL_ EBS SG_ 261 IxbrReqAxle2_VehSpdLgtWhlRi 100;
BA_REL_ "GenSigFirstTimeoutTime" BU_SG_REL_ EBS SG_ 261 IxbrReqAxle2_VehSpdLgtWhlQltyRi 3000;
BA_REL_ "GenSigTimeoutTime" BU_SG_REL_ EBS SG_ 261 IxbrReqAxle2_VehSpdLgtWhlQltyRi 100;
BA_REL_ "GenSigFirstTimeoutTime" BU_SG_REL_ EBS SG_ 261 IxbrReqAxle1_CRC 3000;
BA_REL_ "GenSigTimeoutTime" BU_SG_REL_ EBS SG_ 261 IxbrReqAxle1_CRC 100;
BA_REL_ "GenSigFirstTimeoutTime" BU_SG_REL_ EBS SG_ 554 EstAxle3_LoadNormLe 3000;
BA_REL_ "GenSigTimeoutTime" BU_SG_REL_ EBS SG_ 554 EstAxle3_LoadNormLe 300;
BA_REL_ "GenSigFirstTimeoutTime" BU_SG_REL_ EBS SG_ 554 EstAxle6_WhlRdEstQltyRi 3000;
BA_REL_ "GenSigTimeoutTime" BU_SG_REL_ EBS SG_ 554 EstAxle6_WhlRdEstQltyRi 300;
BA_REL_ "GenSigFirstTimeoutTime" BU_SG_REL_ EBS SG_ 554 EstAxle5_WhlRdEstQltyRi 3000;
BA_REL_ "GenSigTimeoutTime" BU_SG_REL_ EBS SG_ 554 EstAxle5_WhlRdEstQltyRi 300;
BA_REL_ "GenSigFirstTimeoutTime" BU_SG_REL_ EBS SG_ 554 EstAxle2_LoadNormQltyLe 3000;
BA_REL_ "GenSigTimeoutTime" BU_SG_REL_ EBS SG_ 554 EstAxle2_LoadNormQltyLe 300;
BA_REL_ "GenSigFirstTimeoutTime" BU_SG_REL_ EBS SG_ 554 EstAxle3_LoadNormQltyRi 3000;
BA_REL_ "GenSigTimeoutTime" BU_SG_REL_ EBS SG_ 554 EstAxle3_LoadNormQltyRi 300;
BA_REL_ "GenSigFirstTimeoutTime" BU_SG_REL_ EBS SG_ 554 EstAxle6_SqC 3000;
BA_REL_ "GenSigTimeoutTime" BU_SG_REL_ EBS SG_ 554 EstAxle6_SqC 300;
BA_REL_ "GenSigFirstTimeoutTime" BU_SG_REL_ EBS SG_ 554 EstAxle4_LoadNormQltyRi 3000;
BA_REL_ "GenSigTimeoutTime" BU_SG_REL_ EBS SG_ 554 EstAxle4_LoadNormQltyRi 300;
BA_REL_ "GenSigFirstTimeoutTime" BU_SG_REL_ EBS SG_ 554 EstAxle6_LoadNormRi 3000;
BA_REL_ "GenSigTimeoutTime" BU_SG_REL_ EBS SG_ 554 EstAxle6_LoadNormRi 300;
BA_REL_ "GenSigFirstTimeoutTime" BU_SG_REL_ EBS SG_ 554 EstAxle5_SqC 3000;
BA_REL_ "GenSigTimeoutTime" BU_SG_REL_ EBS SG_ 554 EstAxle5_SqC 300;
BA_REL_ "GenSigFirstTimeoutTime" BU_SG_REL_ EBS SG_ 554 EstAxle6_CRC 3000;
BA_REL_ "GenSigTimeoutTime" BU_SG_REL_ EBS SG_ 554 EstAxle6_CRC 300;
BA_REL_ "GenSigFirstTimeoutTime" BU_SG_REL_ EBS SG_ 554 EstAxle2_WhlRdEstLe 3000;
BA_REL_ "GenSigTimeoutTime" BU_SG_REL_ EBS SG_ 554 EstAxle2_WhlRdEstLe 300;
BA_REL_ "GenSigFirstTimeoutTime" BU_SG_REL_ EBS SG_ 554 EstAxle3_WhlRdEstRi 3000;
BA_REL_ "GenSigTimeoutTime" BU_SG_REL_ EBS SG_ 554 EstAxle3_WhlRdEstRi 300;
BA_REL_ "GenSigFirstTimeoutTime" BU_SG_REL_ EBS SG_ 554 EstAxle5_LoadNormQltyRi 3000;
BA_REL_ "GenSigTimeoutTime" BU_SG_REL_ EBS SG_ 554 EstAxle5_LoadNormQltyRi 300;
BA_REL_ "GenSigFirstTimeoutTime" BU_SG_REL_ EBS SG_ 554 EstAxle6_WhlRdEstLe 3000;
BA_REL_ "GenSigTimeoutTime" BU_SG_REL_ EBS SG_ 554 EstAxle6_WhlRdEstLe 300;
BA_REL_ "GenSigFirstTimeoutTime" BU_SG_REL_ EBS SG_ 554 EstAxle6_WhlRdEstQltyLe 3000;
BA_REL_ "GenSigTimeoutTime" BU_SG_REL_ EBS SG_ 554 EstAxle6_WhlRdEstQltyLe 300;
BA_REL_ "GenSigFirstTimeoutTime" BU_SG_REL_ EBS SG_ 554 EstAxle6_LoadNormLe 3000;
BA_REL_ "GenSigTimeoutTime" BU_SG_REL_ EBS SG_ 554 EstAxle6_LoadNormLe 300;
BA_REL_ "GenSigFirstTimeoutTime" BU_SG_REL_ EBS SG_ 554 EstAxle5_LoadNormRi 3000;
BA_REL_ "GenSigTimeoutTime" BU_SG_REL_ EBS SG_ 554 EstAxle5_LoadNormRi 300;
BA_REL_ "GenSigFirstTimeoutTime" BU_SG_REL_ EBS SG_ 554 EstAxle5_LoadNormQltyLe 3000;
BA_REL_ "GenSigTimeoutTime" BU_SG_REL_ EBS SG_ 554 EstAxle5_LoadNormQltyLe 300;
BA_REL_ "GenSigFirstTimeoutTime" BU_SG_REL_ EBS SG_ 554 EstAxle5_CRC 3000;
BA_REL_ "GenSigTimeoutTime" BU_SG_REL_ EBS SG_ 554 EstAxle5_CRC 300;
BA_REL_ "GenSigFirstTimeoutTime" BU_SG_REL_ EBS SG_ 554 EstAxle1_WhlRdEstRi 3000;
BA_REL_ "GenSigTimeoutTime" BU_SG_REL_ EBS SG_ 554 EstAxle1_WhlRdEstRi 300;
BA_REL_ "GenSigFirstTimeoutTime" BU_SG_REL_ EBS SG_ 554 EstAxle4_LoadNormRi 3000;
BA_REL_ "GenSigTimeoutTime" BU_SG_REL_ EBS SG_ 554 EstAxle4_LoadNormRi 300;
BA_REL_ "GenSigFirstTimeoutTime" BU_SG_REL_ EBS SG_ 554 EstAxle3_WhlRdEstQltyLe 3000;
BA_REL_ "GenSigTimeoutTime" BU_SG_REL_ EBS SG_ 554 EstAxle3_WhlRdEstQltyLe 300;
BA_REL_ "GenSigFirstTimeoutTime" BU_SG_REL_ EBS SG_ 554 EstAxle4_WhlRdEstRi 3000;
BA_REL_ "GenSigTimeoutTime" BU_SG_REL_ EBS SG_ 554 EstAxle4_WhlRdEstRi 300;
BA_REL_ "GenSigFirstTimeoutTime" BU_SG_REL_ EBS SG_ 554 EstAxle6_WhlRdEstRi 3000;
BA_REL_ "GenSigTimeoutTime" BU_SG_REL_ EBS SG_ 554 EstAxle6_WhlRdEstRi 300;
BA_REL_ "GenSigFirstTimeoutTime" BU_SG_REL_ EBS SG_ 554 EstAxle5_LoadNormLe 3000;
BA_REL_ "GenSigTimeoutTime" BU_SG_REL_ EBS SG_ 554 EstAxle5_LoadNormLe 300;
BA_REL_ "GenSigFirstTimeoutTime" BU_SG_REL_ EBS SG_ 554 EstAxle5_WhlRdEstLe 3000;
BA_REL_ "GenSigTimeoutTime" BU_SG_REL_ EBS SG_ 554 EstAxle5_WhlRdEstLe 300;
BA_REL_ "GenSigFirstTimeoutTime" BU_SG_REL_ EBS SG_ 554 EstAxle3_CRC 3000;
BA_REL_ "GenSigTimeoutTime" BU_SG_REL_ EBS SG_ 554 EstAxle3_CRC 300;
BA_REL_ "GenSigFirstTimeoutTime" BU_SG_REL_ EBS SG_ 554 EstAxle2_LoadNormRi 3000;
BA_REL_ "GenSigTimeoutTime" BU_SG_REL_ EBS SG_ 554 EstAxle2_LoadNormRi 300;
BA_REL_ "GenSigFirstTimeoutTime" BU_SG_REL_ EBS SG_ 554 EstAxle4_SqC 3000;
BA_REL_ "GenSigTimeoutTime" BU_SG_REL_ EBS SG_ 554 EstAxle4_SqC 300;
BA_REL_ "GenSigFirstTimeoutTime" BU_SG_REL_ EBS SG_ 554 EstAxle4_WhlRdEstQltyRi 3000;
BA_REL_ "GenSigTimeoutTime" BU_SG_REL_ EBS SG_ 554 EstAxle4_WhlRdEstQltyRi 300;
BA_REL_ "GenSigFirstTimeoutTime" BU_SG_REL_ EBS SG_ 554 EstAxle6_LoadNormQltyRi 3000;
BA_REL_ "GenSigTimeoutTime" BU_SG_REL_ EBS SG_ 554 EstAxle6_LoadNormQltyRi 300;
BA_REL_ "GenSigFirstTimeoutTime" BU_SG_REL_ EBS SG_ 554 EstAxle1_LoadNormQltyRi 3000;
BA_REL_ "GenSigTimeoutTime" BU_SG_REL_ EBS SG_ 554 EstAxle1_LoadNormQltyRi 300;
BA_REL_ "GenSigFirstTimeoutTime" BU_SG_REL_ EBS SG_ 554 EstAxle1_LoadNormQltyLe 3000;
BA_REL_ "GenSigTimeoutTime" BU_SG_REL_ EBS SG_ 554 EstAxle1_LoadNormQltyLe 300;
BA_REL_ "GenSigFirstTimeoutTime" BU_SG_REL_ EBS SG_ 554 EstAxle2_LoadNormLe 3000;
BA_REL_ "GenSigTimeoutTime" BU_SG_REL_ EBS SG_ 554 EstAxle2_LoadNormLe 300;
BA_REL_ "GenSigFirstTimeoutTime" BU_SG_REL_ EBS SG_ 554 EstAxle4_WhlRdEstQltyLe 3000;
BA_REL_ "GenSigTimeoutTime" BU_SG_REL_ EBS SG_ 554 EstAxle4_WhlRdEstQltyLe 300;
BA_REL_ "GenSigFirstTimeoutTime" BU_SG_REL_ EBS SG_ 554 EstAxle4_WhlRdEstLe 3000;
BA_REL_ "GenSigTimeoutTime" BU_SG_REL_ EBS SG_ 554 EstAxle4_WhlRdEstLe 300;
BA_REL_ "GenSigFirstTimeoutTime" BU_SG_REL_ EBS SG_ 554 EstAxle1_WhlRdEstQltyLe 3000;
BA_REL_ "GenSigTimeoutTime" BU_SG_REL_ EBS SG_ 554 EstAxle1_WhlRdEstQltyLe 300;
BA_REL_ "GenSigFirstTimeoutTime" BU_SG_REL_ EBS SG_ 554 EstAxle2_LoadNormQltyRi 3000;
BA_REL_ "GenSigTimeoutTime" BU_SG_REL_ EBS SG_ 554 EstAxle2_LoadNormQltyRi 300;
BA_REL_ "GenSigFirstTimeoutTime" BU_SG_REL_ EBS SG_ 554 EstAxle3_LoadNormQltyLe 3000;
BA_REL_ "GenSigTimeoutTime" BU_SG_REL_ EBS SG_ 554 EstAxle3_LoadNormQltyLe 300;
BA_REL_ "GenSigFirstTimeoutTime" BU_SG_REL_ EBS SG_ 554 EstAxle4_LoadNormQltyLe 3000;
BA_REL_ "GenSigTimeoutTime" BU_SG_REL_ EBS SG_ 554 EstAxle4_LoadNormQltyLe 300;
BA_REL_ "GenSigFirstTimeoutTime" BU_SG_REL_ EBS SG_ 554 EstAxle2_WhlRdEstQltyRi 3000;
BA_REL_ "GenSigTimeoutTime" BU_SG_REL_ EBS SG_ 554 EstAxle2_WhlRdEstQltyRi 300;
BA_REL_ "GenSigFirstTimeoutTime" BU_SG_REL_ EBS SG_ 554 EstAxle6_LoadNormQltyLe 3000;
BA_REL_ "GenSigTimeoutTime" BU_SG_REL_ EBS SG_ 554 EstAxle6_LoadNormQltyLe 300;
BA_REL_ "GenSigFirstTimeoutTime" BU_SG_REL_ EBS SG_ 554 EstAxle2_WhlRdEstRi 3000;
BA_REL_ "GenSigTimeoutTime" BU_SG_REL_ EBS SG_ 554 EstAxle2_WhlRdEstRi 300;
BA_REL_ "GenSigFirstTimeoutTime" BU_SG_REL_ EBS SG_ 554 EstAxle3_WhlRdEstQltyRi 3000;
BA_REL_ "GenSigTimeoutTime" BU_SG_REL_ EBS SG_ 554 EstAxle3_WhlRdEstQltyRi 300;
BA_REL_ "GenSigFirstTimeoutTime" BU_SG_REL_ EBS SG_ 554 EstAxle1_LoadNormLe 3000;
BA_REL_ "GenSigTimeoutTime" BU_SG_REL_ EBS SG_ 554 EstAxle1_LoadNormLe 300;
BA_REL_ "GenSigFirstTimeoutTime" BU_SG_REL_ EBS SG_ 554 EstAxle1_CRC 3000;
BA_REL_ "GenSigTimeoutTime" BU_SG_REL_ EBS SG_ 554 EstAxle1_CRC 300;
BA_REL_ "GenSigFirstTimeoutTime" BU_SG_REL_ EBS SG_ 554 EstAxle5_WhlRdEstRi 3000;
BA_REL_ "GenSigTimeoutTime" BU_SG_REL_ EBS SG_ 554 EstAxle5_WhlRdEstRi 300;
BA_REL_ "GenSigFirstTimeoutTime" BU_SG_REL_ EBS SG_ 554 EstAxle2_CRC 3000;
BA_REL_ "GenSigTimeoutTime" BU_SG_REL_ EBS SG_ 554 EstAxle2_CRC 300;
BA_REL_ "GenSigFirstTimeoutTime" BU_SG_REL_ EBS SG_ 554 EstAxle1_LoadNormRi 3000;
BA_REL_ "GenSigTimeoutTime" BU_SG_REL_ EBS SG_ 554 EstAxle1_LoadNormRi 300;
BA_REL_ "GenSigFirstTimeoutTime" BU_SG_REL_ EBS SG_ 554 EstAxle2_WhlRdEstQltyLe 3000;
BA_REL_ "GenSigTimeoutTime" BU_SG_REL_ EBS SG_ 554 EstAxle2_WhlRdEstQltyLe 300;
BA_REL_ "GenSigFirstTimeoutTime" BU_SG_REL_ EBS SG_ 554 EstAxle4_CRC 3000;
BA_REL_ "GenSigTimeoutTime" BU_SG_REL_ EBS SG_ 554 EstAxle4_CRC 300;
BA_REL_ "GenSigFirstTimeoutTime" BU_SG_REL_ EBS SG_ 554 EstAxle3_LoadNormRi 3000;
BA_REL_ "GenSigTimeoutTime" BU_SG_REL_ EBS SG_ 554 EstAxle3_LoadNormRi 300;
BA_REL_ "GenSigFirstTimeoutTime" BU_SG_REL_ EBS SG_ 554 EstAxle5_WhlRdEstQltyLe 3000;
BA_REL_ "GenSigTimeoutTime" BU_SG_REL_ EBS SG_ 554 EstAxle5_WhlRdEstQltyLe 300;
BA_REL_ "GenSigFirstTimeoutTime" BU_SG_REL_ EBS SG_ 554 EstAxle3_SqC 3000;
BA_REL_ "GenSigTimeoutTime" BU_SG_REL_ EBS SG_ 554 EstAxle3_SqC 300;
BA_REL_ "GenSigFirstTimeoutTime" BU_SG_REL_ EBS SG_ 554 EstAxle1_WhlRdEstLe 3000;
BA_REL_ "GenSigTimeoutTime" BU_SG_REL_ EBS SG_ 554 EstAxle1_WhlRdEstLe 300;
BA_REL_ "GenSigFirstTimeoutTime" BU_SG_REL_ EBS SG_ 554 EstAxle4_LoadNormLe 3000;
BA_REL_ "GenSigTimeoutTime" BU_SG_REL_ EBS SG_ 554 EstAxle4_LoadNormLe 300;
BA_REL_ "GenSigFirstTimeoutTime" BU_SG_REL_ EBS SG_ 554 EstAxle1_SqC 3000;
BA_REL_ "GenSigTimeoutTime" BU_SG_REL_ EBS SG_ 554 EstAxle1_SqC 300;
BA_REL_ "GenSigFirstTimeoutTime" BU_SG_REL_ EBS SG_ 554 EstAxle1_WhlRdEstQltyRi 3000;
BA_REL_ "GenSigTimeoutTime" BU_SG_REL_ EBS SG_ 554 EstAxle1_WhlRdEstQltyRi 300;
BA_REL_ "GenSigFirstTimeoutTime" BU_SG_REL_ EBS SG_ 554 EstAxle2_SqC 3000;
BA_REL_ "GenSigTimeoutTime" BU_SG_REL_ EBS SG_ 554 EstAxle2_SqC 300;
BA_REL_ "GenSigFirstTimeoutTime" BU_SG_REL_ EBS SG_ 554 EstAxle3_WhlRdEstLe 3000;
BA_REL_ "GenSigTimeoutTime" BU_SG_REL_ EBS SG_ 554 EstAxle3_WhlRdEstLe 300;
BA_REL_ "GenSigFirstTimeoutTime" BU_SG_REL_ APM SG_ 631 TrsmEngdForPropulsion_SqC 3000;
BA_REL_ "GenSigTimeoutTime" BU_SG_REL_ APM SG_ 631 TrsmEngdForPropulsion_SqC 300;
BA_REL_ "GenSigFirstTimeoutTime" BU_SG_REL_ APM SG_ 631 TrsmEngdForPropulsion_Status 3000;
BA_REL_ "GenSigTimeoutTime" BU_SG_REL_ APM SG_ 631 TrsmEngdForPropulsion_Status 300;
BA_REL_ "GenSigFirstTimeoutTime" BU_SG_REL_ APM SG_ 631 XPRGReqPropDemTc_SqC 3000;
BA_REL_ "GenSigTimeoutTime" BU_SG_REL_ APM SG_ 631 XPRGReqPropDemTc_SqC 300;
BA_REL_ "GenSigFirstTimeoutTime" BU_SG_REL_ APM SG_ 631 TrsmEngdForPropulsion_CRC 3000;
BA_REL_ "GenSigTimeoutTime" BU_SG_REL_ APM SG_ 631 TrsmEngdForPropulsion_CRC 300;
BA_REL_ "GenSigFirstTimeoutTime" BU_SG_REL_ APM SG_ 631 XPRGReqPropDemTl_TlPropControl 3000;
BA_REL_ "GenSigTimeoutTime" BU_SG_REL_ APM SG_ 631 XPRGReqPropDemTl_TlPropControl 300;
BA_REL_ "GenSigFirstTimeoutTime" BU_SG_REL_ APM SG_ 631 XPRGReqMain_AddVlvRelIhnibition 3000;
BA_REL_ "GenSigTimeoutTime" BU_SG_REL_ APM SG_ 631 XPRGReqMain_AddVlvRelIhnibition 300;
BA_REL_ "GenSigFirstTimeoutTime" BU_SG_REL_ APM SG_ 631 XPRGReqMain_PBValveCtrl 3000;
BA_REL_ "GenSigTimeoutTime" BU_SG_REL_ APM SG_ 631 XPRGReqMain_PBValveCtrl 300;
BA_REL_ "GenSigFirstTimeoutTime" BU_SG_REL_ APM SG_ 631 DriverLocation_Status_ISig_3 3000;
BA_REL_ "GenSigTimeoutTime" BU_SG_REL_ APM SG_ 631 DriverLocation_Status_ISig_3 300;
BA_REL_ "GenSigFirstTimeoutTime" BU_SG_REL_ APM SG_ 631 TachographVehicleSpeed 3000;
BA_REL_ "GenSigTimeoutTime" BU_SG_REL_ APM SG_ 631 TachographVehicleSpeed 300;
BA_REL_ "GenSigFirstTimeoutTime" BU_SG_REL_ EBS SG_ 631 XPRsystemstate 3000;
BA_REL_ "GenSigTimeoutTime" BU_SG_REL_ EBS SG_ 631 XPRsystemstate 300;
BA_REL_ "GenSigFirstTimeoutTime" BU_SG_REL_ APM SG_ 631 XPRGReqMain_AddValveCtrlMode 3000;
BA_REL_ "GenSigTimeoutTime" BU_SG_REL_ APM SG_ 631 XPRGReqMain_AddValveCtrlMode 300;
BA_REL_ "GenSigFirstTimeoutTime" BU_SG_REL_ APM SG_ 631 XPRGReqMain_CRC 3000;
BA_REL_ "GenSigTimeoutTime" BU_SG_REL_ APM SG_ 631 XPRGReqMain_CRC 300;
BA_REL_ "GenSigFirstTimeoutTime" BU_SG_REL_ APM SG_ 631 XPRGReqMain_AddValveCtrl 3000;
BA_REL_ "GenSigTimeoutTime" BU_SG_REL_ APM SG_ 631 XPRGReqMain_AddValveCtrl 300;
BA_REL_ "GenSigFirstTimeoutTime" BU_SG_REL_ APM SG_ 631 BacklightCmd_ISig_3 3000;
BA_REL_ "GenSigTimeoutTime" BU_SG_REL_ APM SG_ 631 BacklightCmd_ISig_3 300;
BA_REL_ "GenSigFirstTimeoutTime" BU_SG_REL_ APM SG_ 631 XPRGReqPropDemTl_SqC 3000;
BA_REL_ "GenSigTimeoutTime" BU_SG_REL_ APM SG_ 631 XPRGReqPropDemTl_SqC 300;
BA_REL_ "GenSigFirstTimeoutTime" BU_SG_REL_ APM SG_ 631 DoorsAjar_stat_ISig_3 3000;
BA_REL_ "GenSigTimeoutTime" BU_SG_REL_ APM SG_ 631 DoorsAjar_stat_ISig_3 300;
BA_REL_ "GenSigFirstTimeoutTime" BU_SG_REL_ APM SG_ 631 XPRGReqPropDemTl_CRC 3000;
BA_REL_ "GenSigTimeoutTime" BU_SG_REL_ APM SG_ 631 XPRGReqPropDemTl_CRC 300;
BA_REL_ "GenSigFirstTimeoutTime" BU_SG_REL_ APM SG_ 631 XPRGReqMain_SqC 3000;
BA_REL_ "GenSigTimeoutTime" BU_SG_REL_ APM SG_ 631 XPRGReqMain_SqC 300;
BA_REL_ "GenSigFirstTimeoutTime" BU_SG_REL_ APM SG_ 631 XPRGReqPropDemTc_TypeControl 3000;
BA_REL_ "GenSigTimeoutTime" BU_SG_REL_ APM SG_ 631 XPRGReqPropDemTc_TypeControl 300;
BA_REL_ "GenSigFirstTimeoutTime" BU_SG_REL_ APM SG_ 631 CartridgeChangedDrvrReset_rqst_I 3000;
BA_REL_ "GenSigTimeoutTime" BU_SG_REL_ APM SG_ 631 CartridgeChangedDrvrReset_rqst_I 300;
BA_REL_ "GenSigFirstTimeoutTime" BU_SG_REL_ APM SG_ 631 DriverLocation_ConfidenceLvl_ISi 3000;
BA_REL_ "GenSigTimeoutTime" BU_SG_REL_ APM SG_ 631 DriverLocation_ConfidenceLvl_ISi 300;
BA_REL_ "GenSigFirstTimeoutTime" BU_SG_REL_ APM SG_ 631 DriverLocation_CRC_ISig_3 3000;
BA_REL_ "GenSigTimeoutTime" BU_SG_REL_ APM SG_ 631 DriverLocation_CRC_ISig_3 300;
BA_REL_ "GenSigFirstTimeoutTime" BU_SG_REL_ APM SG_ 631 XPRGReqPropDemTl_TypeControl 3000;
BA_REL_ "GenSigTimeoutTime" BU_SG_REL_ APM SG_ 631 XPRGReqPropDemTl_TypeControl 300;
BA_REL_ "GenSigFirstTimeoutTime" BU_SG_REL_ APM SG_ 631 XPRGReqMain_RequestPriority 3000;
BA_REL_ "GenSigTimeoutTime" BU_SG_REL_ APM SG_ 631 XPRGReqMain_RequestPriority 300;
BA_REL_ "GenSigFirstTimeoutTime" BU_SG_REL_ APM SG_ 631 XPRGReqPropDemTc_CRC 3000;
BA_REL_ "GenSigTimeoutTime" BU_SG_REL_ APM SG_ 631 XPRGReqPropDemTc_CRC 300;
BA_REL_ "GenSigFirstTimeoutTime" BU_SG_REL_ APM SG_ 631 FuncIndIlluminationLevel_ISig_3 3000;
BA_REL_ "GenSigTimeoutTime" BU_SG_REL_ APM SG_ 631 FuncIndIlluminationLevel_ISig_3 300;
BA_REL_ "GenSigFirstTimeoutTime" BU_SG_REL_ EBS SG_ 631 TrailerABSStatus_ISig_3 3000;
BA_REL_ "GenSigTimeoutTime" BU_SG_REL_ EBS SG_ 631 TrailerABSStatus_ISig_3 300;
BA_REL_ "GenSigFirstTimeoutTime" BU_SG_REL_ APM SG_ 631 DriverLocation_SqC_ISig_3 3000;
BA_REL_ "GenSigTimeoutTime" BU_SG_REL_ APM SG_ 631 DriverLocation_SqC_ISig_3 300;
BA_REL_ "GenSigFirstTimeoutTime" BU_SG_REL_ APM SG_ 631 XPRGReqMain_PBVlvRelInhibition 3000;
BA_REL_ "GenSigTimeoutTime" BU_SG_REL_ APM SG_ 631 XPRGReqMain_PBVlvRelInhibition 300;
BA_REL_ "GenSigFirstTimeoutTime" BU_SG_REL_ APM SG_ 631 XPRGReqPropDemTc_TcPropControl 3000;
BA_REL_ "GenSigTimeoutTime" BU_SG_REL_ APM SG_ 631 XPRGReqPropDemTc_TcPropControl 300;
BA_REL_ "GenSigFirstTimeoutTime" BU_SG_REL_ FAS SG_ 1448 TotalVehicleDistanceHighRes_ISig 24000;
BA_REL_ "GenSigTimeoutTime" BU_SG_REL_ FAS SG_ 1448 TotalVehicleDistanceHighRes_ISig 6000;
BA_REL_ "GenSigFirstTimeoutTime" BU_SG_REL_ APM SG_ 1448 TotalVehicleDistanceHighRes_ISig 24000;
BA_REL_ "GenSigTimeoutTime" BU_SG_REL_ APM SG_ 1448 TotalVehicleDistanceHighRes_ISig 6000;
BA_REL_ "GenSigFirstTimeoutTime" BU_SG_REL_ FAS SG_ 1448 AmbientAirTemperature_ISig_3 24000;
BA_REL_ "GenSigTimeoutTime" BU_SG_REL_ FAS SG_ 1448 AmbientAirTemperature_ISig_3 6000;
BA_REL_ "GenSigFirstTimeoutTime" BU_SG_REL_ APM SG_ 1448 AmbientAirTemperature_ISig_3 24000;
BA_REL_ "GenSigTimeoutTime" BU_SG_REL_ APM SG_ 1448 AmbientAirTemperature_ISig_3 6000;
BA_REL_ "GenSigFirstTimeoutTime" BU_SG_REL_ FAS SG_ 1319 YearUTC_ISig_3 6000;
BA_REL_ "GenSigTimeoutTime" BU_SG_REL_ FAS SG_ 1319 YearUTC_ISig_3 1500;
BA_REL_ "GenSigFirstTimeoutTime" BU_SG_REL_ APM SG_ 1319 YearUTC_ISig_3 6000;
BA_REL_ "GenSigTimeoutTime" BU_SG_REL_ APM SG_ 1319 YearUTC_ISig_3 1500;
BA_REL_ "GenSigFirstTimeoutTime" BU_SG_REL_ FAS SG_ 1319 SecondsUTC_ISig_3 6000;
BA_REL_ "GenSigTimeoutTime" BU_SG_REL_ FAS SG_ 1319 SecondsUTC_ISig_3 1500;
BA_REL_ "GenSigFirstTimeoutTime" BU_SG_REL_ APM SG_ 1319 SecondsUTC_ISig_3 6000;
BA_REL_ "GenSigTimeoutTime" BU_SG_REL_ APM SG_ 1319 SecondsUTC_ISig_3 1500;
BA_REL_ "GenSigFirstTimeoutTime" BU_SG_REL_ FAS SG_ 1319 DayUTC_ISig_3 6000;
BA_REL_ "GenSigTimeoutTime" BU_SG_REL_ FAS SG_ 1319 DayUTC_ISig_3 1500;
BA_REL_ "GenSigFirstTimeoutTime" BU_SG_REL_ APM SG_ 1319 DayUTC_ISig_3 6000;
BA_REL_ "GenSigTimeoutTime" BU_SG_REL_ APM SG_ 1319 DayUTC_ISig_3 1500;
BA_REL_ "GenSigFirstTimeoutTime" BU_SG_REL_ APM SG_ 1319 MonthUTC_ISig_3 6000;
BA_REL_ "GenSigTimeoutTime" BU_SG_REL_ APM SG_ 1319 MonthUTC_ISig_3 1500;
BA_REL_ "GenSigFirstTimeoutTime" BU_SG_REL_ FAS SG_ 1319 MonthUTC_ISig_3 6000;
BA_REL_ "GenSigTimeoutTime" BU_SG_REL_ FAS SG_ 1319 MonthUTC_ISig_3 1500;
BA_REL_ "GenSigFirstTimeoutTime" BU_SG_REL_ APM SG_ 1319 HoursUTC_ISig_3 6000;
BA_REL_ "GenSigTimeoutTime" BU_SG_REL_ APM SG_ 1319 HoursUTC_ISig_3 1500;
BA_REL_ "GenSigFirstTimeoutTime" BU_SG_REL_ FAS SG_ 1319 HoursUTC_ISig_3 6000;
BA_REL_ "GenSigTimeoutTime" BU_SG_REL_ FAS SG_ 1319 HoursUTC_ISig_3 1500;
BA_REL_ "GenSigFirstTimeoutTime" BU_SG_REL_ APM SG_ 1319 MinutesUTC_ISig_3 6000;
BA_REL_ "GenSigTimeoutTime" BU_SG_REL_ APM SG_ 1319 MinutesUTC_ISig_3 1500;
BA_REL_ "GenSigFirstTimeoutTime" BU_SG_REL_ FAS SG_ 1319 MinutesUTC_ISig_3 6000;
BA_REL_ "GenSigTimeoutTime" BU_SG_REL_ FAS SG_ 1319 MinutesUTC_ISig_3 1500;
BA_REL_ "GenSigFirstTimeoutTime" BU_SG_REL_ APM SG_ 1447 AirDryerCartdgeTypeReset 24000;
BA_REL_ "GenSigTimeoutTime" BU_SG_REL_ APM SG_ 1447 AirDryerCartdgeTypeReset 6000;
BA_REL_ "GenSigFirstTimeoutTime" BU_SG_REL_ FAS SG_ 1447 FasDampingSetting_rqst_ISig_3 24000;
BA_REL_ "GenSigTimeoutTime" BU_SG_REL_ FAS SG_ 1447 FasDampingSetting_rqst_ISig_3 6000;
BA_REL_ "GenSigFirstTimeoutTime" BU_SG_REL_ FAS SG_ 1447 DriverMemory_rqst_ISig_3 24000;
BA_REL_ "GenSigTimeoutTime" BU_SG_REL_ FAS SG_ 1447 DriverMemory_rqst_ISig_3 6000;
BA_REL_ "GenSigFirstTimeoutTime" BU_SG_REL_ FAS SG_ 1447 FasDriver_rqst_ISig_3 24000;
BA_REL_ "GenSigTimeoutTime" BU_SG_REL_ FAS SG_ 1447 FasDriver_rqst_ISig_3 6000;
BA_REL_ "GenSigFirstTimeoutTime" BU_SG_REL_ FAS SG_ 1447 FasLowSpeedReturnSetting_rqst_IS 24000;
BA_REL_ "GenSigTimeoutTime" BU_SG_REL_ FAS SG_ 1447 FasLowSpeedReturnSetting_rqst_IS 6000;
BA_REL_ "GenSigFirstTimeoutTime" BU_SG_REL_ FAS SG_ 1447 FasPersonalSettingsButton_rqst_I 24000;
BA_REL_ "GenSigTimeoutTime" BU_SG_REL_ FAS SG_ 1447 FasPersonalSettingsButton_rqst_I 6000;
BA_REL_ "GenSigFirstTimeoutTime" BU_SG_REL_ FAS SG_ 1447 FasStiffnessCurveSetting_rqst_IS 24000;
BA_REL_ "GenSigTimeoutTime" BU_SG_REL_ FAS SG_ 1447 FasStiffnessCurveSetting_rqst_IS 6000;
BA_REL_ "GenSigFirstTimeoutTime" BU_SG_REL_ FAS SG_ 1447 FasUsrDefinedStorage_rqst_ISig_3 24000;
BA_REL_ "GenSigTimeoutTime" BU_SG_REL_ FAS SG_ 1447 FasUsrDefinedStorage_rqst_ISig_3 6000;
BA_REL_ "GenSigFirstTimeoutTime" BU_SG_REL_ FAS SG_ 1447 FasManualOffsetSetting_rqst_ISig 24000;
BA_REL_ "GenSigTimeoutTime" BU_SG_REL_ FAS SG_ 1447 FasManualOffsetSetting_rqst_ISig 6000;
BA_REL_ "GenSigFirstTimeoutTime" BU_SG_REL_ FAS SG_ 1447 FasStiffStraightSetting_rqst_ISi 24000;
BA_REL_ "GenSigTimeoutTime" BU_SG_REL_ FAS SG_ 1447 FasStiffStraightSetting_rqst_ISi 6000;
BA_REL_ "GenSigFirstTimeoutTime" BU_SG_REL_ EBS SG_ 1034 RelativeLevelFrontAxleRight_ISig 3000;
BA_REL_ "GenSigTimeoutTime" BU_SG_REL_ EBS SG_ 1034 RelativeLevelFrontAxleRight_ISig 600;
BA_REL_ "GenSigFirstTimeoutTime" BU_SG_REL_ FAS SG_ 1034 RelativeLevelFrontAxleLeft_ISig_ 3000;
BA_REL_ "GenSigTimeoutTime" BU_SG_REL_ FAS SG_ 1034 RelativeLevelFrontAxleLeft_ISig_ 600;
BA_REL_ "GenSigFirstTimeoutTime" BU_SG_REL_ EBS SG_ 1034 RelativeLevelFrontAxleLeft_ISig_ 3000;
BA_REL_ "GenSigTimeoutTime" BU_SG_REL_ EBS SG_ 1034 RelativeLevelFrontAxleLeft_ISig_ 600;
BA_REL_ "GenSigFirstTimeoutTime" BU_SG_REL_ FAS SG_ 1034 FrontAxle1Load_ISig_3 3000;
BA_REL_ "GenSigTimeoutTime" BU_SG_REL_ FAS SG_ 1034 FrontAxle1Load_ISig_3 600;
BA_REL_ "GenSigFirstTimeoutTime" BU_SG_REL_ EBS SG_ 1034 FrontAxle1Load_ISig_3 3000;
BA_REL_ "GenSigTimeoutTime" BU_SG_REL_ EBS SG_ 1034 FrontAxle1Load_ISig_3 600;
BA_REL_ "GenSigFirstTimeoutTime" BU_SG_REL_ FAS SG_ 1034 PusherAxleLoad_ISig_3 3000;
BA_REL_ "GenSigTimeoutTime" BU_SG_REL_ FAS SG_ 1034 PusherAxleLoad_ISig_3 600;
BA_REL_ "GenSigFirstTimeoutTime" BU_SG_REL_ EBS SG_ 1034 PusherAxleLoad_ISig_3 3000;
BA_REL_ "GenSigTimeoutTime" BU_SG_REL_ EBS SG_ 1034 PusherAxleLoad_ISig_3 600;
BA_REL_ "GenSigFirstTimeoutTime" BU_SG_REL_ APM SG_ 1034 AirConsumptionStatus 3000;
BA_REL_ "GenSigTimeoutTime" BU_SG_REL_ APM SG_ 1034 AirConsumptionStatus 600;
BA_REL_ "GenSigFirstTimeoutTime" BU_SG_REL_ APM SG_ 1034 UnloadValveOperationRqst 3000;
BA_REL_ "GenSigTimeoutTime" BU_SG_REL_ APM SG_ 1034 UnloadValveOperationRqst 600;
BA_REL_ "GenSigFirstTimeoutTime" BU_SG_REL_ FAS SG_ 1034 SecondaryDriveAxleLoad_ISig_3 3000;
BA_REL_ "GenSigTimeoutTime" BU_SG_REL_ FAS SG_ 1034 SecondaryDriveAxleLoad_ISig_3 600;
BA_REL_ "GenSigFirstTimeoutTime" BU_SG_REL_ EBS SG_ 1034 SecondaryDriveAxleLoad_ISig_3 3000;
BA_REL_ "GenSigTimeoutTime" BU_SG_REL_ EBS SG_ 1034 SecondaryDriveAxleLoad_ISig_3 600;
BA_REL_ "GenSigFirstTimeoutTime" BU_SG_REL_ EBS SG_ 1034 RelativeLevelRearAxleLeft_ISig_3 3000;
BA_REL_ "GenSigTimeoutTime" BU_SG_REL_ EBS SG_ 1034 RelativeLevelRearAxleLeft_ISig_3 600;
BA_REL_ "GenSigFirstTimeoutTime" BU_SG_REL_ FAS SG_ 1034 TagAxleLoad_ISig_3 3000;
BA_REL_ "GenSigTimeoutTime" BU_SG_REL_ FAS SG_ 1034 TagAxleLoad_ISig_3 600;
BA_REL_ "GenSigFirstTimeoutTime" BU_SG_REL_ EBS SG_ 1034 TagAxleLoad_ISig_3 3000;
BA_REL_ "GenSigTimeoutTime" BU_SG_REL_ EBS SG_ 1034 TagAxleLoad_ISig_3 600;
BA_REL_ "GenSigFirstTimeoutTime" BU_SG_REL_ APM SG_ 1034 TransmissionCurrentGear_ISig_3 3000;
BA_REL_ "GenSigTimeoutTime" BU_SG_REL_ APM SG_ 1034 TransmissionCurrentGear_ISig_3 600;
BA_REL_ "GenSigFirstTimeoutTime" BU_SG_REL_ EBS SG_ 1034 ContTrailerBrake_MsgCounter 3000;
BA_REL_ "GenSigTimeoutTime" BU_SG_REL_ EBS SG_ 1034 ContTrailerBrake_MsgCounter 600;
BA_REL_ "GenSigFirstTimeoutTime" BU_SG_REL_ APM SG_ 1034 AirProductionPressureRangeMode 3000;
BA_REL_ "GenSigTimeoutTime" BU_SG_REL_ APM SG_ 1034 AirProductionPressureRangeMode 600;
BA_REL_ "GenSigFirstTimeoutTime" BU_SG_REL_ APM SG_ 1034 BrakeSwitch_ISig_3 3000;
BA_REL_ "GenSigTimeoutTime" BU_SG_REL_ APM SG_ 1034 BrakeSwitch_ISig_3 600;
BA_REL_ "GenSigFirstTimeoutTime" BU_SG_REL_ FAS SG_ 1034 FrontAxle2Load_ISig_3 3000;
BA_REL_ "GenSigTimeoutTime" BU_SG_REL_ FAS SG_ 1034 FrontAxle2Load_ISig_3 600;
BA_REL_ "GenSigFirstTimeoutTime" BU_SG_REL_ EBS SG_ 1034 FrontAxle2Load_ISig_3 3000;
BA_REL_ "GenSigTimeoutTime" BU_SG_REL_ EBS SG_ 1034 FrontAxle2Load_ISig_3 600;
BA_REL_ "GenSigFirstTimeoutTime" BU_SG_REL_ EBS SG_ 1034 DriveAxleLoad_ISig_3 3000;
BA_REL_ "GenSigTimeoutTime" BU_SG_REL_ EBS SG_ 1034 DriveAxleLoad_ISig_3 600;
BA_REL_ "GenSigFirstTimeoutTime" BU_SG_REL_ FAS SG_ 1034 DriveAxleLoad_ISig_3 3000;
BA_REL_ "GenSigTimeoutTime" BU_SG_REL_ FAS SG_ 1034 DriveAxleLoad_ISig_3 600;
BA_REL_ "GenSigFirstTimeoutTime" BU_SG_REL_ EBS SG_ 1034 ContTrailerBrake_MsgChecksum 3000;
BA_REL_ "GenSigTimeoutTime" BU_SG_REL_ EBS SG_ 1034 ContTrailerBrake_MsgChecksum 600;
BA_REL_ "GenSigFirstTimeoutTime" BU_SG_REL_ EBS SG_ 1034 TertiaryDriveAxleLoad_ISig_3 3000;
BA_REL_ "GenSigTimeoutTime" BU_SG_REL_ EBS SG_ 1034 TertiaryDriveAxleLoad_ISig_3 600;
BA_REL_ "GenSigFirstTimeoutTime" BU_SG_REL_ APM SG_ 1034 ElAirCompActualSpeed 3000;
BA_REL_ "GenSigTimeoutTime" BU_SG_REL_ APM SG_ 1034 ElAirCompActualSpeed 600;
BA_REL_ "GenSigFirstTimeoutTime" BU_SG_REL_ APM SG_ 1034 ElAirCompOperationStat 3000;
BA_REL_ "GenSigTimeoutTime" BU_SG_REL_ APM SG_ 1034 ElAirCompOperationStat 600;
BA_REL_ "GenSigFirstTimeoutTime" BU_SG_REL_ APM SG_ 1034 VIN_rqst_ISig_3 3000;
BA_REL_ "GenSigTimeoutTime" BU_SG_REL_ APM SG_ 1034 VIN_rqst_ISig_3 600;
BA_REL_ "GenSigFirstTimeoutTime" BU_SG_REL_ APM SG_ 1034 TrailerConnected_ISig_3 3000;
BA_REL_ "GenSigTimeoutTime" BU_SG_REL_ APM SG_ 1034 TrailerConnected_ISig_3 600;
BA_REL_ "GenSigFirstTimeoutTime" BU_SG_REL_ EBS SG_ 1034 ContTrailerBrake_Request 3000;
BA_REL_ "GenSigTimeoutTime" BU_SG_REL_ EBS SG_ 1034 ContTrailerBrake_Request 600;
BA_REL_ "GenSigFirstTimeoutTime" BU_SG_REL_ EBS SG_ 1034 RelativeLevelRearAxleRight_ISig_ 3000;
BA_REL_ "GenSigTimeoutTime" BU_SG_REL_ EBS SG_ 1034 RelativeLevelRearAxleRight_ISig_ 600;
BA_REL_ "GenSigFirstTimeoutTime" BU_SG_REL_ EBS SG_ 426 ChangeKneelACK_ISig_3 3000;
BA_REL_ "GenSigTimeoutTime" BU_SG_REL_ EBS SG_ 426 ChangeKneelACK_ISig_3 120;
BA_REL_ "GenSigFirstTimeoutTime" BU_SG_REL_ APM SG_ 426 EngineSpeed_ISig_3 3000;
BA_REL_ "GenSigTimeoutTime" BU_SG_REL_ APM SG_ 426 EngineSpeed_ISig_3 120;
BA_REL_ "GenSigFirstTimeoutTime" BU_SG_REL_ EBS SG_ 426 SecuredNeutralPosition_ISig_3 3000;
BA_REL_ "GenSigTimeoutTime" BU_SG_REL_ EBS SG_ 426 SecuredNeutralPosition_ISig_3 120;
BA_REL_ "GenSigFirstTimeoutTime" BU_SG_REL_ APM SG_ 426 SecuredNeutralPosition_ISig_3 3000;
BA_REL_ "GenSigTimeoutTime" BU_SG_REL_ APM SG_ 426 SecuredNeutralPosition_ISig_3 120;
BA_REL_ "GenSigFirstTimeoutTime" BU_SG_REL_ EBS SG_ 426 LiftAxle1PositionStatus_ISig_3 3000;
BA_REL_ "GenSigTimeoutTime" BU_SG_REL_ EBS SG_ 426 LiftAxle1PositionStatus_ISig_3 120;
BA_REL_ "GenSigFirstTimeoutTime" BU_SG_REL_ EBS SG_ 426 FrontFerryFunctionCmd_ISig_3 3000;
BA_REL_ "GenSigTimeoutTime" BU_SG_REL_ EBS SG_ 426 FrontFerryFunctionCmd_ISig_3 120;
BA_REL_ "GenSigFirstTimeoutTime" BU_SG_REL_ FAS SG_ 426 ReverseGearEngaged_ISig_3 3000;
BA_REL_ "GenSigTimeoutTime" BU_SG_REL_ FAS SG_ 426 ReverseGearEngaged_ISig_3 120;
BA_REL_ "GenSigFirstTimeoutTime" BU_SG_REL_ EBS SG_ 426 AirDumpStatus_ISig_3 3000;
BA_REL_ "GenSigTimeoutTime" BU_SG_REL_ EBS SG_ 426 AirDumpStatus_ISig_3 120;
BA_REL_ "GenSigFirstTimeoutTime" BU_SG_REL_ FAS SG_ 426 EngineActiveStatus_ISig_3 3000;
BA_REL_ "GenSigTimeoutTime" BU_SG_REL_ FAS SG_ 426 EngineActiveStatus_ISig_3 120;
BA_REL_ "GenSigFirstTimeoutTime" BU_SG_REL_ APM SG_ 426 EngineActiveStatus_ISig_3 3000;
BA_REL_ "GenSigTimeoutTime" BU_SG_REL_ APM SG_ 426 EngineActiveStatus_ISig_3 120;
BA_REL_ "GenSigFirstTimeoutTime" BU_SG_REL_ EBS SG_ 426 FerryFunctionStatus_ISig_3 3000;
BA_REL_ "GenSigTimeoutTime" BU_SG_REL_ EBS SG_ 426 FerryFunctionStatus_ISig_3 120;
BA_REL_ "GenSigFirstTimeoutTime" BU_SG_REL_ EBS SG_ 426 PitchAngleRef_ISig_3 3000;
BA_REL_ "GenSigTimeoutTime" BU_SG_REL_ EBS SG_ 426 PitchAngleRef_ISig_3 120;
BA_REL_ "GenSigFirstTimeoutTime" BU_SG_REL_ EBS SG_ 426 KneelingInformation_ISig_3 3000;
BA_REL_ "GenSigTimeoutTime" BU_SG_REL_ EBS SG_ 426 KneelingInformation_ISig_3 120;
BA_REL_ "GenSigFirstTimeoutTime" BU_SG_REL_ FAS SG_ 426 FASHapticFeedbackRequest 3000;
BA_REL_ "GenSigTimeoutTime" BU_SG_REL_ FAS SG_ 426 FASHapticFeedbackRequest 120;
BA_REL_ "GenSigFirstTimeoutTime" BU_SG_REL_ EBS SG_ 426 HeightControlMode_ISig_3 3000;
BA_REL_ "GenSigTimeoutTime" BU_SG_REL_ EBS SG_ 426 HeightControlMode_ISig_3 120;
BA_REL_ "GenSigFirstTimeoutTime" BU_SG_REL_ EBS SG_ 426 LoadDistributionFuncSelected_ISi 3000;
BA_REL_ "GenSigTimeoutTime" BU_SG_REL_ EBS SG_ 426 LoadDistributionFuncSelected_ISi 120;
BA_REL_ "GenSigFirstTimeoutTime" BU_SG_REL_ EBS SG_ 426 PitchAngle_ISig_3 3000;
BA_REL_ "GenSigTimeoutTime" BU_SG_REL_ EBS SG_ 426 PitchAngle_ISig_3 120;
BA_REL_ "GenSigFirstTimeoutTime" BU_SG_REL_ EBS SG_ 426 RollEndPositionStatus_ISig_3 3000;
BA_REL_ "GenSigTimeoutTime" BU_SG_REL_ EBS SG_ 426 RollEndPositionStatus_ISig_3 120;
BA_REL_ "GenSigFirstTimeoutTime" BU_SG_REL_ EBS SG_ 426 SupplyPressure_ISig_3 3000;
BA_REL_ "GenSigTimeoutTime" BU_SG_REL_ EBS SG_ 426 SupplyPressure_ISig_3 120;
BA_REL_ "GenSigFirstTimeoutTime" BU_SG_REL_ FAS SG_ 426 WheelBasedVehicleSpeed_ISig_3 3000;
BA_REL_ "GenSigTimeoutTime" BU_SG_REL_ FAS SG_ 426 WheelBasedVehicleSpeed_ISig_3 120;
BA_REL_ "GenSigFirstTimeoutTime" BU_SG_REL_ APM SG_ 426 WheelBasedVehicleSpeed_ISig_3 3000;
BA_REL_ "GenSigTimeoutTime" BU_SG_REL_ APM SG_ 426 WheelBasedVehicleSpeed_ISig_3 120;
BA_REL_ "GenSigFirstTimeoutTime" BU_SG_REL_ APM SG_ 426 XBRSystemState2_Status 3000;
BA_REL_ "GenSigTimeoutTime" BU_SG_REL_ APM SG_ 426 XBRSystemState2_Status 120;
BA_REL_ "GenSigFirstTimeoutTime" BU_SG_REL_ EBS SG_ 426 RearAxle2DiffLock_stat_ISig_3 3000;
BA_REL_ "GenSigTimeoutTime" BU_SG_REL_ EBS SG_ 426 RearAxle2DiffLock_stat_ISig_3 120;
BA_REL_ "GenSigFirstTimeoutTime" BU_SG_REL_ EBS SG_ 426 KneelingStatusHMI_ISig_3 3000;
BA_REL_ "GenSigTimeoutTime" BU_SG_REL_ EBS SG_ 426 KneelingStatusHMI_ISig_3 120;
BA_REL_ "GenSigFirstTimeoutTime" BU_SG_REL_ EBS SG_ 426 HeightAdjustmentAllowed_ISig_3 3000;
BA_REL_ "GenSigTimeoutTime" BU_SG_REL_ EBS SG_ 426 HeightAdjustmentAllowed_ISig_3 120;
BA_REL_ "GenSigFirstTimeoutTime" BU_SG_REL_ EBS SG_ 426 RideHeightStatus_ISig_3 3000;
BA_REL_ "GenSigTimeoutTime" BU_SG_REL_ EBS SG_ 426 RideHeightStatus_ISig_3 120;
BA_REL_ "GenSigFirstTimeoutTime" BU_SG_REL_ EBS SG_ 426 CentralRearDiffLock_stat_ISig_3 3000;
BA_REL_ "GenSigTimeoutTime" BU_SG_REL_ EBS SG_ 426 CentralRearDiffLock_stat_ISig_3 120;
BA_REL_ "GenSigFirstTimeoutTime" BU_SG_REL_ APM SG_ 426 XBRSystemState2_CRC 3000;
BA_REL_ "GenSigTimeoutTime" BU_SG_REL_ APM SG_ 426 XBRSystemState2_CRC 120;
BA_REL_ "GenSigFirstTimeoutTime" BU_SG_REL_ EBS SG_ 426 LiftAxle2PositionStatus_ISig_3 3000;
BA_REL_ "GenSigTimeoutTime" BU_SG_REL_ EBS SG_ 426 LiftAxle2PositionStatus_ISig_3 120;
BA_REL_ "GenSigFirstTimeoutTime" BU_SG_REL_ EBS SG_ 426 RampHeightOutsideTargetRange_ISi 3000;
BA_REL_ "GenSigTimeoutTime" BU_SG_REL_ EBS SG_ 426 RampHeightOutsideTargetRange_ISi 120;
BA_REL_ "GenSigFirstTimeoutTime" BU_SG_REL_ EBS SG_ 426 DirInd_Rear_Status_ISig_3 3000;
BA_REL_ "GenSigTimeoutTime" BU_SG_REL_ EBS SG_ 426 DirInd_Rear_Status_ISig_3 120;
BA_REL_ "GenSigFirstTimeoutTime" BU_SG_REL_ FAS SG_ 426 ExternalRequestManualStiffness 3000;
BA_REL_ "GenSigTimeoutTime" BU_SG_REL_ FAS SG_ 426 ExternalRequestManualStiffness 120;
BA_REL_ "GenSigFirstTimeoutTime" BU_SG_REL_ EBS SG_ 426 PneumaticTrailerBrakeStatus_ISig 3000;
BA_REL_ "GenSigTimeoutTime" BU_SG_REL_ EBS SG_ 426 PneumaticTrailerBrakeStatus_ISig 120;
BA_REL_ "GenSigFirstTimeoutTime" BU_SG_REL_ APM SG_ 426 GearLeverPosition_ISig_3 3000;
BA_REL_ "GenSigTimeoutTime" BU_SG_REL_ APM SG_ 426 GearLeverPosition_ISig_3 120;
BA_REL_ "GenSigFirstTimeoutTime" BU_SG_REL_ EBS SG_ 426 VehicleDistanceRollingCounter 3000;
BA_REL_ "GenSigTimeoutTime" BU_SG_REL_ EBS SG_ 426 VehicleDistanceRollingCounter 120;
BA_REL_ "GenSigFirstTimeoutTime" BU_SG_REL_ EBS SG_ 426 BackToDriveReqACK_ISig_3 3000;
BA_REL_ "GenSigTimeoutTime" BU_SG_REL_ EBS SG_ 426 BackToDriveReqACK_ISig_3 120;
BA_REL_ "GenSigFirstTimeoutTime" BU_SG_REL_ APM SG_ 426 XBRSystemState2_SqC 3000;
BA_REL_ "GenSigTimeoutTime" BU_SG_REL_ APM SG_ 426 XBRSystemState2_SqC 120;
BA_REL_ "GenSigFirstTimeoutTime" BU_SG_REL_ EBS SG_ 426 ExtraAxleSteeringFunctionStat 3000;
BA_REL_ "GenSigTimeoutTime" BU_SG_REL_ EBS SG_ 426 ExtraAxleSteeringFunctionStat 120;
BA_REL_ "GenSigFirstTimeoutTime" BU_SG_REL_ EBS SG_ 426 RearAxle1DiffLock_stat_ISig_3 3000;
BA_REL_ "GenSigTimeoutTime" BU_SG_REL_ EBS SG_ 426 RearAxle1DiffLock_stat_ISig_3 120;
BA_REL_ "GenSigFirstTimeoutTime" BU_SG_REL_ EBS SG_ 426 LevelControlInformation_ISig_3 3000;
BA_REL_ "GenSigTimeoutTime" BU_SG_REL_ EBS SG_ 426 LevelControlInformation_ISig_3 120;
BA_REL_ "GenSigFirstTimeoutTime" BU_SG_REL_ APM SG_ 426 VehicleMode_ISig_3 3000;
BA_REL_ "GenSigTimeoutTime" BU_SG_REL_ APM SG_ 426 VehicleMode_ISig_3 120;
BA_REL_ "GenSigFirstTimeoutTime" BU_SG_REL_ FAS SG_ 426 VehicleMode_ISig_3 3000;
BA_REL_ "GenSigTimeoutTime" BU_SG_REL_ FAS SG_ 426 VehicleMode_ISig_3 120;
BA_REL_ "GenSigFirstTimeoutTime" BU_SG_REL_ FAS SG_ 426 ACC_SGO_Status_ISig_3 3000;
BA_REL_ "GenSigTimeoutTime" BU_SG_REL_ FAS SG_ 426 ACC_SGO_Status_ISig_3 120;
BA_REL_ "GenSigFirstTimeoutTime" BU_SG_REL_ EBS SG_ 426 RearEndPositionStatus_ISig_3 3000;
BA_REL_ "GenSigTimeoutTime" BU_SG_REL_ EBS SG_ 426 RearEndPositionStatus_ISig_3 120;
BA_REL_ "GenSigFirstTimeoutTime" BU_SG_REL_ APM SG_ 426 PBAlertActiveStatus_ISig_3 3000;
BA_REL_ "GenSigTimeoutTime" BU_SG_REL_ APM SG_ 426 PBAlertActiveStatus_ISig_3 120;
BA_REL_ "GenSigFirstTimeoutTime" BU_SG_REL_ EBS SG_ 426 ECSShutdownCmd_ISig_3 3000;
BA_REL_ "GenSigTimeoutTime" BU_SG_REL_ EBS SG_ 426 ECSShutdownCmd_ISig_3 120;
BA_REL_ "GenSigFirstTimeoutTime" BU_SG_REL_ EBS SG_ 426 VehicleDynamicSuspProhibitStat_I 3000;
BA_REL_ "GenSigTimeoutTime" BU_SG_REL_ EBS SG_ 426 VehicleDynamicSuspProhibitStat_I 120;
BA_REL_ "GenSigFirstTimeoutTime" BU_SG_REL_ EBS SG_ 426 RideHeightFunctionStatus_ISig_3 3000;
BA_REL_ "GenSigTimeoutTime" BU_SG_REL_ EBS SG_ 426 RideHeightFunctionStatus_ISig_3 120;
BA_REL_ "GenSigFirstTimeoutTime" BU_SG_REL_ APM SG_ 268 BrakePedalPosition_ISig_3 3000;
BA_REL_ "GenSigTimeoutTime" BU_SG_REL_ APM SG_ 268 BrakePedalPosition_ISig_3 60;
BA_REL_ "GenSigFirstTimeoutTime" BU_SG_REL_ FAS SG_ 268 RoadWheelAngle_Request 3000;
BA_REL_ "GenSigTimeoutTime" BU_SG_REL_ FAS SG_ 268 RoadWheelAngle_Request 100;
BA_REL_ "GenSigFirstTimeoutTime" BU_SG_REL_ APM SG_ 268 AcceleratorPedalQuality_ISig_3 3000;
BA_REL_ "GenSigTimeoutTime" BU_SG_REL_ APM SG_ 268 AcceleratorPedalQuality_ISig_3 60;
BA_REL_ "GenSigFirstTimeoutTime" BU_SG_REL_ FAS SG_ 268 RoadWheelAngle_RateRequest 3000;
BA_REL_ "GenSigTimeoutTime" BU_SG_REL_ FAS SG_ 268 RoadWheelAngle_RateRequest 100;
BA_REL_ "GenSigFirstTimeoutTime" BU_SG_REL_ APM SG_ 268 AcceleratorPedalStatus 3000;
BA_REL_ "GenSigTimeoutTime" BU_SG_REL_ APM SG_ 268 AcceleratorPedalStatus 60;
BA_REL_ "GenSigFirstTimeoutTime" BU_SG_REL_ FAS SG_ 268 SteeringControlMode_CRC 3000;
BA_REL_ "GenSigTimeoutTime" BU_SG_REL_ FAS SG_ 268 SteeringControlMode_CRC 100;
BA_REL_ "GenSigFirstTimeoutTime" BU_SG_REL_ FAS SG_ 268 SteeringControlMode_Activate 3000;
BA_REL_ "GenSigTimeoutTime" BU_SG_REL_ FAS SG_ 268 SteeringControlMode_Activate 100;
BA_REL_ "GenSigFirstTimeoutTime" BU_SG_REL_ FAS SG_ 268 RoadWheelAngle_CRC 3000;
BA_REL_ "GenSigTimeoutTime" BU_SG_REL_ FAS SG_ 268 RoadWheelAngle_CRC 100;
BA_REL_ "GenSigFirstTimeoutTime" BU_SG_REL_ APM SG_ 268 AcceleratorPedalPosition1_ISig_3 3000;
BA_REL_ "GenSigTimeoutTime" BU_SG_REL_ APM SG_ 268 AcceleratorPedalPosition1_ISig_3 60;
BA_REL_ "GenSigFirstTimeoutTime" BU_SG_REL_ FAS SG_ 268 RoadWheelAngle_SqC 3000;
BA_REL_ "GenSigTimeoutTime" BU_SG_REL_ FAS SG_ 268 RoadWheelAngle_SqC 100;
BA_REL_ "GenSigFirstTimeoutTime" BU_SG_REL_ APM SG_ 268 AcceleratorPedalLowIdleSwitch_IS 3000;
BA_REL_ "GenSigTimeoutTime" BU_SG_REL_ APM SG_ 268 AcceleratorPedalLowIdleSwitch_IS 60;
BA_REL_ "GenSigFirstTimeoutTime" BU_SG_REL_ FAS SG_ 268 SteeringControlMode_SqC 3000;
BA_REL_ "GenSigTimeoutTime" BU_SG_REL_ FAS SG_ 268 SteeringControlMode_SqC 100;
BA_REL_ "GenSigFirstTimeoutTime" BU_SG_REL_ FAS SG_ 268 SteeringControlMode_Request 3000;
BA_REL_ "GenSigTimeoutTime" BU_SG_REL_ FAS SG_ 268 SteeringControlMode_Request 100;
VAL_ 266 ZxbrReqVeh_RetModReq 7 "RetModReq_NotAvailable" 6 "RetModReq_Error" 5 "RetModReq_Spare3" 4 "RetModReq_Spare2" 3 "RetModReq_Spare1" 2 "RetModReq_Maximum" 1 "RetModReq_Addition" 0 "RetModReq_Inactive" ;
VAL_ 266 ZxbrReqVeh_RetEbiModReq 7 "EbiMode3bit_NotAvailable" 6 "EbiMode3bit_Error" 5 "EbiMode3bit_Spare2" 4 "EbiMode3bit_Spare1" 3 "EbiMode3bit_Spare0" 2 "EbiMode3bit_EnduranceBrakeIntegrationAllowed" 1 "EbiMode3bit_OnlyEnduranceBrakesAllowed" 0 "EbiMode3bit_NoEnduranceBrakeIntegrationAllowed" ;
VAL_ 266 ZxbrReqVeh_EbsCtrlModReq 3 "InactiveActive_NotAvailable" 2 "InactiveActive_Error" 1 "InactiveActive_Active" 0 "InactiveActive_Inactive" ;
VAL_ 266 ZxbrReqVeh_DrvrModReq 3 "DrvrModReq_NotAvailable" 2 "DrvrModReq_Error" 1 "DrvrModReq_AutonomousControl" 0 "DrvrModReq_ManualControl" ;
VAL_ 262 IxbrReqAxle4_SlipCtrlEna 3 "DisableEnable_NotAvailable" 2 "DisableEnable_Error" 1 "DisableEnable_Enable" 0 "DisableEnable_Disable" ;
VAL_ 262 IxbrReqAxle5_SlipCtrlEna 3 "DisableEnable_NotAvailable" 2 "DisableEnable_Error" 1 "DisableEnable_Enable" 0 "DisableEnable_Disable" ;
VAL_ 262 IxbrReqAxle5_VehSpdLgtWhlQltyLe 3 "SignalQlty_NotAvailable" 2 "SignalQlty_Error" 1 "SignalQlty_Degraded" 0 "SignalQlty_Operational" ;
VAL_ 262 IxbrReqAxle6_VehSpdLgtWhlQltyRi 3 "SignalQlty_NotAvailable" 2 "SignalQlty_Error" 1 "SignalQlty_Degraded" 0 "SignalQlty_Operational" ;
VAL_ 262 IxbrReqAxle4_VehSpdLgtWhlQltyRi 3 "SignalQlty_NotAvailable" 2 "SignalQlty_Error" 1 "SignalQlty_Degraded" 0 "SignalQlty_Operational" ;
VAL_ 262 IxbrReqAxle4_IxbrModReq 7 "IxbrModReq_NotAvailable" 6 "IxbrModReq_Error" 5 "IxbrModReq_Spare5" 4 "IxbrModReq_Spare4" 3 "IxbrModReq_Spare3" 2 "IxbrModReq_Spare2" 1 "IxbrModReq_Spare1" 0 "IxbrModReq_Spare0" ;
VAL_ 262 IxbrReqAxle6_SlipCtrlEna 3 "DisableEnable_NotAvailable" 2 "DisableEnable_Error" 1 "DisableEnable_Enable" 0 "DisableEnable_Disable" ;
VAL_ 262 IxbrReqAxle4_VehSpdLgtWhlQltyLe 3 "SignalQlty_NotAvailable" 2 "SignalQlty_Error" 1 "SignalQlty_Degraded" 0 "SignalQlty_Operational" ;
VAL_ 262 IxbrReqAxle6_VehSpdLgtWhlQltyLe 3 "SignalQlty_NotAvailable" 2 "SignalQlty_Error" 1 "SignalQlty_Degraded" 0 "SignalQlty_Operational" ;
VAL_ 262 IxbrReqAxle5_VehSpdLgtWhlQltyRi 3 "SignalQlty_NotAvailable" 2 "SignalQlty_Error" 1 "SignalQlty_Degraded" 0 "SignalQlty_Operational" ;
VAL_ 262 IxbrReqAxle5_IxbrModReq 7 "IxbrModReq_NotAvailable" 6 "IxbrModReq_Error" 5 "IxbrModReq_Spare5" 4 "IxbrModReq_Spare4" 3 "IxbrModReq_Spare3" 2 "IxbrModReq_Spare2" 1 "IxbrModReq_Spare1" 0 "IxbrModReq_Spare0" ;
VAL_ 262 IxbrReqAxle6_IxbrModReq 7 "IxbrModReq_NotAvailable" 6 "IxbrModReq_Error" 5 "IxbrModReq_Spare5" 4 "IxbrModReq_Spare4" 3 "IxbrModReq_Spare3" 2 "IxbrModReq_Spare2" 1 "IxbrModReq_Spare1" 0 "IxbrModReq_Spare0" ;
VAL_ 261 IxbrReqAxle1_VehSpdLgtWhlQltyRi 3 "SignalQlty_NotAvailable" 2 "SignalQlty_Error" 1 "SignalQlty_Degraded" 0 "SignalQlty_Operational" ;
VAL_ 261 IxbrReqAxle1_SlipCtrlEna 3 "DisableEnable_NotAvailable" 2 "DisableEnable_Error" 1 "DisableEnable_Enable" 0 "DisableEnable_Disable" ;
VAL_ 261 IxbrReqAxle2_SlipCtrlEna 3 "DisableEnable_NotAvailable" 2 "DisableEnable_Error" 1 "DisableEnable_Enable" 0 "DisableEnable_Disable" ;
VAL_ 261 IxbrReqAxle1_IxbrModReq 7 "IxbrModReq_NotAvailable" 6 "IxbrModReq_Error" 5 "IxbrModReq_Spare5" 4 "IxbrModReq_Spare4" 3 "IxbrModReq_Spare3" 2 "IxbrModReq_Spare2" 1 "IxbrModReq_Spare1" 0 "IxbrModReq_Spare0" ;
VAL_ 261 IxbrReqAxle3_VehSpdLgtWhlQltyLe 3 "SignalQlty_NotAvailable" 2 "SignalQlty_Error" 1 "SignalQlty_Degraded" 0 "SignalQlty_Operational" ;
VAL_ 261 IxbrReqAxle2_IxbrModReq 7 "IxbrModReq_NotAvailable" 6 "IxbrModReq_Error" 5 "IxbrModReq_Spare5" 4 "IxbrModReq_Spare4" 3 "IxbrModReq_Spare3" 2 "IxbrModReq_Spare2" 1 "IxbrModReq_Spare1" 0 "IxbrModReq_Spare0" ;
VAL_ 261 IxbrReqAxle3_VehSpdLgtWhlQltyRi 3 "SignalQlty_NotAvailable" 2 "SignalQlty_Error" 1 "SignalQlty_Degraded" 0 "SignalQlty_Operational" ;
VAL_ 261 IxbrReqAxle1_VehSpdLgtWhlQltyLe 3 "SignalQlty_NotAvailable" 2 "SignalQlty_Error" 1 "SignalQlty_Degraded" 0 "SignalQlty_Operational" ;
VAL_ 261 IxbrReqAxle3_IxbrModReq 7 "IxbrModReq_NotAvailable" 6 "IxbrModReq_Error" 5 "IxbrModReq_Spare5" 4 "IxbrModReq_Spare4" 3 "IxbrModReq_Spare3" 2 "IxbrModReq_Spare2" 1 "IxbrModReq_Spare1" 0 "IxbrModReq_Spare0" ;
VAL_ 261 IxbrReqAxle2_VehSpdLgtWhlQltyLe 3 "SignalQlty_NotAvailable" 2 "SignalQlty_Error" 1 "SignalQlty_Degraded" 0 "SignalQlty_Operational" ;
VAL_ 261 IxbrReqAxle3_SlipCtrlEna 3 "DisableEnable_NotAvailable" 2 "DisableEnable_Error" 1 "DisableEnable_Enable" 0 "DisableEnable_Disable" ;
VAL_ 261 IxbrReqAxle2_VehSpdLgtWhlQltyRi 3 "SignalQlty_NotAvailable" 2 "SignalQlty_Error" 1 "SignalQlty_Degraded" 0 "SignalQlty_Operational" ;
VAL_ 554 EstAxle6_WhlRdEstQltyRi 3 "SignalQlty_NotAvailable" 2 "SignalQlty_Error" 1 "SignalQlty_Degraded" 0 "SignalQlty_Operational" ;
VAL_ 554 EstAxle5_WhlRdEstQltyRi 3 "SignalQlty_NotAvailable" 2 "SignalQlty_Error" 1 "SignalQlty_Degraded" 0 "SignalQlty_Operational" ;
VAL_ 554 EstAxle2_LoadNormQltyLe 3 "SignalQlty_NotAvailable" 2 "SignalQlty_Error" 1 "SignalQlty_Degraded" 0 "SignalQlty_Operational" ;
VAL_ 554 EstAxle3_LoadNormQltyRi 3 "SignalQlty_NotAvailable" 2 "SignalQlty_Error" 1 "SignalQlty_Degraded" 0 "SignalQlty_Operational" ;
VAL_ 554 EstAxle4_LoadNormQltyRi 3 "SignalQlty_NotAvailable" 2 "SignalQlty_Error" 1 "SignalQlty_Degraded" 0 "SignalQlty_Operational" ;
VAL_ 554 EstAxle5_LoadNormQltyRi 3 "SignalQlty_NotAvailable" 2 "SignalQlty_Error" 1 "SignalQlty_Degraded" 0 "SignalQlty_Operational" ;
VAL_ 554 EstAxle6_WhlRdEstQltyLe 3 "SignalQlty_NotAvailable" 2 "SignalQlty_Error" 1 "SignalQlty_Degraded" 0 "SignalQlty_Operational" ;
VAL_ 554 EstAxle5_LoadNormQltyLe 3 "SignalQlty_NotAvailable" 2 "SignalQlty_Error" 1 "SignalQlty_Degraded" 0 "SignalQlty_Operational" ;
VAL_ 554 EstAxle3_WhlRdEstQltyLe 3 "SignalQlty_NotAvailable" 2 "SignalQlty_Error" 1 "SignalQlty_Degraded" 0 "SignalQlty_Operational" ;
VAL_ 554 EstAxle4_WhlRdEstQltyRi 3 "SignalQlty_NotAvailable" 2 "SignalQlty_Error" 1 "SignalQlty_Degraded" 0 "SignalQlty_Operational" ;
VAL_ 554 EstAxle6_LoadNormQltyRi 3 "SignalQlty_NotAvailable" 2 "SignalQlty_Error" 1 "SignalQlty_Degraded" 0 "SignalQlty_Operational" ;
VAL_ 554 EstAxle1_LoadNormQltyRi 3 "SignalQlty_NotAvailable" 2 "SignalQlty_Error" 1 "SignalQlty_Degraded" 0 "SignalQlty_Operational" ;
VAL_ 554 EstAxle1_LoadNormQltyLe 3 "SignalQlty_NotAvailable" 2 "SignalQlty_Error" 1 "SignalQlty_Degraded" 0 "SignalQlty_Operational" ;
VAL_ 554 EstAxle4_WhlRdEstQltyLe 3 "SignalQlty_NotAvailable" 2 "SignalQlty_Error" 1 "SignalQlty_Degraded" 0 "SignalQlty_Operational" ;
VAL_ 554 EstAxle1_WhlRdEstQltyLe 3 "SignalQlty_NotAvailable" 2 "SignalQlty_Error" 1 "SignalQlty_Degraded" 0 "SignalQlty_Operational" ;
VAL_ 554 EstAxle2_LoadNormQltyRi 3 "SignalQlty_NotAvailable" 2 "SignalQlty_Error" 1 "SignalQlty_Degraded" 0 "SignalQlty_Operational" ;
VAL_ 554 EstAxle3_LoadNormQltyLe 3 "SignalQlty_NotAvailable" 2 "SignalQlty_Error" 1 "SignalQlty_Degraded" 0 "SignalQlty_Operational" ;
VAL_ 554 EstAxle4_LoadNormQltyLe 3 "SignalQlty_NotAvailable" 2 "SignalQlty_Error" 1 "SignalQlty_Degraded" 0 "SignalQlty_Operational" ;
VAL_ 554 EstAxle2_WhlRdEstQltyRi 3 "SignalQlty_NotAvailable" 2 "SignalQlty_Error" 1 "SignalQlty_Degraded" 0 "SignalQlty_Operational" ;
VAL_ 554 EstAxle6_LoadNormQltyLe 3 "SignalQlty_NotAvailable" 2 "SignalQlty_Error" 1 "SignalQlty_Degraded" 0 "SignalQlty_Operational" ;
VAL_ 554 EstAxle3_WhlRdEstQltyRi 3 "SignalQlty_NotAvailable" 2 "SignalQlty_Error" 1 "SignalQlty_Degraded" 0 "SignalQlty_Operational" ;
VAL_ 554 EstAxle2_WhlRdEstQltyLe 3 "SignalQlty_NotAvailable" 2 "SignalQlty_Error" 1 "SignalQlty_Degraded" 0 "SignalQlty_Operational" ;
VAL_ 554 EstAxle5_WhlRdEstQltyLe 3 "SignalQlty_NotAvailable" 2 "SignalQlty_Error" 1 "SignalQlty_Degraded" 0 "SignalQlty_Operational" ;
VAL_ 554 EstAxle1_WhlRdEstQltyRi 3 "SignalQlty_NotAvailable" 2 "SignalQlty_Error" 1 "SignalQlty_Degraded" 0 "SignalQlty_Operational" ;
VAL_ 631 TrsmEngdForPropulsion_Status 7 "NotReady3bit_NotAvailable" 6 "NotReady3bit_Error" 5 "NotReady3bit_Spare4" 4 "NotReady3bit_Spare3" 3 "NotReady3bit_Spare2" 2 "NotReady3bit_Spare1" 1 "NotReady3bit_Ready" 0 "NotReady3bit_NotReady" ;
VAL_ 631 XPRGReqMain_AddVlvRelIhnibition 1 "InactiveActive1b_Active" 0 "InactiveActive1b_Inactive" ;
VAL_ 631 XPRGReqMain_PBValveCtrl 7 "PBValveCtrl_NotAvailable" 6 "PBValveCtrl_Error" 5 "PBValveCtrl_Spare2" 4 "PBValveCtrl_PreRelease" 3 "PBValveCtrl_Proportional" 2 "PBValveCtrl_Release" 1 "PBValveCtrl_Apply" 0 "PBValveCtrl_NoRequest" ;
VAL_ 631 DriverLocation_Status_ISig_3 15 "DriverPresenceStatus_NotAvailable" 14 "DriverPresenceStatus_Error" 13 "DriverPresenceStatus_Spare8" 12 "DriverPresenceStatus_Spare7" 11 "DriverPresenceStatus_Spare6" 10 "DriverPresenceStatus_Spare5" 9 "DriverPresenceStatus_Spare4" 8 "DriverPresenceStatus_Spare3" 7 "DriverPresenceStatus_Spare2" 6 "DriverPresenceStatus_Spare1" 5 "DriverPresenceStatus_AutonomousDriver" 4 "DriverPresenceStatus_DriverAtDriverSeat" 3 "DriverPresenceStatus_DriverOutOfCab" 2 "DriverPresenceStatus_RemoteDriver" 1 "DriverPresenceStatus_DriverInCab" 0 "DriverPresenceStatus_NotKnown" ;
VAL_ 631 XPRGReqMain_AddValveCtrlMode 1 "AddValveCtrlMode_TrailerSupplyCtrlActive" 0 "AddValveCtrlMode_TrailerSupplyCtrlInactive" ;
VAL_ 631 XPRGReqMain_AddValveCtrl 7 "AddValveCtrl_NotAvailable" 6 "AddValveCtrl_Error" 5 "AddValveCtrl_Spare2" 4 "AddValveCtrl_Spare1" 3 "AddValveCtrl_Proportional" 2 "AddValveCtrl_Inflate" 1 "AddValveCtrl_Deflate" 0 "AddValveCtrl_NoRequest" ;
VAL_ 631 BacklightCmd_ISig_3 31 "BacklightCmd_NotAvailable" 30 "BacklightCmd_Error" 16 "BacklightCmd_BacklightLevel16" 15 "BacklightCmd_BacklightLevel15" 14 "BacklightCmd_BacklightLevel14" 13 "BacklightCmd_BacklightLevel13" 12 "BacklightCmd_BacklightLevel12" 11 "BacklightCmd_BacklightLevel11" 10 "BacklightCmd_BacklightLevel10" 9 "BacklightCmd_BacklightLevel9" 8 "BacklightCmd_BacklightLevel8" 7 "BacklightCmd_BacklightLevel7" 6 "BacklightCmd_BacklightLevel6" 5 "BacklightCmd_BacklightLevel5" 4 "BacklightCmd_BacklightLevel4" 3 "BacklightCmd_BacklightLevel3" 2 "BacklightCmd_BacklightLevel2" 1 "BacklightCmd_BacklightLevel1" 0 "BacklightCmd_BacklightOff" ;
VAL_ 631 DoorsAjar_stat_ISig_3 7 "DoorsAjar_stat_NotAvailable" 6 "DoorsAjar_stat_Error" 5 "DoorsAjar_stat_Spare" 4 "DoorsAjar_stat_BothDoorsAreOpen" 3 "DoorsAjar_stat_PassengerDoorIsOpen" 2 "DoorsAjar_stat_DriverDoorIsOpen" 1 "DoorsAjar_stat_BothDoorsAreClosed" 0 "DoorsAjar_stat_Idle" ;
VAL_ 631 XPRGReqPropDemTc_TypeControl 3 "XPRGTypeControl_NotAvailable" 2 "XPRGTypeControl_Error" 1 "XPRGTypeControl_PercentSimilarToPositionHCU" 0 "XPRGTypeControl_PressureIn80mbarSteps" ;
VAL_ 631 CartridgeChangedDrvrReset_rqst_I 3 "DisableEnable_NotAvailable" 2 "DisableEnable_Error" 1 "DisableEnable_Enable" 0 "DisableEnable_Disable" ;
VAL_ 631 DriverLocation_ConfidenceLvl_ISi 3 "LowHigh_NotAvailable" 2 "LowHigh_Error" 1 "LowHigh_High" 0 "LowHigh_Low" ;
VAL_ 631 XPRGReqPropDemTl_TypeControl 3 "XPRGTypeControl_NotAvailable" 2 "XPRGTypeControl_Error" 1 "XPRGTypeControl_PercentSimilarToPositionHCU" 0 "XPRGTypeControl_PressureIn80mbarSteps" ;
VAL_ 631 XPRGReqMain_RequestPriority 3 "XPRGPriority2bit_HighPriority" 2 "XPRGPriority2bit_MediumPriority" 1 "XPRGPriority2bit_NormalPriority" 0 "XPRGPriority2bit_NoPriority" ;
VAL_ 631 FuncIndIlluminationLevel_ISig_3 7 "FuncIndIlluminationLevel_NotAvailable" 6 "FuncIndIlluminationLevel_Error" 5 "FuncIndIlluminationLevel_Spare" 4 "FuncIndIlluminationLevel_IlluminationLevel4" 3 "FuncIndIlluminationLevel_IlluminationLevel3" 2 "FuncIndIlluminationLevel_IlluminationLevel2" 1 "FuncIndIlluminationLevel_IlluminationLevel1" 0 "FuncIndIlluminationLevel_IlluminationOff" ;
VAL_ 631 TrailerABSStatus_ISig_3 3 "TrailerABSStatus_NotAvailable" 2 "TrailerABSStatus_ErrorIndicator" 1 "TrailerABSStatus_OK" 0 "TrailerABSStatus_Error" ;
VAL_ 631 XPRGReqMain_PBVlvRelInhibition 1 "InactiveActive1b_Active" 0 "InactiveActive1b_Inactive" ;
VAL_ 1447 AirDryerCartdgeTypeReset 15 "AirDryerCartdgeType_NotAvailable" 14 "AirDryerCartdgeType_Spare8" 13 "AirDryerCartdgeType_Spare7" 12 "AirDryerCartdgeType_Spare6" 11 "AirDryerCartdgeType_Spare5" 10 "AirDryerCartdgeType_Spare4" 9 "AirDryerCartdgeType_Spare3" 8 "AirDryerCartdgeType_Spare2" 7 "AirDryerCartdgeType_Spare1" 6 "AirDryerCartdgeType_Others" 5 "AirDryerCartdgeType_Bendix_AD_IP" 4 "AirDryerCartdgeType_Bendix_AD_9" 3 "AirDryerCartdgeType_Wabco_1800" 2 "AirDryerCartdgeType_Wabco_1200" 1 "AirDryerCartdgeType_VolvoOrMack_Prop" 0 "AirDryerCartdgeType_NoSelectionMade" ;
VAL_ 1447 DriverMemory_rqst_ISig_3 31 "DriverMemory_rqst_Error" 30 "DriverMemory_rqst_NotAvailable" 29 "DriverMemory_rqst_Spare_07" 28 "DriverMemory_rqst_Spare_06" 27 "DriverMemory_rqst_Spare_05" 26 "DriverMemory_rqst_Spare_04" 25 "DriverMemory_rqst_Spare_03" 24 "DriverMemory_rqst_Spare_02" 23 "DriverMemory_rqst_Spare_01" 22 "DriverMemory_rqst_Spare" 21 "DriverMemory_rqst_ResetAllMemThenUseDefDriverMem" 20 "DriverMemory_rqst_ResetAndThenUseDriverMemory10" 19 "DriverMemory_rqst_ResetAndThenUseDriverMemory9" 18 "DriverMemory_rqst_ResetAndThenUseDriverMemory8" 17 "DriverMemory_rqst_ResetAndThenUseDriverMemory7" 16 "DriverMemory_rqst_ResetAndThenUseDriverMemory6" 15 "DriverMemory_rqst_ResetAndThenUseDriverMemory5" 14 "DriverMemory_rqst_ResetAndThenUseDriverMemory4" 13 "DriverMemory_rqst_ResetAndThenUseDriverMemory3" 12 "DriverMemory_rqst_ResetAndThenUseDriverMemory2" 11 "DriverMemory_rqst_ResetAndThenUseDriverMemory1" 10 "DriverMemory_rqst_UseDriverMemory10" 9 "DriverMemory_rqst_UseDriverMemory9" 8 "DriverMemory_rqst_UseDriverMemory8" 7 "DriverMemory_rqst_UseDriverMemory7" 6 "DriverMemory_rqst_UseDriverMemory6" 5 "DriverMemory_rqst_UseDriverMemory5" 4 "DriverMemory_rqst_UseDriverMemory4" 3 "DriverMemory_rqst_UseDriverMemory3" 2 "DriverMemory_rqst_UseDriverMemory2" 1 "DriverMemory_rqst_UseDriverMemory1" 0 "DriverMemory_rqst_UseDefaultDriverMemory" ;
VAL_ 1447 FasDriver_rqst_ISig_3 15 "FasDriver_NotAvailable" 14 "FasDriver_Error" 13 "FasDriver_Spare3" 12 "FasDriver_Spare2" 11 "FasDriver_Spare1" 10 "FasDriver_Driver10" 9 "FasDriver_Driver9" 8 "FasDriver_Driver8" 7 "FasDriver_Driver7" 6 "FasDriver_Driver6" 5 "FasDriver_Driver5" 4 "FasDriver_Driver4" 3 "FasDriver_Driver3" 2 "FasDriver_Driver2" 1 "FasDriver_Driver1" 0 "FasDriver_DefaultDriver" ;
VAL_ 1447 FasPersonalSettingsButton_rqst_I 7 "FasPersSettingsButton_NotAvailable" 6 "FasPersSettingsButton_Error" 5 "FasPersSettingsButton_Spare" 4 "FasPersSettingsButton_UserDefinedButton" 3 "FasPersSettingsButton_PresetButtonHeavy" 2 "FasPersSettingsButton_PresetButtonFirm" 1 "FasPersSettingsButton_PresetButtonLight" 0 "FasPersSettingsButton_PresetButtonDefault" ;
VAL_ 1447 FasUsrDefinedStorage_rqst_ISig_3 3 "FasUsrDefinedStorage_NotAvailable" 2 "FasUsrDefinedStorage_Error" 1 "FasUsrDefinedStorage_StoreUserDefinedSetting" 0 "FasUsrDefinedStorage_DoNotStoreUserDefinedSetting" ;
VAL_ 1034 AirConsumptionStatus 3 "InactiveActive_NotAvailable" 2 "InactiveActive_Error" 1 "InactiveActive_Active" 0 "InactiveActive_Inactive" ;
VAL_ 1034 UnloadValveOperationRqst 3 "UnloadValveOperationRqst_NotAvailable" 2 "UnloadValveOperationRqst_Error" 1 "UnloadValveOperationRqst_KeepCloseRequest" 0 "UnloadValveOperationRqst_NoRequest" ;
VAL_ 1034 AirProductionPressureRangeMode 15 "AirProdPressureRangeMode_NotAvailable" 14 "AirProdPressureRangeMode_Error" 13 "AirProdPressureRangeMode_Mode13" 12 "AirProdPressureRangeMode_Mode12" 11 "AirProdPressureRangeMode_CompressorPipeExhaust" 10 "AirProdPressureRangeMode_EngineStartHelp" 9 "AirProdPressureRangeMode_SoftPressureMode" 8 "AirProdPressureRangeMode_BrakePressureLimitation" 7 "AirProdPressureRangeMode_Mode7" 6 "AirProdPressureRangeMode_Mode6" 5 "AirProdPressureRangeMode_Mode5" 4 "AirProdPressureRangeMode_LowSpeedMode" 3 "AirProdPressureRangeMode_OvertakeMode" 2 "AirProdPressureRangeMode_OverunMode" 1 "AirProdPressureRangeMode_DefaultMode" 0 "AirProdPressureRangeMode_NoCompressorControl" ;
VAL_ 1034 BrakeSwitch_ISig_3 3 "BrakeSwitch_NotAvailable" 2 "BrakeSwitch_Error" 1 "BrakeSwitch_BrakePedalDepressed" 0 "BrakeSwitch_BrakePedalReleased" ;
VAL_ 1034 ElAirCompOperationStat 7 "ElAirCompOperationStat_NotAvailable" 6 "ElAirCompOperationStat_Error" 5 "ElAirCompOperationStat_NotOperational" 4 "ElAirCompOperationStat_PermanentelyStopped" 3 "ElAirCompOperationStat_TemporaryStopped" 2 "ElAirCompOperationStat_DowgradedMode" 1 "ElAirCompOperationStat_Running" 0 "ElAirCompOperationStat_Standby" ;
VAL_ 1034 TrailerConnected_ISig_3 3 "NoYes_NotAvailable" 2 "NoYes_Error" 1 "NoYes_Yes" 0 "NoYes_No" ;
VAL_ 1034 ContTrailerBrake_Request 7 "ContTrailerBrake_rqst_NotAvailable" 6 "ContTrailerBrake_rqst_Error" 5 "ContTrailerBrake_rqst_Spare_01" 4 "ContTrailerBrake_rqst_Spare" 3 "ContTrailerBrake_rqst_Decrease" 2 "ContTrailerBrake_rqst_Increase" 1 "ContTrailerBrake_rqst_Activate" 0 "ContTrailerBrake_rqst_Deactivate" ;
VAL_ 426 ChangeKneelACK_ISig_3 3 "ChangeKneelACK_NotAvailable" 2 "ChangeKneelACK_Error" 1 "ChangeKneelACK_ChangeAcknowledged" 0 "ChangeKneelACK_NoAction" ;
VAL_ 426 SecuredNeutralPosition_ISig_3 3 "SecuredNeutralPosition_NotAvailable" 2 "SecuredNeutralPosition_Error" 1 "SecuredNeutralPosition_SecuredNeutralPosition" 0 "SecuredNeutralPosition_NotInSecuredNeutralPosition" ;
VAL_ 426 LiftAxle1PositionStatus_ISig_3 7 "LiftAxlePositionStatus_NotAvailable" 6 "LiftAxlePositionStatus_Error" 5 "LiftAxlePositionStatus_Reserved_01" 4 "LiftAxlePositionStatus_Reserved" 3 "LiftAxlePositionStatus_Lifting" 2 "LiftAxlePositionStatus_Lowering" 1 "LiftAxlePositionStatus_Lifted" 0 "LiftAxlePositionStatus_Lowered" ;
VAL_ 426 FrontFerryFunctionCmd_ISig_3 7 "FerryFunctionCmd_NotAvailable" 6 "FerryFunctionCmd_Error" 5 "FerryFunctionCmd_Spare2" 4 "FerryFunctionCmd_Spare1" 3 "FerryFunctionCmd_Spare0" 2 "FerryFunctionCmd_Drain" 1 "FerryFunctionCmd_CloseValves" 0 "FerryFunctionCmd_Inactive" ;
VAL_ 426 ReverseGearEngaged_ISig_3 3 "ReverseGearEngaged_NotAvailable" 2 "ReverseGearEngaged_Error" 1 "ReverseGearEngaged_ReverseGearEngaged" 0 "ReverseGearEngaged_ReverseGearNotEngaged" ;
VAL_ 426 AirDumpStatus_ISig_3 7 "AirDumpStatus_NotAvailable" 6 "AirDumpStatus_Error" 5 "AirDumpStatus_Spare2" 4 "AirDumpStatus_Spare1" 3 "AirDumpStatus_Denied" 2 "AirDumpStatus_ActiveReached" 1 "AirDumpStatus_ActiveNotReached" 0 "AirDumpStatus_Inactive" ;
VAL_ 426 EngineActiveStatus_ISig_3 15 "EngineActiveStatus_NotAvailable" 14 "EngineActiveStatus_Error" 13 "EngineActiveStatus_Spare_10" 12 "EngineActiveStatus_Spare_09" 11 "EngineActiveStatus_Spare_08" 10 "EngineActiveStatus_Spare_07" 9 "EngineActiveStatus_Spare_06" 8 "EngineActiveStatus_Spare_05" 7 "EngineActiveStatus_Spare_04" 6 "EngineActiveStatus_Spare_03" 5 "EngineActiveStatus_Spare_02" 4 "EngineActiveStatus_Spare_01" 3 "EngineActiveStatus_EngineStandby" 2 "EngineActiveStatus_ElectricPropulsionSystemRunning" 1 "EngineActiveStatus_InternalCombustionEngineRunning" 0 "EngineActiveStatus_DrivelineNotActive" ;
VAL_ 426 FerryFunctionStatus_ISig_3 7 "FerryFunctionStatus_NotAvailable" 6 "FerryFunctionStatus_Error" 5 "FerryFunctionStatus_Spare_03" 4 "FerryFunctionStatus_Spare_02" 3 "FerryFunctionStatus_Spare_01" 2 "FerryFunctionStatus_FerryFunctionActiveLeveNotlReached" 1 "FerryFunctionStatus_FerryFunctionActiveLevelReached" 0 "FerryFunctionStatus_FerryFunctionNotActive" ;
VAL_ 426 KneelingInformation_ISig_3 15 "KneelingInformation_NotAvailable" 14 "KneelingInformation_ErrorIndicator" 13 "KneelingInformation_NotDefined_08" 12 "KneelingInformation_NotDefined_07" 11 "KneelingInformation_NotDefined_06" 10 "KneelingInformation_NotDefined_05" 9 "KneelingInformation_NotDefined_04" 8 "KneelingInformation_NotDefined_03" 7 "KneelingInformation_NotDefined_02" 6 "KneelingInformation_NotDefined_01" 5 "KneelingInformation_NotDefined" 4 "KneelingInformation_KneelingAborted" 3 "KneelingInformation_LiftingActiveVehicleIsLiftedDueToRcvrReq" 2 "KneelingInformation_KneelLevelReachedVehicleIsAtFixeKneelLvl" 1 "KneelingInformation_LoweringActiveTheVehIsLoweredDueToKneelReq" 0 "KneelingInformation_NotActiveTheKneelingFunctionIsNotActive" ;
VAL_ 426 FASHapticFeedbackRequest 15 "FASHapticFeedbackRequest_NotAvailable" 14 "FASHapticFeedbackRequest_Error" 13 "FASHapticFeedbackRequest_Spare3" 12 "FASHapticFeedbackRequest_Spare2" 11 "FASHapticFeedbackRequest_Spare1" 10 "FASHapticFeedbackRequest_PredefinedFreqAndAmpl10" 9 "FASHapticFeedbackRequest_PredefinedFreqAndAmpl9" 8 "FASHapticFeedbackRequest_PredefinedFreqAndAmpl8" 7 "FASHapticFeedbackRequest_PredefinedFreqAndAmpl7" 6 "FASHapticFeedbackRequest_PredefinedFreqAndAmpl6" 5 "FASHapticFeedbackRequest_PredefinedFreqAndAmpl5" 4 "FASHapticFeedbackRequest_PredefinedFreqAndAmpl4" 3 "FASHapticFeedbackRequest_PredefinedFreqAndAmpl3" 2 "FASHapticFeedbackRequest_PredefinedFreqAndAmpl2" 1 "FASHapticFeedbackRequest_PredefinedFreqAndAmpl1" 0 "FASHapticFeedbackRequest_NoHapticFeedback" ;
VAL_ 426 HeightControlMode_ISig_3 15 "HeightControlMode_NotAvailable" 14 "HeightControlMode_ErrorIndicator" 13 "HeightControlMode_DumpFunction" 12 "HeightControlMode_FactorySupportMode" 11 "HeightControlMode_Calibration" 10 "HeightControlMode_Prohibit" 9 "HeightControlMode_FunctionTest" 8 "HeightControlMode_Stop" 7 "HeightControlMode_LimpHome" 6 "HeightControlMode_FerryFunction" 5 "HeightControlMode_KneelingHeight" 4 "HeightControlMode_DriveHeight" 3 "HeightControlMode_DockingRampHeight" 2 "HeightControlMode_HeightAdjustment" 1 "HeightControlMode_StartUpHeight" 0 "HeightControlMode_TakeNoAction" ;
VAL_ 426 LoadDistributionFuncSelected_ISi 15 "LoadDistributionFuncSelected_NotAvaiable" 14 "LoadDistributionFuncSelected_ErrorIndicator" 13 "LoadDistributionFuncSelected_SpareValue_08" 12 "LoadDistributionFuncSelected_SpareValue_07" 11 "LoadDistributionFuncSelected_SpareValue_06" 10 "LoadDistributionFuncSelected_SpareValue_05" 9 "LoadDistributionFuncSelected_SpareValue_04" 8 "LoadDistributionFuncSelected_SpareValue_03" 7 "LoadDistributionFuncSelected_SpareValue_02" 6 "LoadDistributionFuncSelected_MaximumTractionStartingHelp" 5 "LoadDistributionFuncSelected_VariableAxleLoad" 4 "LoadDistributionFuncSelected_NoLoadDistribution" 3 "LoadDistributionFuncSelected_AlternativeLoad" 2 "LoadDistributionFuncSelected_MaximumTractionTractionHelp" 1 "LoadDistributionFuncSelected_OptimisedTraction" 0 "LoadDistributionFuncSelected_NormalLoad" ;
VAL_ 426 RollEndPositionStatus_ISig_3 7 "RollEndPositionStatus_NotAvailable" 6 "RollEndPositionStatus_Error" 5 "RollEndPositionStatus_Reserved_01" 4 "RollEndPositionStatus_Reserved" 3 "RollEndPositionStatus_NoRollingAllowed" 2 "RollEndPositionStatus_CounterClockwiseEndLevelReached" 1 "RollEndPositionStatus_ClockwiseEndLevelReached" 0 "RollEndPositionStatus_NoEndLevelReached" ;
VAL_ 426 XBRSystemState2_Status 3 "XBRAllowedStatus_NotAvailable" 2 "XBRAllowedStatus_No_Accepted" 1 "XBRAllowedStatus_OnlyHighestPriority_Accepted" 0 "XBRAllowedStatus_Any_Accepted" ;
VAL_ 426 RearAxle2DiffLock_stat_ISig_3 3 "OffOn_NotAvailable" 2 "OffOn_Error" 1 "OffOn_On" 0 "OffOn_Off" ;
VAL_ 426 KneelingStatusHMI_ISig_3 3 "KneelingStatusHMI_NotAvailable" 2 "KneelingStatusHMI_Error" 1 "KneelingStatusHMI_Active" 0 "KneelingStatusHMI_Inactive" ;
VAL_ 426 HeightAdjustmentAllowed_ISig_3 3 "FalseTrue_NotAvaiable" 2 "FalseTrue_Error" 1 "FalseTrue_True" 0 "FalseTrue_False" ;
VAL_ 426 RideHeightStatus_ISig_3 15 "RideHeightStatus_NotAvailable" 14 "RideHeightStatus_ErrorIndicator" 13 "RideHeightStatus_NotDefined_03" 12 "RideHeightStatus_NotDefined_02" 11 "RideHeightStatus_NotDefined_01" 10 "RideHeightStatus_NotDefined" 9 "RideHeightStatus_AlternativeDrivePosition2" 8 "RideHeightStatus_AlternativeDrivePosition1" 7 "RideHeightStatus_AlternativeDrivePosition" 6 "RideHeightStatus_HighDrivePosition" 5 "RideHeightStatus_LowDrivePosition" 4 "RideHeightStatus_SpeedDependentDrivePositionHighSpeed" 3 "RideHeightStatus_SpeedDependentDrivePositionLowSpeed" 2 "RideHeightStatus_StandardUserDrivePosition" 1 "RideHeightStatus_StandardFactoryDrivePosition" 0 "RideHeightStatus_Inactive" ;
VAL_ 426 CentralRearDiffLock_stat_ISig_3 3 "DisengageEngage_NotAvailable" 2 "DisengageEngage_Error" 1 "DisengageEngage_Engage" 0 "DisengageEngage_Disengage" ;
VAL_ 426 LiftAxle2PositionStatus_ISig_3 7 "LiftAxlePositionStatus_NotAvailable" 6 "LiftAxlePositionStatus_Error" 5 "LiftAxlePositionStatus_Reserved_01" 4 "LiftAxlePositionStatus_Reserved" 3 "LiftAxlePositionStatus_Lifting" 2 "LiftAxlePositionStatus_Lowering" 1 "LiftAxlePositionStatus_Lifted" 0 "LiftAxlePositionStatus_Lowered" ;
VAL_ 426 RampHeightOutsideTargetRange_ISi 7 "HeightOutsideTargetRange_NotAvailable" 6 "HeightOutsideTargetRange_Error" 5 "HeightOutsideTargetRange_NotDefined_02" 4 "HeightOutsideTargetRange_NotDefined_01" 3 "HeightOutsideTargetRange_NotDefined" 2 "HeightOutsideTargetRange_ToHigh" 1 "HeightOutsideTargetRange_ToLow" 0 "HeightOutsideTargetRange_Inactive" ;
VAL_ 426 DirInd_Rear_Status_ISig_3 7 "DirIndFaultStatus_NotAvailable" 6 "DirIndFaultStatus_Error" 5 "DirIndFaultStatus_SpareValue_01" 4 "DirIndFaultStatus_SpareValue" 3 "DirIndFaultStatus_BothLeftAndRightDirectionIndicatorsFault" 2 "DirIndFaultStatus_RightDirectionIndicatorLampFault" 1 "DirIndFaultStatus_LeftDirectionIndicatorLampFault" 0 "DirIndFaultStatus_NoError" ;
VAL_ 426 PneumaticTrailerBrakeStatus_ISig 3 "BrakeStatus_NotAvailable" 2 "BrakeStatus_Error" 1 "BrakeStatus_Braking" 0 "BrakeStatus_NotBraking" ;
VAL_ 426 GearLeverPosition_ISig_3 15 "GearLeverPosition_NotAvailable" 14 "GearLeverPosition_Error" 13 "GearLeverPosition_SpareValue_06" 12 "GearLeverPosition_SpareValue_05" 11 "GearLeverPosition_SpareValue_04" 10 "GearLeverPosition_SpareValue_03" 9 "GearLeverPosition_SpareValue_02" 8 "GearLeverPosition_SpareValue_01" 7 "GearLeverPosition_SpareValue" 6 "GearLeverPosition_SEG6" 5 "GearLeverPosition_LowGear" 4 "GearLeverPosition_Manual" 3 "GearLeverPosition_Automatic" 2 "GearLeverPosition_Neutral" 1 "GearLeverPosition_Reverse" 0 "GearLeverPosition_GearFoldedAway" ;
VAL_ 426 BackToDriveReqACK_ISig_3 3 "BackToDriveReqACK_NotAvailable" 2 "BackToDriveReqACK_Error" 1 "BackToDriveReqACK_ChangeAcknowledged" 0 "BackToDriveReqACK_TakNoAction" ;
VAL_ 426 ExtraAxleSteeringFunctionStat 7 "RearAxleSteeringFunctionStatus_NotAvailable" 6 "RearAxleSteeringFunctionStatus_Error" 5 "RearAxleSteeringFunctionStatus_SpareValue_01" 4 "RearAxleSteeringFunctionStatus_SpareValue" 3 "RearAxleSteeringFunctionStatus_ActiveFailureMode" 2 "RearAxleSteeringFunctionStatus_PassiveFailureMode" 1 "RearAxleSteeringFunctionStatus_Active" 0 "RearAxleSteeringFunctionStatus_NotActive" ;
VAL_ 426 RearAxle1DiffLock_stat_ISig_3 3 "OffOn_NotAvailable" 2 "OffOn_Error" 1 "OffOn_On" 0 "OffOn_Off" ;
VAL_ 426 LevelControlInformation_ISig_3 15 "LevelControlInformation_NotAvailable" 14 "LevelControlInformation_Error" 13 "LevelControlInformation_Reserved_06" 12 "LevelControlInformation_Reserved_05" 11 "LevelControlInformation_Reserved_04" 10 "LevelControlInformation_Reserved_03" 9 "LevelControlInformation_Reserved_02" 8 "LevelControlInformation_Reserved_01" 7 "LevelControlInformation_Reserved" 6 "LevelControlInformation_LimpHome" 5 "LevelControlInformation_FerryFunction" 4 "LevelControlInformation_KneelingHeight" 3 "LevelControlInformation_DriveHeight" 2 "LevelControlInformation_DockingHeight" 1 "LevelControlInformation_HeightAdjustment" 0 "LevelControlInformation_Prohibit" ;
VAL_ 426 VehicleMode_ISig_3 15 "VehicleMode_NotAvailable" 14 "VehicleMode_Error" 13 "VehicleMode_Spare_7" 12 "VehicleMode_Spare_6" 11 "VehicleMode_Spare_5" 10 "VehicleMode_Spare_4" 9 "VehicleMode_Spare_3" 8 "VehicleMode_Spare_2" 7 "VehicleMode_Spare_1" 6 "VehicleMode_Running" 5 "VehicleMode_Cranking" 4 "VehicleMode_PreRunning" 3 "VehicleMode_Accessory" 2 "VehicleMode_Living" 1 "VehicleMode_Parked" 0 "VehicleMode_Hibernate" ;
VAL_ 426 ACC_SGO_Status_ISig_3 15 "ACC_SGO_Status_NotAvailable" 14 "ACC_SGO_Status_Error" 13 "ACC_SGO_Status_Spare7" 12 "ACC_SGO_Status_Spare6" 11 "ACC_SGO_Status_Spare5" 10 "ACC_SGO_Status_Spare4" 9 "ACC_SGO_Status_Spare3" 8 "ACC_SGO_Status_Spare2" 7 "ACC_SGO_Status_Spare1" 6 "ACC_SGO_Status_ACC_SGO_Active_TakeOffRequest" 5 "ACC_SGO_Status_ACC_SGO_Active_Hold" 4 "ACC_SGO_Status_ACC_SGO_Active_Stationary" 3 "ACC_SGO_Status_ACC_SGO_Stopping" 2 "ACC_SGO_Status_ACC_SGO_Active_Driving" 1 "ACC_SGO_Status_ACC_SGO_Inactive" 0 "ACC_SGO_Status_ACC_SGO_OFF" ;
VAL_ 426 RearEndPositionStatus_ISig_3 7 "EndPositionStatus_NotAvailable" 6 "EndPositionStatus_Error" 5 "EndPositionStatus_Reserved_01" 4 "EndPositionStatus_Reserved" 3 "EndPositionStatus_LiftingAndLoweringNotAllowed" 2 "EndPositionStatus_MinEndLevelReached" 1 "EndPositionStatus_MaxEndLevelReached" 0 "EndPositionStatus_NoEndLevelReached" ;
VAL_ 426 PBAlertActiveStatus_ISig_3 7 "PBAlertActiveStatus_NotAvailable" 6 "PBAlertActiveStatus_Error" 5 "PBAlertActiveStatus_Spare3" 4 "PBAlertActiveStatus_Spare2" 3 "PBAlertActiveStatus_Spare1" 2 "PBAlertActiveStatus_ShortAlertActive" 1 "PBAlertActiveStatus_LongAlertActive" 0 "PBAlertActiveStatus_Inactive" ;
VAL_ 426 ECSShutdownCmd_ISig_3 3 "FalseTrue_NotAvaiable" 2 "FalseTrue_Error" 1 "FalseTrue_True" 0 "FalseTrue_False" ;
VAL_ 426 VehicleDynamicSuspProhibitStat_I 3 "InactiveActive_NotAvailable" 2 "InactiveActive_Error" 1 "InactiveActive_Active" 0 "InactiveActive_Inactive" ;
VAL_ 426 RideHeightFunctionStatus_ISig_3 15 "RideHeightFunction_NotAvailable" 14 "RideHeightFunction_ErrorIndicator" 13 "RideHeightFunction_NotDefined_05" 12 "RideHeightFunction_NotDefined_04" 11 "RideHeightFunction_NotDefined_03" 10 "RideHeightFunction_NotDefined_02" 9 "RideHeightFunction_NotDefined_01" 8 "RideHeightFunction_NotDefined" 7 "RideHeightFunction_AlternativeDrivePosition2" 6 "RideHeightFunction_AlternativeDrivePosition1" 5 "RideHeightFunction_LowDrivePosition" 4 "RideHeightFunction_HighDrivePosition" 3 "RideHeightFunction_SpeedDependentDrivePosition" 2 "RideHeightFunction_AlternativeDrivePosition" 1 "RideHeightFunction_StandardDrivePosition" 0 "RideHeightFunction_Inactive" ;
VAL_ 268 AcceleratorPedalQuality_ISig_3 3 "PrimaryAcceleratorPedalQuality_NotAvailable" 2 "PrimaryAcceleratorPedalQuality_ErrorMode" 1 "PrimaryAcceleratorPedalQuality_DowngradedMode" 0 "PrimaryAcceleratorPedalQuality_NormalMode" ;
VAL_ 268 AcceleratorPedalStatus 7 "AcceleratorPedalStatus_NotAvailable" 6 "AcceleratorPedalStatus_Error" 5 "AcceleratorPedalStatus_Spare3" 4 "AcceleratorPedalStatus_Spare2" 3 "AcceleratorPedalStatus_Spare1" 2 "AcceleratorPedalStatus_PrimAndSecPedalInhibited" 1 "AcceleratorPedalStatus_SecPedActPrimPedNotAct" 0 "AcceleratorPedalStatus_SecPedNotActPrimPedAct" ;
VAL_ 268 SteeringControlMode_Activate 3 "Request_NotAvailable" 2 "Request_Error" 1 "Request_RequestActive" 0 "Request_NotRequested" ;
VAL_ 268 AcceleratorPedalLowIdleSwitch_IS 3 "AcceleratorPedalLowIdleSwitch_NotAvailable" 2 "AcceleratorPedalLowIdleSwitch_Error" 1 "AcceleratorPedalLowIdleSwitch_INLowIdleCondition" 0 "AcceleratorPedalLowIdleSwitch_NotInLowIdleCondition" ;
VAL_ 268 SteeringControlMode_Request 3 "StrngCtrlModeReq_NotAvailable" 2 "StrngCtrlModeReq_Error" 1 "StrngCtrlModeReq_Autonomous" 0 "StrngCtrlModeReq_Manual" ;
SIG_GROUP_ 266 ZxbrReqVeh_sg 1 : ZxbrReqVeh_RetReq ZxbrReqVeh_RetModReq ZxbrReqVeh_RetEbiModReq ZxbrReqVeh_EbsCtrlModReq ZxbrReqVeh_CRC ZxbrReqVeh_DrvrModReq ZxbrReqVeh_YawRateRefVds ZxbrReqVeh_SqC;
SIG_GROUP_ 262 IxbrReqAxle5_sg 1 : IxbrReqAxle5_SqC IxbrReqAxle5_VehSpdLgtWhlRi IxbrReqAxle5_BrkTqReqRi IxbrReqAxle5_SlipCtrlEna IxbrReqAxle5_WhlSlipLimLoRi IxbrReqAxle5_VehSpdLgtWhlLe IxbrReqAxle5_VehSpdLgtWhlQltyLe IxbrReqAxle5_CRC IxbrReqAxle5_BrkTqReqLe IxbrReqAxle5_VehSpdLgtWhlQltyRi IxbrReqAxle5_WhlSlipLimHiRi IxbrReqAxle5_WhlSlipLimLoLe IxbrReqAxle5_IxbrModReq IxbrReqAxle5_WhlSlipLimHiLe;
SIG_GROUP_ 262 IxbrReqAxle6_sg 1 : IxbrReqAxle6_WhlSlipLimLoLe IxbrReqAxle6_WhlSlipLimHiRi IxbrReqAxle6_SqC IxbrReqAxle6_WhlSlipLimLoRi IxbrReqAxle6_VehSpdLgtWhlRi IxbrReqAxle6_CRC IxbrReqAxle6_VehSpdLgtWhlQltyRi IxbrReqAxle6_BrkTqReqLe IxbrReqAxle6_BrkTqReqRi IxbrReqAxle6_SlipCtrlEna IxbrReqAxle6_VehSpdLgtWhlQltyLe IxbrReqAxle6_IxbrModReq IxbrReqAxle6_WhlSlipLimHiLe IxbrReqAxle6_VehSpdLgtWhlLe;
SIG_GROUP_ 262 IxbrReqAxle4_sg 1 : IxbrReqAxle4_SlipCtrlEna IxbrReqAxle4_BrkTqReqLe IxbrReqAxle4_CRC IxbrReqAxle4_BrkTqReqRi IxbrReqAxle4_SqC IxbrReqAxle4_VehSpdLgtWhlRi IxbrReqAxle4_WhlSlipLimHiLe IxbrReqAxle4_VehSpdLgtWhlLe IxbrReqAxle4_WhlSlipLimLoLe IxbrReqAxle4_WhlSlipLimLoRi IxbrReqAxle4_VehSpdLgtWhlQltyRi IxbrReqAxle4_IxbrModReq IxbrReqAxle4_VehSpdLgtWhlQltyLe IxbrReqAxle4_WhlSlipLimHiRi;
SIG_GROUP_ 261 IxbrReqAxle2_sg 1 : IxbrReqAxle2_WhlSlipLimHiRi IxbrReqAxle2_BrkTqReqLe IxbrReqAxle2_BrkTqReqRi IxbrReqAxle2_SlipCtrlEna IxbrReqAxle2_WhlSlipLimLoRi IxbrReqAxle2_IxbrModReq IxbrReqAxle2_SqC IxbrReqAxle2_WhlSlipLimLoLe IxbrReqAxle2_VehSpdLgtWhlLe IxbrReqAxle2_WhlSlipLimHiLe IxbrReqAxle2_CRC IxbrReqAxle2_VehSpdLgtWhlQltyLe IxbrReqAxle2_VehSpdLgtWhlRi IxbrReqAxle2_VehSpdLgtWhlQltyRi;
SIG_GROUP_ 261 IxbrReqAxle3_sg 1 : IxbrReqAxle3_BrkTqReqLe IxbrReqAxle3_WhlSlipLimHiLe IxbrReqAxle3_WhlSlipLimLoRi IxbrReqAxle3_BrkTqReqRi IxbrReqAxle3_VehSpdLgtWhlQltyLe IxbrReqAxle3_SqC IxbrReqAxle3_WhlSlipLimLoLe IxbrReqAxle3_VehSpdLgtWhlRi IxbrReqAxle3_WhlSlipLimHiRi IxbrReqAxle3_VehSpdLgtWhlQltyRi IxbrReqAxle3_IxbrModReq IxbrReqAxle3_VehSpdLgtWhlLe IxbrReqAxle3_SlipCtrlEna IxbrReqAxle3_CRC;
SIG_GROUP_ 261 IxbrReqAxle1_sg 1 : IxbrReqAxle1_BrkTqReqLe IxbrReqAxle1_WhlSlipLimLoLe IxbrReqAxle1_VehSpdLgtWhlQltyRi IxbrReqAxle1_WhlSlipLimHiLe IxbrReqAxle1_SlipCtrlEna IxbrReqAxle1_WhlSlipLimLoRi IxbrReqAxle1_IxbrModReq IxbrReqAxle1_SqC IxbrReqAxle1_WhlSlipLimHiRi IxbrReqAxle1_VehSpdLgtWhlLe IxbrReqAxle1_VehSpdLgtWhlQltyLe IxbrReqAxle1_BrkTqReqRi IxbrReqAxle1_VehSpdLgtWhlRi IxbrReqAxle1_CRC;
SIG_GROUP_ 554 EstAxle4_sg 1 : EstAxle4_LoadNormQltyRi EstAxle4_LoadNormRi EstAxle4_WhlRdEstRi EstAxle4_SqC EstAxle4_WhlRdEstQltyRi EstAxle4_WhlRdEstQltyLe EstAxle4_WhlRdEstLe EstAxle4_LoadNormQltyLe EstAxle4_CRC EstAxle4_LoadNormLe;
SIG_GROUP_ 554 EstAxle2_sg 1 : EstAxle2_LoadNormQltyLe EstAxle2_WhlRdEstLe EstAxle2_LoadNormRi EstAxle2_LoadNormLe EstAxle2_LoadNormQltyRi EstAxle2_WhlRdEstQltyRi EstAxle2_WhlRdEstRi EstAxle2_CRC EstAxle2_WhlRdEstQltyLe EstAxle2_SqC;
SIG_GROUP_ 554 EstAxle1_sg 1 : EstAxle1_WhlRdEstRi EstAxle1_LoadNormQltyRi EstAxle1_LoadNormQltyLe EstAxle1_WhlRdEstQltyLe EstAxle1_LoadNormLe EstAxle1_CRC EstAxle1_LoadNormRi EstAxle1_WhlRdEstLe EstAxle1_SqC EstAxle1_WhlRdEstQltyRi;
SIG_GROUP_ 554 EstAxle6_sg 1 : EstAxle6_WhlRdEstQltyRi EstAxle6_SqC EstAxle6_LoadNormRi EstAxle6_CRC EstAxle6_WhlRdEstLe EstAxle6_WhlRdEstQltyLe EstAxle6_LoadNormLe EstAxle6_WhlRdEstRi EstAxle6_LoadNormQltyRi EstAxle6_LoadNormQltyLe;
SIG_GROUP_ 554 EstAxle5_sg 1 : EstAxle5_WhlRdEstQltyRi EstAxle5_SqC EstAxle5_LoadNormQltyRi EstAxle5_LoadNormRi EstAxle5_LoadNormQltyLe EstAxle5_CRC EstAxle5_LoadNormLe EstAxle5_WhlRdEstLe EstAxle5_WhlRdEstRi EstAxle5_WhlRdEstQltyLe;
SIG_GROUP_ 554 EstAxle3_sg 1 : EstAxle3_LoadNormLe EstAxle3_LoadNormQltyRi EstAxle3_WhlRdEstRi EstAxle3_WhlRdEstQltyLe EstAxle3_CRC EstAxle3_LoadNormQltyLe EstAxle3_WhlRdEstQltyRi EstAxle3_LoadNormRi EstAxle3_SqC EstAxle3_WhlRdEstLe;
SIG_GROUP_ 631 XPRGReqPropDemTc_sg 1 : XPRGReqPropDemTc_SqC XPRGReqPropDemTc_TypeControl XPRGReqPropDemTc_CRC XPRGReqPropDemTc_TcPropControl;
SIG_GROUP_ 631 TrsmEngdForPropulsion_sg 1 : TrsmEngdForPropulsion_SqC TrsmEngdForPropulsion_Status TrsmEngdForPropulsion_CRC;
SIG_GROUP_ 631 DriverLocation_sg_ISig_3 1 : DriverLocation_Status_ISig_3 DriverLocation_ConfidenceLvl_ISi DriverLocation_CRC_ISig_3 DriverLocation_SqC_ISig_3;
SIG_GROUP_ 631 XPRGReqMain_sg 1 : XPRGReqMain_AddVlvRelIhnibition XPRGReqMain_PBValveCtrl XPRGReqMain_AddValveCtrlMode XPRGReqMain_CRC XPRGReqMain_AddValveCtrl XPRGReqMain_SqC XPRGReqMain_RequestPriority XPRGReqMain_PBVlvRelInhibition;
SIG_GROUP_ 631 XPRGReqPropDemTl_sg 1 : XPRGReqPropDemTl_TlPropControl XPRGReqPropDemTl_SqC XPRGReqPropDemTl_CRC XPRGReqPropDemTl_TypeControl;
SIG_GROUP_ 1034 ContTrailerBrake_sg 1 : ContTrailerBrake_MsgCounter ContTrailerBrake_MsgChecksum ContTrailerBrake_Request;
SIG_GROUP_ 426 XBRSystemState2_sg 1 : XBRSystemState2_Status XBRSystemState2_CRC XBRSystemState2_SqC;
SIG_GROUP_ 268 SteeringControlMode_sg 1 : SteeringControlMode_CRC SteeringControlMode_Activate SteeringControlMode_SqC SteeringControlMode_Request;
SIG_GROUP_ 268 RoadWheelAngle_sg 1 : RoadWheelAngle_Request RoadWheelAngle_RateRequest RoadWheelAngle_CRC RoadWheelAngle_SqC;
